VERSION ""

NS_ :

BS_:

BU_: Sound_A Ladegeraet_PAG_PF Motor_EDC17_Pirol PSM_Ant_Derivate GW_Routing_Derivate GW_Applikation_Derivate BMS_Hybrid Getriebe_Derivate LEH_Hybrid Motor_MED17_Hybrid Sound_I Tool Airbag Waehlhebel

BO_ 17 WFS_IMS_MSG1: 8 GW_Routing_Derivate
 SG_ WFS_IMS_MSG1 : 0|64@1+ (1,0) [0|1.84467440737096E+019] ""  Motor_EDC17_Pirol,Motor_MED17_Hybrid

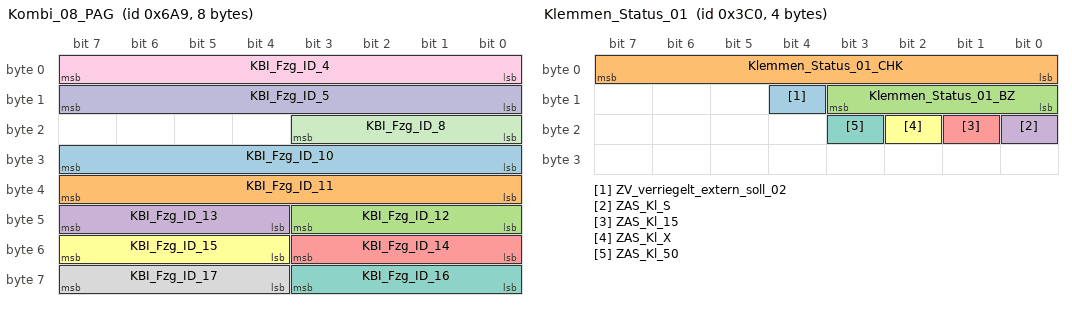
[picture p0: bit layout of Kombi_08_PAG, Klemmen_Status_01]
BO_ 1705 Kombi_08_PAG: 8 GW_Routing_Derivate
 SG_ KBI_Fzg_ID_10 : 24|8@1+ (1,0) [0|255] ""  Waehlhebel
 SG_ KBI_Fzg_ID_11 : 32|8@1+ (1,0) [0|255] ""  Waehlhebel
 SG_ KBI_Fzg_ID_12 : 40|4@1+ (1,0) [0|15] ""  Waehlhebel
 SG_ KBI_Fzg_ID_13 : 44|4@1+ (1,0) [0|15] ""  Waehlhebel
 SG_ KBI_Fzg_ID_14 : 48|4@1+ (1,0) [0|15] ""  Waehlhebel
 SG_ KBI_Fzg_ID_15 : 52|4@1+ (1,0) [0|15] ""  Waehlhebel
 SG_ KBI_Fzg_ID_16 : 56|4@1+ (1,0) [0|15] ""  Waehlhebel
 SG_ KBI_Fzg_ID_17 : 60|4@1+ (1,0) [0|15] ""  Waehlhebel
 SG_ KBI_Fzg_ID_4 : 0|8@1+ (1,0) [0|255] ""  Waehlhebel
 SG_ KBI_Fzg_ID_5 : 8|8@1+ (1,0) [0|255] ""  Waehlhebel
 SG_ KBI_Fzg_ID_8 : 16|4@1+ (1,0) [0|15] ""  Waehlhebel

BO_ 1704 Mem_Kombi_01_PAG: 8 GW_Routing_Derivate
 SG_ KBI_Steigerung_Luftmenge_Fond : 49|1@1+ (1,0) [0|1] "" Vector__XXX
 SG_ KBI_PTC_Zuheizer : 48|1@1+ (1,0) [0|1] "" Vector__XXX
 SG_ KBI_FLA_GLW_Aktiv : 6|1@1+ (1,0) [0|1] "" Vector__XXX
 SG_ KBI_ASD_innen : 44|1@1+ (1,0) [0|0] ""  Sound_I
 SG_ KBI_ASD_aussen : 7|1@1+ (1,0) [0|0] ""  Sound_A
 SG_ KBI_LDW_aktiv : 47|1@1+ (1,0) [0|1] "" Vector__XXX
 SG_ KBI_Jokerkey_Hupe_Aktiv : 46|1@1+ (1,0) [0|1] "" Vector__XXX
 SG_ KBI_Automem_inaktiv : 45|1@1+ (1,0) [0|0] "" Vector__XXX
 SG_ KBI_Heckrollo_b_R : 23|1@1+ (1,0) [0|1] "" Vector__XXX
 SG_ KBI_Klimastyles : 51|2@1+ (1,0) [0|3] "" Vector__XXX
 SG_ KBI_WV_Entr_Kof : 40|4@1+ (1,0) [0|15] "" Vector__XXX
 SG_ KBI_Carjack : 38|2@1+ (1,0) [0|3] "" Vector__XXX
 SG_ KBI_Tuerentr_T : 37|1@1+ (1,0) [0|1] "" Vector__XXX
 SG_ KBI_Einstiegshilfe_aktiv : 4|1@1+ (1,0) [0|1] "" Vector__XXX
 SG_ KBI_FULL_AFS_Tourist : 3|1@1+ (1,0) [0|1] "" Vector__XXX
 SG_ KBI_Aussenspiegel_einklapp_auto : 1|1@1+ (1,0) [0|1] "" Vector__XXX
 SG_ KBI_Aussenspiegel_absenken_auto : 0|1@1+ (1,0) [0|1] "" Vector__XXX
 SG_ KBI_Heckw_b_R : 30|2@1+ (1,0) [0|3] "" Vector__XXX
 SG_ KBI_TFL_akt : 29|1@1+ (1,0) [0|1] "" Vector__XXX
 SG_ KBI_Nachleucht : 24|5@1+ (5,0) [0|120] "s" Vector__XXX
 SG_ KBI_WV_Entr : 32|5@1+ (5,10) [10|100] "s" Vector__XXX
 SG_ KBI_Erw_BelueftFeld : 21|1@1+ (1,0) [0|1] "" Vector__XXX
 SG_ KBI_Mittenduesentemp : 53|3@1- (1,0) [-1|0] "" Vector__XXX
 SG_ KBI_Nachleucht_IL : 16|5@1+ (10,0) [0|300] "s" Vector__XXX
 SG_ KBI_Auto_Umluft : 22|1@1+ (1,0) [0|1] "" Vector__XXX
 SG_ KBI_Schaltpkt_Anz_ein : 2|1@1+ (1,0) [0|1] "" Vector__XXX
 SG_ KBI_RS_d_akt : 15|1@1+ (1,0) [0|1] "" Vector__XXX
 SG_ KBI_Dimmung_OriLicht : 8|7@1+ (1,0) [0|100] "%" Vector__XXX

BO_ 1792 ISO_Funktionaler_Req_All: 8 GW_Routing_Derivate
 SG_ Diag_Rq_Fktnl_Data_UDS : 7|64@0+ (1,0) [0|1.84467440737096E+019] ""  Ladegeraet_PAG_PF,Motor_EDC17_Pirol,Airbag,Motor_MED17_Hybrid,LEH_Hybrid,BMS_Hybrid,Getriebe_Derivate,PSM_Ant_Derivate

BO_ 1424 Kessy_02: 8 GW_Routing_Derivate
 SG_ KYL_Warn_Notzuendschloss : 46|1@1+ (1,0) [0|1] "" Vector__XXX
 SG_ KYL_Notzuendschloss : 45|1@1+ (1,0) [0|1] "" Vector__XXX
 SG_ KY_StartStopp_Info : 43|2@1+ (1,0) [0|3] ""  Motor_EDC17_Pirol,Motor_MED17_Hybrid
 SG_ KY_Funkschl_Nr : 0|4@1+ (1,0) [0|15] "" Vector__XXX
 SG_ KY_ID_Geb_autorisiert : 4|1@1+ (1,0) [0|1] "" Vector__XXX
 SG_ KY_ID_Geb_steckt : 5|1@1+ (1,0) [0|1] "" Vector__XXX
 SG_ KY_FFB_Frequenz : 6|2@1+ (1,0) [0|3] "" Vector__XXX
 SG_ KY_HF_Aktiv : 8|1@1+ (1,0) [0|1] "" Vector__XXX
 SG_ KY_LF_Aktiv : 9|1@1+ (1,0) [0|1] "" Vector__XXX
 SG_ KY_ELV_verr : 10|1@1+ (1,0) [0|1] "" Vector__XXX
 SG_ KY_ELV_entr : 11|1@1+ (1,0) [0|1] "" Vector__XXX
 SG_ KY_ELV_enable_Anforderung : 12|1@1+ (1,0) [0|1] "" Vector__XXX
 SG_ KY_Valet_Parking : 14|1@1+ (1,0) [0|1] "" Vector__XXX
 SG_ KY_Keyless_Verbau : 15|1@1+ (1,0) [0|1] "" Vector__XXX
 SG_ KY_FBS_Fahrer_Hinweise : 16|3@1+ (1,0) [0|7] "" Vector__XXX
 SG_ FBS_Warn_Lenkung_def : 19|1@1+ (1,0) [0|1] "" Vector__XXX
 SG_ FBS_Warn_LenkVerriegelung_def : 20|1@1+ (1,0) [0|1] "" Vector__XXX
 SG_ FBS_Warn_Schluessel_Batt : 21|1@1+ (1,0) [0|1] "" Vector__XXX
 SG_ FBS_Prio_Warn_04 : 22|1@1+ (1,0) [0|1] "" Vector__XXX
 SG_ FBS_Prio_Warn_05 : 23|1@1+ (1,0) [0|1] "" Vector__XXX
 SG_ KY_KYL_Fahrer_Hinweise : 24|3@1+ (1,0) [0|7] "" Vector__XXX
 SG_ KYL_Warn_kein_Schluessel : 27|1@1+ (1,0) [0|1] "" Vector__XXX
 SG_ KYL_Warn_Kessy_defekt : 28|1@1+ (1,0) [0|1] "" Vector__XXX
 SG_ KY_KYL_Prio_Warn_03 : 29|1@1+ (1,0) [0|1] "" Vector__XXX
 SG_ KY_KYL_Prio_Warn_04 : 30|1@1+ (1,0) [0|1] "" Vector__XXX
 SG_ KY_KYL_Prio_Warn_05 : 31|1@1+ (1,0) [0|1] "" Vector__XXX
 SG_ KY_Schluessel_Soll : 32|4@1+ (1,0) [0|15] "" Vector__XXX
 SG_ KY_Schluessel_Ist : 36|4@1+ (1,0) [0|15] "" Vector__XXX
 SG_ KY_WFS_Safe : 40|1@1+ (1,0) [0|1] "" Vector__XXX
 SG_ KY_WFS_LZ : 41|2@1+ (1,0) [0|3] "" Vector__XXX
 SG_ FBS_KD_Fehler : 47|1@1+ (1,0) [0|1] "" Vector__XXX
 SG_ SK_Anf_DTC_Abfrage_sofort : 49|1@1+ (1,0) [0|1] "" Vector__XXX
 SG_ SK_Anf_DTC_Abfrage : 48|1@1+ (1,0) [0|1] "" Vector__XXX

BO_ 960 Klemmen_Status_01: 4 GW_Routing_Derivate
 SG_ ZV_verriegelt_extern_soll_02 : 12|1@1+ (1,0) [0|1] "" Vector__XXX
 SG_ Klemmen_Status_01_CHK : 0|8@1+ (1,0) [0|255] ""  LEH_Hybrid,BMS_Hybrid,Motor_EDC17_Pirol,Motor_MED17_Hybrid
 SG_ Klemmen_Status_01_BZ : 8|4@1+ (1,0) [0|15] ""  LEH_Hybrid,BMS_Hybrid,Motor_EDC17_Pirol,Motor_MED17_Hybrid
 SG_ ZAS_Kl_S : 16|1@1+ (1,0) [0|1] "" Vector__XXX
 SG_ ZAS_Kl_15 : 17|1@1+ (1,0) [0|1] ""  Ladegeraet_PAG_PF,Sound_A,Sound_I,LEH_Hybrid,BMS_Hybrid,Motor_EDC17_Pirol,Motor_MED17_Hybrid
 SG_ ZAS_Kl_X : 18|1@1+ (1,0) [0|1] "" Vector__XXX
 SG_ ZAS_Kl_50 : 19|1@1+ (1,0) [0|1] ""  Sound_A,Sound_I,LEH_Hybrid,Motor_EDC17_Pirol,Waehlhebel,Motor_MED17_Hybrid,Ladegeraet_PAG_PF

BO_ 1137 Licht_hinten_01: 8 GW_Routing_Derivate
 SG_ LH_Aussenlicht_def : 7|1@1+ (1,0) [0|1] "" Vector__XXX
 SG_ LH_Standlicht_H_aktiv : 8|1@1+ (1,0) [0|1] "" Vector__XXX
 SG_ LH_SL_BRL_BLK_re_def : 42|1@1+ (1,0) [0|1] "" Vector__XXX
 SG_ LH_SL_BRL_BLK_li_def : 26|1@1+ (1,0) [0|1] "" Vector__XXX
 SG_ LH_Schluss_Nebel_re_def : 41|1@1+ (1,0) [0|1] "" Vector__XXX
 SG_ LH_Schluss_Nebel_li_def : 25|1@1+ (1,0) [0|1] "" Vector__XXX
 SG_ LH_Schluss_Brems_re_def : 40|1@1+ (1,0) [0|1] "" Vector__XXX
 SG_ LH_Schluss_Brems_Nebel_re_def : 22|1@1+ (1,0) [0|1] "" Vector__XXX
 SG_ LH_Schluss_Brems_Nebel_li_def : 21|1@1+ (1,0) [0|1] "" Vector__XXX
 SG_ LH_Schluss_Brems_li_def : 24|1@1+ (1,0) [0|1] "" Vector__XXX
 SG_ LH_Rueckfahrlicht_aktiv : 13|1@1+ (1,0) [0|1] "" Vector__XXX
 SG_ LH_Rueckf_mi_def : 51|1@1+ (1,0) [0|1] "" Vector__XXX
 SG_ LH_Parklicht_HR_aktiv : 10|1@1+ (1,0) [0|1] "" Vector__XXX
 SG_ LH_Parklicht_HL_aktiv : 9|1@1+ (1,0) [0|1] "" Vector__XXX
 SG_ LH_Nebelschluss_aktiv : 12|1@1+ (1,0) [0|1] "" Vector__XXX
 SG_ LH_Nebel_mi_def : 50|1@1+ (1,0) [0|1] "" Vector__XXX
 SG_ LH_Bremslicht_H_aktiv : 11|1@1+ (1,0) [0|1] "" Vector__XXX
 SG_ LH_Brems_Blk_re_def : 43|1@1+ (1,0) [0|1] "" Vector__XXX
 SG_ LH_Brems_Blk_li_def : 27|1@1+ (1,0) [0|1] "" Vector__XXX
 SG_ LH_Blinker_re_def : 32|1@1+ (1,0) [0|1] "" Vector__XXX
 SG_ LH_Blinker_li_def : 16|1@1+ (1,0) [0|1] "" Vector__XXX
 SG_ LH_Blinker_HR_akt : 15|1@1+ (1,0) [0|1] "" Vector__XXX
 SG_ LH_Blinker_HL_akt : 14|1@1+ (1,0) [0|1] "" Vector__XXX
 SG_ BCM2_Bremsl_durch_ECD : 5|1@1+ (1,0) [0|1] ""  Motor_EDC17_Pirol,Motor_MED17_Hybrid
 SG_ LH_Bremsl_re_ges_def : 55|1@1+ (1,0) [0|1] ""  Motor_EDC17_Pirol,Motor_MED17_Hybrid
 SG_ LH_Bremsl_li_ges_def : 54|1@1+ (1,0) [0|1] ""  Motor_EDC17_Pirol,Motor_MED17_Hybrid
 SG_ Licht_hinten_01_BZ : 0|4@1+ (1,0) [0|15] ""  Motor_EDC17_Pirol,Motor_MED17_Hybrid
 SG_ LH_Bremsl_li_def : 17|1@1+ (1,0) [0|1] "" Vector__XXX
 SG_ LH_Schlusslicht_li_def : 18|1@1+ (1,0) [0|1] "" Vector__XXX
 SG_ LH_Rueckf_li_def : 19|1@1+ (1,0) [0|1] "" Vector__XXX
 SG_ LH_Nebel_li_def : 20|1@1+ (1,0) [0|1] "" Vector__XXX
 SG_ LH_Bremsl_re_def : 33|1@1+ (1,0) [0|1] "" Vector__XXX
 SG_ LH_Schlusslicht_re_def : 34|1@1+ (1,0) [0|1] "" Vector__XXX
 SG_ LH_Rueckf_re_def : 35|1@1+ (1,0) [0|1] "" Vector__XXX
 SG_ LH_Nebel_re_def : 36|1@1+ (1,0) [0|1] "" Vector__XXX
 SG_ LH_Kennzl_def : 48|1@1+ (1,0) [0|1] "" Vector__XXX
 SG_ LH_3_Bremsl_def : 49|1@1+ (1,0) [0|1] ""  Motor_EDC17_Pirol,Motor_MED17_Hybrid

BO_ 1742 NMH_BMS: 7 BMS_Hybrid
 SG_ NMH_BMS_NL_Daten_EEPROM : 24|1@1+ (1,0) [0|1] "" Vector__XXX
 SG_ NMH_BMS_NL_Luefter : 25|1@1+ (1,0) [0|1] "" Vector__XXX
 SG_ NMH_BMS_Signalfehler : 32|1@1+ (1,0) [0|1] "" Vector__XXX
 SG_ NMH_BMS_TimeOut_Fehler : 33|1@1+ (1,0) [0|1] "" Vector__XXX
 SG_ NMH_BMS_CAN_Diag_deaktiv : 34|1@1+ (1,0) [0|1] "" Vector__XXX
 SG_ NMH_BMS_KompSchutz : 35|1@1+ (1,0) [0|1] "" Vector__XXX
 SG_ NMH_BMS_Mute_Mode : 36|1@1+ (1,0) [0|1] "" Vector__XXX
 SG_ NMH_BMS_Transport_Mode : 37|1@1+ (1,0) [0|1] "" Vector__XXX
 SG_ NMH_BMS_Abschaltstufe_aktiv : 38|1@1+ (1,0) [0|1] "" Vector__XXX
 SG_ NMH_BMS_Busfehler : 39|1@1+ (1,0) [0|1] "" Vector__XXX
 SG_ NMH_BMS_Lokalaktiv : 48|1@1+ (1,0) [0|1] "" Vector__XXX
 SG_ NMH_BMS_Subsystemaktiv : 49|1@1+ (1,0) [0|1] "" Vector__XXX
 SG_ NMH_BMS_Start_1 : 0|1@1+ (1,0) [0|1] ""  Getriebe_Derivate,LEH_Hybrid,Ladegeraet_PAG_PF,Motor_MED17_Hybrid,GW_Applikation_Derivate
 SG_ NMH_BMS_Start_2 : 1|1@1+ (1,0) [0|1] ""  GW_Applikation_Derivate
 SG_ NMH_BMS_Normal_Mode_1 : 2|1@1+ (1,0) [0|1] ""  GW_Applikation_Derivate
 SG_ NMH_BMS_Normal_Mode_2 : 3|1@1+ (1,0) [0|1] ""  GW_Applikation_Derivate
 SG_ NMH_BMS_Car_WakeUp : 6|1@1+ (1,0) [0|1] "" Vector__XXX
 SG_ NMH_BMS_Per_WakeUp : 8|5@1+ (1,0) [0|31] "" Vector__XXX
 SG_ NMH_BMS_Fkt_WakeUp : 13|3@1+ (1,0) [0|7] "" Vector__XXX
 SG_ NMH_BMS_Klemme_15 : 16|1@1+ (1,0) [0|1] "" Vector__XXX
 SG_ NMH_BMS_Diagnose : 17|1@1+ (1,0) [0|1] "" Vector__XXX
 SG_ NMH_BMS_MindestAktivZeit : 18|1@1+ (1,0) [0|1] "" Vector__XXX

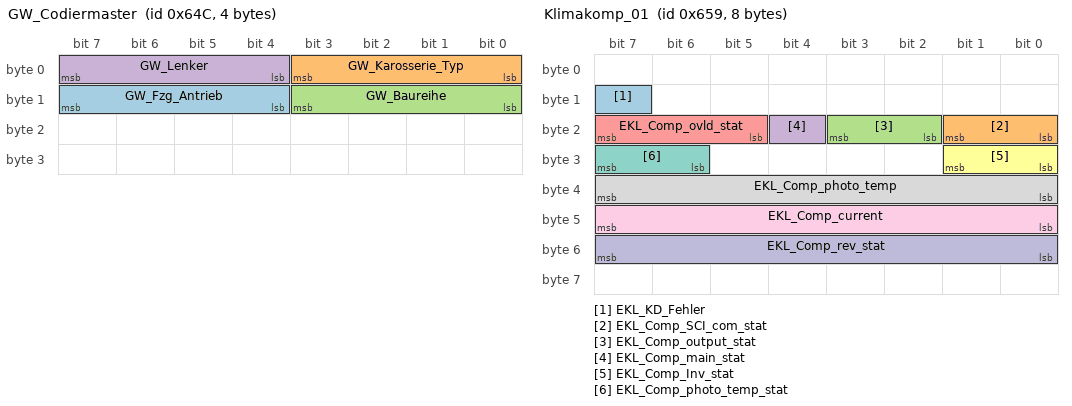
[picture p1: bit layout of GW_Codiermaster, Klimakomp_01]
BO_ 1612 GW_Codiermaster: 4 GW_Applikation_Derivate
 SG_ GW_Fzg_Antrieb : 12|4@1+ (1,0) [0|15] ""  PSM_Ant_Derivate
 SG_ GW_Karosserie_Typ : 0|4@1+ (1,0) [0|15] ""  PSM_Ant_Derivate
 SG_ GW_Baureihe : 8|4@1+ (1,0) [0|15] ""  BMS_Hybrid,PSM_Ant_Derivate
 SG_ GW_Lenker : 4|4@1+ (1,0) [0|15] ""  PSM_Ant_Derivate,Airbag

BO_ 1009 Diagnose_02_PAG: 2 GW_Applikation_Derivate
 SG_ GW_STH_Anf : 0|2@1+ (1,0) [0|3] ""  Ladegeraet_PAG_PF
 SG_ FSAktivBit : 9|1@1+ (1,0) [0|1] ""  Airbag,Waehlhebel

BO_ 1625 Klimakomp_01: 8 GW_Routing_Derivate
 SG_ EKL_KD_Fehler : 15|1@1+ (1,0) [0|1] "" Vector__XXX
 SG_ EKL_Comp_SCI_com_stat : 16|2@1+ (1,0) [0|3] "" Vector__XXX
 SG_ EKL_Comp_output_stat : 18|2@1+ (1,0) [0|3] "" Vector__XXX
 SG_ EKL_Comp_main_stat : 20|1@1+ (1,0) [0|1] "" Vector__XXX
 SG_ EKL_Comp_ovld_stat : 21|3@1+ (1,0) [0|7] "" Vector__XXX
 SG_ EKL_Comp_Inv_stat : 24|2@1+ (1,0) [0|3] "" Vector__XXX
 SG_ EKL_Comp_photo_temp_stat : 30|2@1+ (1,0) [0|3] "" Vector__XXX
 SG_ EKL_Comp_photo_temp : 32|8@1+ (1,0) [0|254] "Unit_DegreCelsi" Vector__XXX
 SG_ EKL_Comp_current : 40|8@1+ (0.1,0) [0|25.4] "Unit_Amper"  Ladegeraet_PAG_PF,Motor_MED17_Hybrid,BMS_Hybrid
 SG_ EKL_Comp_rev_stat : 48|8@1+ (50,0) [0|8600] "Unit_MinutInver"  BMS_Hybrid

BO_ 2617027073 DEV_AB_TX_02: 8 Airbag
 SG_ AB_EB2_Tx_Data : 0|64@1+ (1,0) [0|1.84467440737096E+019] "" Vector__XXX

BO_ 2617027072 DEV_AB_TX_01: 8 Airbag
 SG_ AB_EB1_Tx_Data : 0|64@1+ (1,0) [0|1.84467440737096E+019] "" Vector__XXX

BO_ 1793 ISO_Funktionaler_Req_KWP2000: 8 GW_Routing_Derivate
 SG_ Diag_Rq_Fktnl_Data_KWP2000 : 7|64@0+ (1,0) [0|1.84467440737096E+019] ""  Waehlhebel

BO_ 2015 ISO_Funktionaler_Req_OBD: 8 GW_Routing_Derivate
 SG_ Diag_Rq_Fktnl_Data_OBD : 7|64@0+ (1,0) [0|1.84467440737096E+019] ""  Ladegeraet_PAG_PF,Motor_EDC17_Pirol,Getriebe_Derivate,Motor_MED17_Hybrid,LEH_Hybrid,BMS_Hybrid

BO_ 905 GW_Ant_01: 8 GW_Routing_Derivate
 SG_ EPB_Anfahrwunsch_erkannt : 30|1@1+ (1,0) [0|1] "" Vector__XXX
 SG_ EPB_QBit_Schalterpos : 7|1@1+ (1,0) [0|1] "" Vector__XXX
 SG_ EPB_Schalterposition : 5|2@1+ (1,0) [0|3] "" Vector__XXX
 SG_ EPB_Freig_Verzoeg_Anf : 18|1@1+ (1,0) [0|1] "" Vector__XXX
 SG_ KL_Segeln_Anf_deaktivieren : 4|1@1+ (1,0) [0|1] "" Vector__XXX
 SG_ KL_T_Abgasklappe : 38|1@1+ (1,0) [0|1] "" Vector__XXX
 SG_ DK_PAO_Signalzaehler : 24|4@1+ (1,0) [0|15] ""  Airbag
 SG_ KL_St_Atemp : 32|3@1+ (1,0) [0|4] "" Vector__XXX
 SG_ KL_Komp_ein : 36|1@1+ (1,0) [0|1] "" Vector__XXX
 SG_ KL_Drehz_Anh : 37|1@1+ (1,0) [0|1] "" Vector__XXX
 SG_ KL_Anf_KL : 48|8@1+ (0.4,0) [0|100] "%" Vector__XXX
 SG_ KL_KaeltemittelDruck : 40|8@1+ (0.2,0) [0|50.8] "bar" Vector__XXX
 SG_ DK_St_PAO_Leuchte : 28|2@1+ (1,0) [0|3] ""  Airbag
 SG_ KL_Sportmodus : 19|3@1+ (1,0) [0|7] ""  PSM_Ant_Derivate
 SG_ F_EPB_01_Ant : 59|1@1+ (1,0) [0|1] "" Vector__XXX
 SG_ EPB_Status : 16|2@1+ (1,0) [0|3] "" Vector__XXX
 SG_ F_Klima_03_Ant : 62|1@1+ (1,0) [0|1] "" Vector__XXX
 SG_ KL_Magnetventil : 35|1@1+ (1,0) [0|1] "" Vector__XXX
 SG_ KL_T_PSM_off : 3|1@1+ (1,0) [0|1] ""  PSM_Ant_Derivate
 SG_ KL_F_Komp_Endst : 39|1@1+ (1,0) [0|1] "" Vector__XXX
 SG_ F_Klima_01_1_Ant : 60|1@1+ (1,0) [0|1] "" Vector__XXX
 SG_ F_Klima_08_1_PAG_Ant : 63|1@1+ (1,0) [0|1] ""  PSM_Ant_Derivate
 SG_ F_BCM2_03_PAG_Ant : 57|1@1+ (1,0) [0|1] ""  Airbag
 SG_ KL_Last_Kompr : 8|8@1+ (0.25,0) [0|63.5] "Nm" Vector__XXX
 SG_ KL_STH_Ansteuerung : 1|2@1+ (1,0) [0|3] "" Vector__XXX
 SG_ KL_STH_aktiv : 0|1@1+ (1,0) [0|1] "" Vector__XXX
 SG_ EPB_Fehlerstatus : 22|2@1+ (1,0) [0|3] "" Vector__XXX

BO_ 18 GSG_WFS_Anfrage: 8 Getriebe_Derivate
 SG_ WFS_GSG_RND : 0|32@1+ (1,0) [0|4294967295] "" Vector__XXX
 SG_ WFS_GSG_CRC : 32|32@1+ (1,0) [0|4294967295] "" Vector__XXX

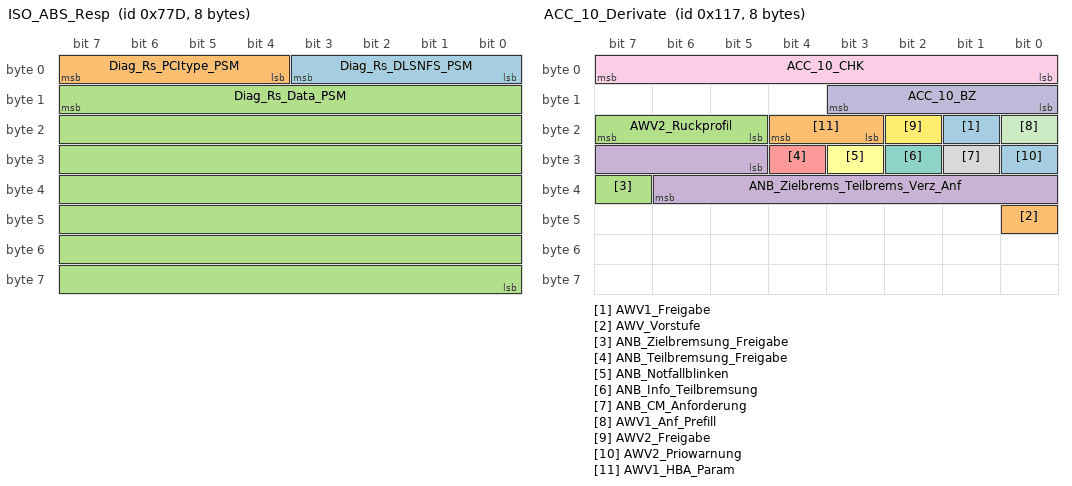
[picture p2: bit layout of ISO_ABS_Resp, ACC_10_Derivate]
BO_ 1917 ISO_ABS_Resp: 8 PSM_Ant_Derivate
 SG_ Diag_Rs_DLSNFS_PSM : 3|4@0+ (1,0) [0|15] ""  GW_Routing_Derivate
 SG_ Diag_Rs_PCItype_PSM : 7|4@0+ (1,0) [0|15] ""  GW_Routing_Derivate
 SG_ Diag_Rs_Data_PSM : 15|56@0+ (1,0) [0|7.20575940379279E+016] ""  GW_Routing_Derivate

BO_ 2025 ISO_Getriebe_01_Resp: 8 Getriebe_Derivate
 SG_ ISO_Getriebe_01_Resp_Data : 0|64@1+ (1,0) [0|1.84467440737096E+019] ""  GW_Routing_Derivate

BO_ 2024 ISO_MO_01_Resp: 8 Motor_MED17_Hybrid
 SG_ ISO_MO_01_Resp_Data : 0|64@1+ (1,0) [0|1.84467440737096E+019] ""  GW_Routing_Derivate

BO_ 279 ACC_10_Derivate: 8 GW_Routing_Derivate
 SG_ AWV1_Freigabe : 17|1@1+ (1,0) [0|1] ""  PSM_Ant_Derivate
 SG_ AWV_Vorstufe : 40|1@1+ (1,0) [0|1] ""  PSM_Ant_Derivate
 SG_ ANB_Zielbremsung_Freigabe : 39|1@1+ (1,0) [0|1] ""  PSM_Ant_Derivate
 SG_ ANB_Zielbrems_Teilbrems_Verz_Anf : 29|10@1+ (0.024,-20.016) [-20.016|4.536] "Unit_MeterPerSeconSquar"  PSM_Ant_Derivate
 SG_ ANB_Teilbremsung_Freigabe : 28|1@1+ (1,0) [0|1] ""  PSM_Ant_Derivate
 SG_ ANB_Notfallblinken : 27|1@1+ (1,0) [0|1] ""  PSM_Ant_Derivate
 SG_ ANB_Info_Teilbremsung : 26|1@1+ (1,0) [0|1] ""  PSM_Ant_Derivate
 SG_ ANB_CM_Anforderung : 25|1@1+ (1,0) [0|1] "" Vector__XXX
 SG_ ACC_10_CHK : 0|8@1+ (1,0) [0|255] ""  PSM_Ant_Derivate
 SG_ ACC_10_BZ : 8|4@1+ (1,0) [0|15] ""  PSM_Ant_Derivate
 SG_ AWV1_Anf_Prefill : 16|1@1+ (1,0) [0|1] ""  PSM_Ant_Derivate
 SG_ AWV2_Freigabe : 18|1@1+ (1,0) [0|1] ""  PSM_Ant_Derivate
 SG_ AWV2_Priowarnung : 24|1@1+ (1,0) [0|1] ""  PSM_Ant_Derivate
 SG_ AWV1_HBA_Param : 19|2@1+ (1,0) [0|3] ""  PSM_Ant_Derivate
 SG_ AWV2_Ruckprofil : 21|3@1+ (1,0) [0|7] ""  PSM_Ant_Derivate

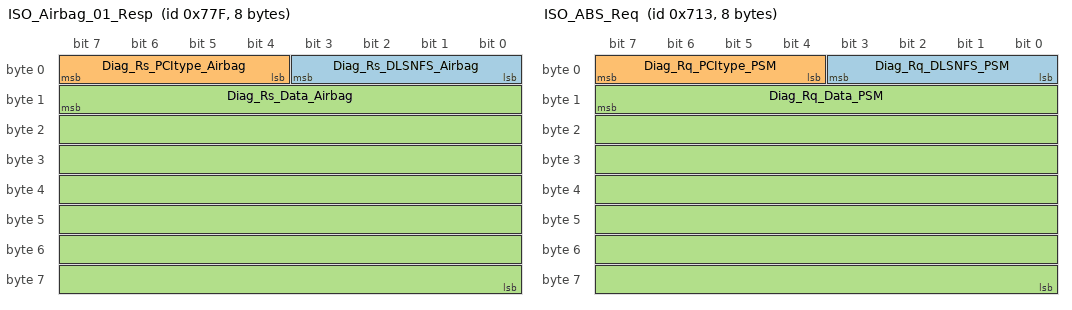
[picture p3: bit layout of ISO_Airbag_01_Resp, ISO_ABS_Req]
BO_ 1919 ISO_Airbag_01_Resp: 8 Airbag
 SG_ Diag_Rs_DLSNFS_Airbag : 3|4@0+ (1,0) [0|15] ""  GW_Routing_Derivate
 SG_ Diag_Rs_PCItype_Airbag : 7|4@0+ (1,0) [0|15] ""  GW_Routing_Derivate
 SG_ Diag_Rs_Data_Airbag : 15|56@0+ (1,0) [0|7.20575940379279E+016] ""  GW_Routing_Derivate

BO_ 1811 ISO_ABS_Req: 8 GW_Routing_Derivate
 SG_ Diag_Rq_DLSNFS_PSM : 3|4@0+ (1,0) [0|15] ""  PSM_Ant_Derivate
 SG_ Diag_Rq_PCItype_PSM : 7|4@0+ (1,0) [0|15] ""  PSM_Ant_Derivate
 SG_ Diag_Rq_Data_PSM : 15|56@0+ (1,0) [0|7.20575940379279E+016] ""  PSM_Ant_Derivate

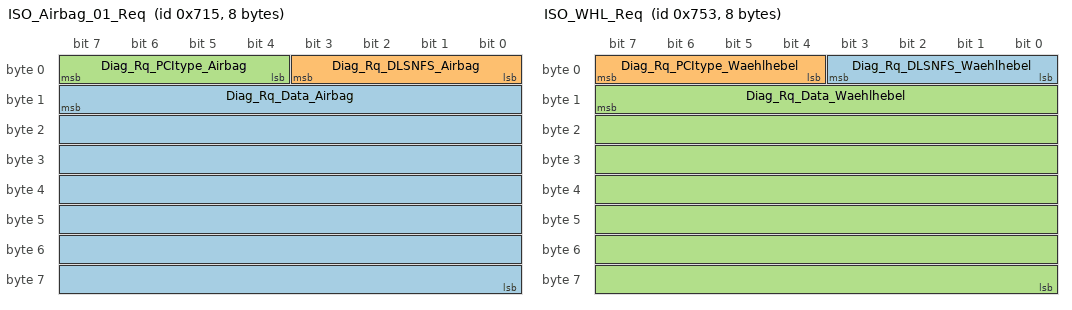
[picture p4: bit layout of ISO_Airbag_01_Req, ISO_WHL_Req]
BO_ 1813 ISO_Airbag_01_Req: 8 GW_Routing_Derivate
 SG_ Diag_Rq_Data_Airbag : 15|56@0+ (1,0) [0|7.20575940379279E+016] ""  Airbag
 SG_ Diag_Rq_DLSNFS_Airbag : 3|4@0+ (1,0) [0|15] ""  Airbag
 SG_ Diag_Rq_PCItype_Airbag : 7|4@0+ (1,0) [0|15] ""  Airbag

BO_ 1875 ISO_WHL_Req: 8 GW_Routing_Derivate
 SG_ Diag_Rq_DLSNFS_Waehlhebel : 3|4@0+ (1,0) [0|15] ""  Waehlhebel
 SG_ Diag_Rq_PCItype_Waehlhebel : 7|4@0+ (1,0) [0|15] ""  Waehlhebel
 SG_ Diag_Rq_Data_Waehlhebel : 15|56@0+ (1,0) [0|7.20575940379279E+016] ""  Waehlhebel

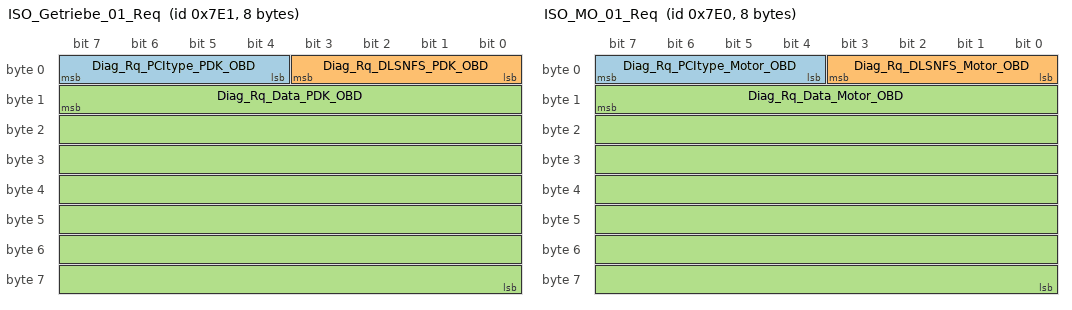
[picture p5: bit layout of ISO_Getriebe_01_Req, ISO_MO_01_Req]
BO_ 2017 ISO_Getriebe_01_Req: 8 GW_Routing_Derivate
 SG_ Diag_Rq_PCItype_PDK_OBD : 7|4@0+ (1,0) [0|15] ""  Getriebe_Derivate
 SG_ Diag_Rq_DLSNFS_PDK_OBD : 3|4@0+ (1,0) [0|15] ""  Getriebe_Derivate
 SG_ Diag_Rq_Data_PDK_OBD : 15|56@0+ (1,0) [0|7.20575940379279E+016] ""  Getriebe_Derivate

BO_ 2016 ISO_MO_01_Req: 8 GW_Routing_Derivate
 SG_ Diag_Rq_PCItype_Motor_OBD : 7|4@0+ (1,0) [0|15] ""  Motor_EDC17_Pirol,Motor_MED17_Hybrid
 SG_ Diag_Rq_DLSNFS_Motor_OBD : 3|4@0+ (1,0) [0|15] ""  Motor_EDC17_Pirol,Motor_MED17_Hybrid
 SG_ Diag_Rq_Data_Motor_OBD : 15|56@0+ (1,0) [0|7.20575940379279E+016] ""  Motor_EDC17_Pirol,Motor_MED17_Hybrid

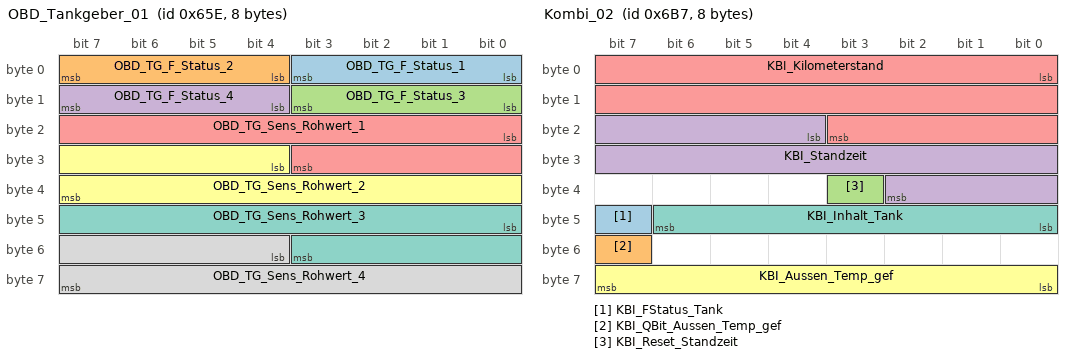
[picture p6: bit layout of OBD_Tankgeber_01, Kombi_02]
BO_ 1630 OBD_Tankgeber_01: 8 GW_Routing_Derivate
 SG_ OBD_TG_F_Status_1 : 0|4@1+ (1,0) [0|15] ""  Motor_MED17_Hybrid
 SG_ OBD_TG_F_Status_2 : 4|4@1+ (1,0) [0|15] ""  Motor_MED17_Hybrid
 SG_ OBD_TG_F_Status_3 : 8|4@1+ (1,0) [0|15] ""  Motor_MED17_Hybrid
 SG_ OBD_TG_F_Status_4 : 12|4@1+ (1,0) [0|15] ""  Motor_MED17_Hybrid
 SG_ OBD_TG_Sens_Rohwert_1 : 16|12@1+ (0.5,0) [0|2047.5] "Unit_Ohm"  Motor_MED17_Hybrid
 SG_ OBD_TG_Sens_Rohwert_2 : 28|12@1+ (0.5,0) [0|2047.5] "Unit_Ohm"  Motor_MED17_Hybrid
 SG_ OBD_TG_Sens_Rohwert_3 : 40|12@1+ (0.5,0) [0|2047.5] "Unit_Ohm"  Motor_MED17_Hybrid
 SG_ OBD_TG_Sens_Rohwert_4 : 52|12@1+ (0.5,0) [0|2047.5] "Unit_Ohm"  Motor_MED17_Hybrid

BO_ 1607 Motor_09_VW: 8 Motor_MED17_Hybrid
 SG_ MO_Kraftstofffilter_Wasser : 40|1@1+ (1,0) [0|1] ""  GW_Routing_Derivate
 SG_ MO_ITM_Kuehlmittel_Temp : 0|8@1+ (0.75,-48) [-45.75|143.25] "Unit_DegreCelsi"  GW_Routing_Derivate
 SG_ MO_CO2_Faktor : 44|12@1+ (1,0) [1|4094] "Unit_GramPerLiter"  GW_Routing_Derivate
 SG_ MO_E85_Sensor : 8|4@1+ (1,0) [0|10] "Unit_PerCent"  GW_Routing_Derivate
 SG_ SCR_Anz_Motorstarts : 12|4@1+ (1,0) [0|8] ""  GW_Routing_Derivate
 SG_ SCR_Reichweite : 16|15@1+ (1,0) [0|32766] ""  GW_Routing_Derivate
 SG_ SCR_Warnstufe_1 : 32|1@1+ (1,0) [0|1] ""  GW_Routing_Derivate
 SG_ SCR_Warnstufe_2 : 33|1@1+ (1,0) [0|1] ""  GW_Routing_Derivate
 SG_ SCR_Inducement_Strategie : 42|2@1+ (1,0) [0|3] ""  GW_Routing_Derivate
 SG_ MO_MKB_MUX M : 56|2@1+ (1,0) [0|3] ""  GW_Routing_Derivate
 SG_ MO_MKB_01 m0 : 59|5@1+ (1,0) [0|31] ""  GW_Routing_Derivate
 SG_ MO_MKB_02 m1 : 59|5@1+ (1,0) [0|31] ""  GW_Routing_Derivate
 SG_ SCR_Text : 34|3@1+ (1,0) [0|7] ""  GW_Routing_Derivate
 SG_ SCR_Akustik : 37|2@1+ (1,0) [0|3] ""  GW_Routing_Derivate
 SG_ SCR_Systemfehler : 41|1@1+ (1,0) [0|1] ""  GW_Routing_Derivate
 SG_ MO_MKB_04 m3 : 59|5@1+ (1,0) [0|31] ""  GW_Routing_Derivate
 SG_ MO_MKB_03 m2 : 59|5@1+ (1,0) [0|31] ""  GW_Routing_Derivate

BO_ 269 ACC_05: 8 GW_Routing_Derivate
 SG_ ACC_Vorbefuellung_Bremsanlage : 47|1@1+ (1,0) [0|1] "" Vector__XXX
 SG_ ACC_StartStopp_Info : 44|2@1+ (1,0) [0|3] ""  Motor_MED17_Hybrid,Motor_EDC17_Pirol
 SG_ ACC_KD_Fehler : 63|1@1+ (1,0) [0|1] "" Vector__XXX
 SG_ ACC_Anhalten : 62|1@1+ (1,0) [0|1] ""  PSM_Ant_Derivate
 SG_ ACC_Beeinflussung_ESP : 61|1@1+ (1,0) [0|1] "" Vector__XXX
 SG_ ACC_Betaetigung_EPB : 60|1@1+ (1,0) [0|1] ""  Motor_EDC17_Pirol,Motor_MED17_Hybrid
 SG_ ACC_Status_ACC : 57|3@1+ (1,0) [0|7] ""  Getriebe_Derivate,Motor_MED17_Hybrid,Motor_EDC17_Pirol
 SG_ ACC_ax_Getriebe : 48|9@1+ (0.024,-2.016) [-2.016|10.248] "Unit_MeterPerSeconSquar"  Getriebe_Derivate
 SG_ ACC_Loeseanforderung : 43|1@1+ (1,0) [0|1] ""  PSM_Ant_Derivate
 SG_ ACC_Verz_anf : 32|11@1+ (0.005,-7.22) [-7.22|3.015] "Unit_MeterPerSeconSquar"  PSM_Ant_Derivate
 SG_ ACC_zul_Regelabw : 26|6@1+ (0.024,0) [0|1.512] "Unit_MeterPerSeconSquar" Vector__XXX
 SG_ ACC_Momentenanforderung : 16|10@1+ (1,0) [0|1021] ""  Motor_MED17_Hybrid,Motor_EDC17_Pirol
 SG_ ACC_limitierte_Anfahrdyn : 15|1@1+ (1,0) [0|1] ""  Motor_EDC17_Pirol,Motor_MED17_Hybrid
 SG_ ACC_Getriebestellung_P : 14|1@1+ (1,0) [0|1] "" Vector__XXX
 SG_ ACC_Freigabe_Verzanf : 13|1@1+ (1,0) [0|1] ""  Getriebe_Derivate
 SG_ ACC_Freigabe_Momentenanf : 12|1@1+ (1,0) [0|1] ""  Motor_EDC17_Pirol,Motor_MED17_Hybrid
 SG_ ACC_05_CHK : 0|8@1+ (1,0) [0|255] ""  Motor_EDC17_Pirol,PSM_Ant_Derivate,Getriebe_Derivate,Motor_MED17_Hybrid
 SG_ ACC_05_BZ : 8|4@1+ (1,0) [0|15] ""  Motor_EDC17_Pirol,PSM_Ant_Derivate,Getriebe_Derivate,Motor_MED17_Hybrid

BO_ 1719 Kombi_02: 8 GW_Routing_Derivate
 SG_ KBI_FStatus_Tank : 47|1@1+ (1,0) [0|1] ""  Motor_EDC17_Pirol,Motor_MED17_Hybrid
 SG_ KBI_QBit_Aussen_Temp_gef : 55|1@1+ (1,0) [0|1] ""  Motor_EDC17_Pirol,Motor_MED17_Hybrid,BMS_Hybrid
 SG_ KBI_Reset_Standzeit : 35|1@1+ (1,0) [0|1] ""  Motor_EDC17_Pirol,Motor_MED17_Hybrid
 SG_ KBI_Standzeit : 20|15@1+ (4,0) [0|131068] "Unit_Seconds"  Motor_EDC17_Pirol,Motor_MED17_Hybrid
 SG_ KBI_Kilometerstand : 0|20@1+ (1,0) [0|1048573] "km"  Getriebe_Derivate
 SG_ KBI_Aussen_Temp_gef : 56|8@1+ (0.5,-50) [-50|75] "°C"  Motor_EDC17_Pirol,Motor_MED17_Hybrid,BMS_Hybrid
 SG_ KBI_Inhalt_Tank : 40|7@1+ (1,0) [0|126] "Liter"  Motor_EDC17_Pirol,Motor_MED17_Hybrid

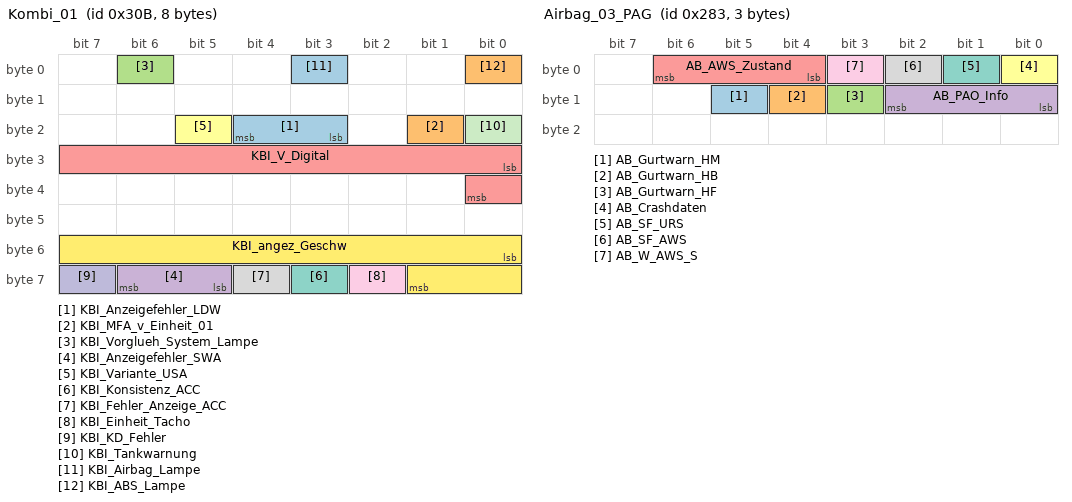
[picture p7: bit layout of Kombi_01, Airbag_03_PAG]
BO_ 779 Kombi_01: 8 GW_Routing_Derivate
 SG_ KBI_Anzeigefehler_LDW : 19|2@1+ (1,0) [0|3] "" Vector__XXX
 SG_ KBI_MFA_v_Einheit_01 : 17|1@1+ (1,0) [0|1] "" Vector__XXX
 SG_ KBI_Vorglueh_System_Lampe : 6|1@1+ (1,0) [0|1] ""  Motor_EDC17_Pirol
 SG_ KBI_Anzeigefehler_SWA : 61|2@1+ (1,0) [0|3] "" Vector__XXX
 SG_ KBI_V_Digital : 24|9@1+ (1,0) [0|511] "" Vector__XXX
 SG_ KBI_Variante_USA : 21|1@1+ (1,0) [0|1] "" Vector__XXX
 SG_ KBI_Konsistenz_ACC : 59|1@1+ (1,0) [0|1] "" Vector__XXX
 SG_ KBI_Fehler_Anzeige_ACC : 60|1@1+ (1,0) [0|1] ""  Motor_EDC17_Pirol,Motor_MED17_Hybrid
 SG_ KBI_Einheit_Tacho : 58|1@1+ (1,0) [0|1] ""  Motor_EDC17_Pirol,Motor_MED17_Hybrid
 SG_ KBI_KD_Fehler : 63|1@1+ (1,0) [0|1] "" Vector__XXX
 SG_ KBI_Tankwarnung : 16|1@1+ (1,0) [0|1] ""  Motor_EDC17_Pirol,Motor_MED17_Hybrid
 SG_ KBI_angez_Geschw : 48|10@1+ (0.32,0) [0|325] "km/h"  Motor_EDC17_Pirol,Getriebe_Derivate,Motor_MED17_Hybrid
 SG_ KBI_Airbag_Lampe : 3|1@1+ (1,0) [0|1] "" Vector__XXX
 SG_ KBI_ABS_Lampe : 0|1@1+ (1,0) [0|1] "" Vector__XXX

BO_ 643 Airbag_03_PAG: 3 Airbag
 SG_ AB_Gurtwarn_HM : 13|1@1+ (1,0) [0|1] ""  GW_Routing_Derivate
 SG_ AB_Gurtwarn_HB : 12|1@1+ (1,0) [0|1] ""  GW_Routing_Derivate
 SG_ AB_Gurtwarn_HF : 11|1@1+ (1,0) [0|1] ""  GW_Routing_Derivate
 SG_ AB_PAO_Info : 8|3@1+ (1,0) [0|7] ""  GW_Routing_Derivate
 SG_ AB_AWS_Zustand : 4|3@1+ (1,0) [0|7] ""  GW_Routing_Derivate
 SG_ AB_Crashdaten : 0|1@1+ (1,0) [0|1] ""  GW_Routing_Derivate
 SG_ AB_SF_URS : 1|1@1+ (1,0) [0|1] ""  GW_Routing_Derivate
 SG_ AB_SF_AWS : 2|1@1+ (1,0) [0|1] ""  GW_Routing_Derivate
 SG_ AB_W_AWS_S : 3|1@1+ (1,0) [0|1] ""  GW_Routing_Derivate

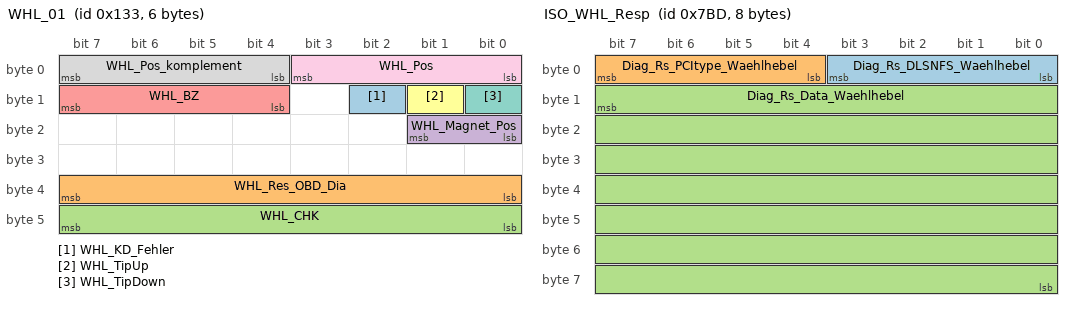
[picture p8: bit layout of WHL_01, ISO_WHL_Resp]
BO_ 307 WHL_01: 6 Waehlhebel
 SG_ WHL_KD_Fehler : 10|1@1+ (1,0) [0|1] ""  GW_Applikation_Derivate
 SG_ WHL_Res_OBD_Dia : 32|8@1+ (1,0) [0|255] "" Vector__XXX
 SG_ WHL_CHK : 40|8@1+ (1,0) [0|255] "" Vector__XXX
 SG_ WHL_Magnet_Pos : 16|2@1+ (1,0) [0|3] ""  Getriebe_Derivate
 SG_ WHL_BZ : 12|4@1+ (1,0) [0|15] ""  Getriebe_Derivate
 SG_ WHL_TipUp : 9|1@1+ (1,0) [0|1] ""  Getriebe_Derivate
 SG_ WHL_TipDown : 8|1@1+ (1,0) [0|1] ""  Getriebe_Derivate
 SG_ WHL_Pos_komplement : 4|4@1+ (1,0) [0|15] ""  Getriebe_Derivate
 SG_ WHL_Pos : 0|4@1+ (1,0) [0|15] ""  Ladegeraet_PAG_PF,Getriebe_Derivate

BO_ 1315 GW_SVB: 8 GW_Applikation_Derivate
 SG_ SVB_Aero : 15|1@1+ (1,0) [0|1] "" Vector__XXX
 SG_ SVB_SCR : 37|1@1+ (1,0) [0|1] "" Vector__XXX
 SG_ SVB_LEH_VA : 26|1@1+ (1,0) [0|1] "" Vector__XXX
 SG_ SVB_Ladegeraet : 27|1@1+ (1,0) [0|1] "" Vector__XXX
 SG_ SVB_EBKV : 46|1@1+ (1,0) [0|1] "" Vector__XXX
 SG_ SVB_ComBox : 25|1@1+ (1,0) [0|1] "" Vector__XXX
 SG_ SVB_Lift : 4|1@1+ (1,0) [0|1] "" Vector__XXX
 SG_ SVB_HAL : 45|1@1+ (1,0) [0|1] "" Vector__XXX
 SG_ SVB_Topview : 14|1@1+ (1,0) [0|1] "" Vector__XXX
 SG_ SVB_Kamera : 55|1@1+ (1,0) [0|1] "" Vector__XXX
 SG_ SVB_AFS : 47|1@1+ (1,0) [0|1] "" Vector__XXX
 SG_ SVB_TSG_HR : 12|1@1+ (1,0) [0|1] "" Vector__XXX
 SG_ SVB_CDR : 23|1@1+ (1,0) [0|1] "" Vector__XXX
 SG_ SVB_Stoppuhr : 21|1@1+ (1,0) [0|1] "" Vector__XXX
 SG_ SVB_SWR : 49|1@1+ (1,0) [0|1] "" Vector__XXX
 SG_ SVB_HDSG : 3|1@1+ (1,0) [0|1] "" Vector__XXX
 SG_ SVB_PDCC : 40|1@1+ (1,0) [0|1] ""  PSM_Ant_Derivate
 SG_ SVB_EPB : 38|1@1+ (1,0) [0|1] ""  PSM_Ant_Derivate
 SG_ SVB_QSP : 29|1@1+ (1,0) [0|1] ""  PSM_Ant_Derivate
 SG_ SVB_PSM_Fwk : 34|1@1+ (1,0) [0|1] "" Vector__XXX
 SG_ SVB_EPS : 44|1@1+ (1,0) [0|1] "" Vector__XXX
 SG_ SVB_VSG : 13|1@1+ (1,0) [0|1] "" Vector__XXX
 SG_ SVB_Allrad : 43|1@1+ (1,0) [0|1] "" Vector__XXX
 SG_ SVB_TSG_HL : 11|1@1+ (1,0) [0|1] "" Vector__XXX
 SG_ SVB_SWL : 48|1@1+ (1,0) [0|1] "" Vector__XXX
 SG_ SVB_SSC : 39|1@1+ (1,0) [0|1] "" Vector__XXX
 SG_ SVB_MEM_FS : 0|1@1+ (1,0) [0|1] "" Vector__XXX
 SG_ SVB_MEM_BFS : 1|1@1+ (1,0) [0|1] "" Vector__XXX
 SG_ SVB_WHL : 31|1@1+ (1,0) [0|1] "" Vector__XXX
 SG_ SVB_TSG_BT : 7|1@1+ (1,0) [0|1] "" Vector__XXX
 SG_ SVB_TSG_FT : 6|1@1+ (1,0) [0|1] "" Vector__XXX
 SG_ SVB_AMP : 57|1@1+ (1,0) [0|1] "" Vector__XXX
 SG_ SVB_BCM2 : 10|1@1+ (1,0) [0|1] "" Vector__XXX
 SG_ SVB_BCM1 : 9|1@1+ (1,0) [0|1] "" Vector__XXX
 SG_ SVB_RDK : 8|1@1+ (1,0) [0|1] "" Vector__XXX
 SG_ SVB_PCM : 22|1@1+ (1,0) [0|1] "" Vector__XXX
 SG_ SVB_Motor : 28|1@1+ (1,0) [0|1] "" Vector__XXX
 SG_ SVB_TV : 58|1@1+ (1,0) [0|1] "" Vector__XXX
 SG_ SVB_LWS : 41|1@1+ (1,0) [0|1] "" Vector__XXX
 SG_ SVB_SMLS : 2|1@1+ (1,0) [0|1] "" Vector__XXX
 SG_ SVB_Kombi : 16|1@1+ (1,0) [0|1] "" Vector__XXX
 SG_ SVB_RearView : 20|1@1+ (1,0) [0|1] "" Vector__XXX
 SG_ SVB_ACC : 50|1@1+ (1,0) [0|1] ""  PSM_Ant_Derivate
 SG_ SVB_PDK : 30|1@1+ (1,0) [0|1] ""  PSM_Ant_Derivate
 SG_ SVB_AAG : 5|1@1+ (1,0) [0|1] ""  PSM_Ant_Derivate
 SG_ SVB_PSM_Ant : 33|1@1+ (1,0) [0|1] "" Vector__XXX
 SG_ SVB_BKE : 17|1@1+ (1,0) [0|1] "" Vector__XXX
 SG_ SVB_PASM_NRA : 42|1@1+ (1,0) [0|1] ""  PSM_Ant_Derivate
 SG_ SVB_STH : 19|1@1+ (1,0) [0|1] "" Vector__XXX
 SG_ SVB_Airbag : 32|1@1+ (1,0) [0|1] "" Vector__XXX
 SG_ SVB_PDC : 18|1@1+ (1,0) [0|1] "" Vector__XXX
 SG_ SVB_SWA : 51|1@1+ (1,0) [0|1] "" Vector__XXX
 SG_ SVB_Kompass : 24|1@1+ (1,0) [0|1] "" Vector__XXX
 SG_ SVB_EKK : 54|1@1+ (1,0) [0|1] "" Vector__XXX
 SG_ SVB_EHPS : 53|1@1+ (1,0) [0|1] "" Vector__XXX
 SG_ SVB_LEH : 36|1@1+ (1,0) [0|1] "" Vector__XXX
 SG_ SVB_BMS : 35|1@1+ (1,0) [0|1] "" Vector__XXX

BO_ 390 Bremse_01: 8 GW_Routing_Derivate
 SG_ BR_StartStopp_Info : 14|2@1+ (1,0) [0|3] "" Vector__XXX
 SG_ BR_W_PDCC_Notlauf : 18|1@1+ (1,0) [0|1] "" Vector__XXX
 SG_ BR_KD_Fehler : 23|1@1+ (1,0) [0|1] "" Vector__XXX
 SG_ BR_St_Notbrems : 19|1@1+ (1,0) [0|1] "" Vector__XXX
 SG_ BR_Notbrems_verf : 22|1@1+ (1,0) [0|1] "" Vector__XXX
 SG_ BR_W_PTM_Temp : 13|1@1+ (1,0) [0|1] "" Vector__XXX
 SG_ BR_F_Sport : 21|1@1+ (1,0) [0|1] "" Vector__XXX
 SG_ BR_St_esp_dia : 16|1@1+ (1,0) [0|1] "" Vector__XXX
 SG_ BR_mimsr : 56|8@1+ (0.39,0) [0|99.45] "%" Vector__XXX
 SG_ BR_miasrs : 48|8@1+ (0.39,0) [0|99.45] "%" Vector__XXX
 SG_ BR_miasrl : 40|8@1+ (0.39,0) [0|99.45] "%" Vector__XXX
 SG_ BR_St_esp_pas : 17|1@1+ (1,0) [0|1] "" Vector__XXX
 SG_ BR_St_msr : 1|1@1+ (1,0) [0|1] "" Vector__XXX
 SG_ BR_F_esp : 9|1@1+ (1,0) [0|1] "" Vector__XXX
 SG_ BR_St_esp_info : 7|1@1+ (1,0) [0|1] "" Vector__XXX
 SG_ BR_St_esp : 4|1@1+ (1,0) [0|1] "" Vector__XXX
 SG_ BR_F_ebv : 10|1@1+ (1,0) [0|1] "" Vector__XXX
 SG_ BR_S_BremsT : 12|1@1+ (1,0) [0|1] "" Vector__XXX
 SG_ BR_S_BremsL : 11|1@1+ (1,0) [0|1] "" Vector__XXX
 SG_ BR_St_asr : 0|1@1+ (1,0) [0|1] "" Vector__XXX
 SG_ BR_F_abs : 8|1@1+ (1,0) [0|1] "" Vector__XXX
 SG_ BR_St_abs : 2|1@1+ (1,0) [0|1] "" Vector__XXX
 SG_ BR_St_bmr : 3|1@1+ (1,0) [0|1] "" Vector__XXX
 SG_ BR_asrb : 5|1@1+ (1,0) [0|1] "" Vector__XXX
 SG_ BR_W_QSP_Temp : 6|1@1+ (1,0) [0|1] "" Vector__XXX
 SG_ BR_St_Rollenmodus : 20|1@1+ (1,0) [0|1] "" Vector__XXX
 SG_ ESP_v_Signal : 24|16@1+ (0.01,0) [0|655.32] "km/h"  Sound_A,Sound_I,Airbag

BO_ 1981 ISO_WHL_Resp: 8 Waehlhebel
 SG_ Diag_Rs_DLSNFS_Waehlhebel : 3|4@0+ (1,0) [0|15] ""  GW_Routing_Derivate
 SG_ Diag_Rs_PCItype_Waehlhebel : 7|4@0+ (1,0) [0|15] ""  GW_Routing_Derivate
 SG_ Diag_Rs_Data_Waehlhebel : 15|56@0+ (1,0) [0|7.20575940379279E+016] ""  GW_Routing_Derivate

BO_ 910 GW_Ant_03: 8 GW_Routing_Derivate
 SG_ AAG_Bremslicht_H_def : 62|1@1+ (1,0) [0|1] "" Vector__XXX
 SG_ KBI_Fehler_Anzeige_ACC : 35|1@1+ (1,0) [0|1] "" Vector__XXX
 SG_ KBI_Einheit_Tacho : 34|1@1+ (1,0) [0|1] "" Vector__XXX
 SG_ KBI_angez_Geschw : 24|10@1+ (0.32,0) [0|325] "km/h" Vector__XXX
 SG_ F_Kombi_02_Ant : 56|1@1+ (1,0) [0|1] "" Vector__XXX
 SG_ KBI_Aussen_Temp_gef : 0|8@1+ (0.5,-50) [-50|75] "°C" Vector__XXX
 SG_ KBI_Inhalt_Tank : 40|7@1+ (1,0) [0|126] "Liter" Vector__XXX
 SG_ F_Kombi_11_PAG_Ant : 58|1@1+ (1,0) [0|1] ""  Airbag
 SG_ KBI_L_Tempo_ok : 37|1@1+ (1,0) [0|1] "" Vector__XXX
 SG_ KBI_L_CheckE_ok : 36|1@1+ (1,0) [0|1] "" Vector__XXX
 SG_ F_Klima_08_PAG_Ant : 57|1@1+ (1,0) [0|1] ""  Airbag
 SG_ KL_Atemp_ungef : 8|8@1+ (0.5,-50) [-49.5|77] "°C"  Airbag
 SG_ KBI_Tankwarnung : 47|1@1+ (1,0) [0|1] "" Vector__XXX
 SG_ F_Kombi_01_Ant : 60|1@1+ (1,0) [0|1] ""  Airbag
 SG_ KBI_ABS_Lampe : 39|1@1+ (1,0) [0|1] "" Vector__XXX
 SG_ KBI_Airbag_Lampe : 38|1@1+ (1,0) [0|1] ""  Airbag
 SG_ KBI_Fotosensor : 48|8@1+ (0.1,0) [0|25.4] "W/m²"  Airbag
 SG_ F_Anhaenger_01_Ant : 59|1@1+ (1,0) [0|1] "" Vector__XXX
 SG_ AAG_Anhaenger_erkannt : 63|1@1+ (1,0) [0|1] "" Vector__XXX

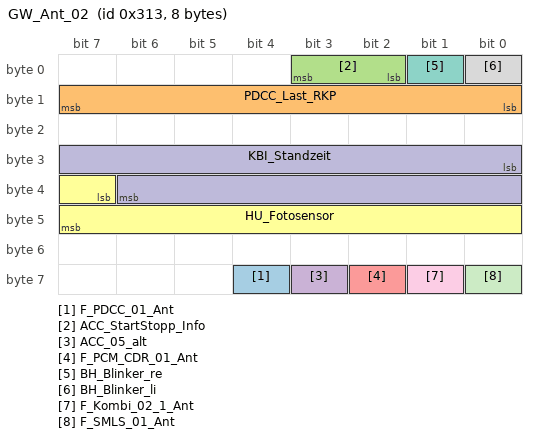
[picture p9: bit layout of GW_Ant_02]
BO_ 787 GW_Ant_02: 8 GW_Routing_Derivate
 SG_ F_PDCC_01_Ant : 60|1@1+ (1,0) [0|1] "" Vector__XXX
 SG_ PDCC_Last_RKP : 8|8@1+ (0.25,0) [0|63.5] "Nm" Vector__XXX
 SG_ ACC_StartStopp_Info : 2|2@1+ (1,0) [0|3] "" Vector__XXX
 SG_ ACC_05_alt : 59|1@1+ (1,0) [0|1] "" Vector__XXX
 SG_ F_PCM_CDR_01_Ant : 58|1@1+ (1,0) [0|1] ""  Airbag
 SG_ HU_Fotosensor : 39|9@1+ (0.25,0) [0|100] "%"  Airbag
 SG_ BH_Blinker_re : 1|1@1+ (1,0) [0|1] "" Vector__XXX
 SG_ BH_Blinker_li : 0|1@1+ (1,0) [0|1] "" Vector__XXX
 SG_ F_Kombi_02_1_Ant : 57|1@1+ (1,0) [0|1] "" Vector__XXX
 SG_ KBI_Standzeit : 24|15@1+ (4,0) [0|131068] "Unit_Seconds" Vector__XXX
 SG_ F_SMLS_01_Ant : 56|1@1+ (1,0) [0|1] "" Vector__XXX

BO_TX_BU_ 2024 : Motor_EDC17_Pirol,Motor_MED17_Hybrid;
BO_TX_BU_ 1607 : Motor_EDC17_Pirol,Motor_MED17_Hybrid;
CM_ BO_ 17 "Wegfahrsperrenbotschaft";
CM_ SG_ 17 WFS_IMS_MSG1 "Wegfahrsperre";
CM_ BO_ 1705 "Kombiinstrument (FzgID)";
CM_ SG_ 1705 KBI_Fzg_ID_10 "Modelljahr";
CM_ SG_ 1705 KBI_Fzg_ID_11 "Produktionsstandort";
CM_ SG_ 1705 KBI_Fzg_ID_12 "Laufende Ziffer 1, 3.Stelle Fahrzeugtyp";
CM_ SG_ 1705 KBI_Fzg_ID_13 "Laufende Ziffer 2";
CM_ SG_ 1705 KBI_Fzg_ID_14 "Laufende Ziffer 3";
CM_ SG_ 1705 KBI_Fzg_ID_15 "Laufende Ziffer 4";
CM_ SG_ 1705 KBI_Fzg_ID_16 "Laufende Ziffer 5";
CM_ SG_ 1705 KBI_Fzg_ID_17 "Laufende Ziffer 6";
CM_ SG_ 1705 KBI_Fzg_ID_4 "1. Stelle Ländercode";
CM_ SG_ 1705 KBI_Fzg_ID_5 "2. Stelle Ländercode";
CM_ SG_ 1705 KBI_Fzg_ID_8 "2. Stelle Fahrzeugtyp";
CM_ BO_ 1704 "Kombiinstrument (Memory)";
CM_ SG_ 1704 KBI_FLA_GLW_Aktiv "Fernlichtassistent / Gleitende Leuchtweitenregulierung Akiv / Inakiv";
CM_ SG_ 1704 KBI_ASD_innen "Signal wird nur im G1 verwendet!";
CM_ SG_ 1704 KBI_ASD_aussen "Signal wird nur im G1 verwendet!";
CM_ SG_ 1704 KBI_LDW_aktiv "LDW aktiv
";
CM_ SG_ 1704 KBI_Jokerkey_Hupe_Aktiv "Hupe per Jokerkey-Betätigung Aktiv/Inaktiv";
CM_ SG_ 1704 KBI_Automem_inaktiv "Automatische Memory-Speichern beim Verriegeln des Fahrzeugs aktiv / nicht aktiv";
CM_ SG_ 1704 KBI_Heckrollo_b_R "Heckrollo absenken bei Rückwärtsfahrt";
CM_ SG_ 1704 KBI_Klimastyles "Einstellungen der Klimastyles";
CM_ SG_ 1704 KBI_WV_Entr_Kof "Wiederverriegelungszeit der Türen bei Entriegeln des Kofferraums über Fernbedienung";
CM_ SG_ 1704 KBI_Carjack "Carjacking Funktion Verriegelung";
CM_ SG_ 1704 KBI_Tuerentr_T "Türentriegelung bei einem Tastendruck";
CM_ SG_ 1704 KBI_Einstiegshilfe_aktiv "Einstiegshilfe aktiviert";
CM_ SG_ 1704 KBI_FULL_AFS_Tourist "Basiscodierung wird invertiert";
CM_ SG_ 1704 KBI_Aussenspiegel_einklapp_auto "Automatisches Einklappen des Aussenspiegels bei Verriegeln des Fahrzeugs";
CM_ SG_ 1704 KBI_Aussenspiegel_absenken_auto "Automatisches Absenken des Aussenspiegels bei Rückwärtsgang eingelegt";
CM_ SG_ 1704 KBI_Heckw_b_R "Heckwischer bei Rückwärtsgang";
CM_ SG_ 1704 KBI_TFL_akt "Tagfahrlicht aktiv";
CM_ SG_ 1704 KBI_Nachleucht "Nachleuchtzeit Coming-/Leaving Home Beleuchtung";
CM_ SG_ 1704 KBI_WV_Entr "Wiederverriegelungszeit bei Entriegeln mit Fernbedienung ohne Türöffnung";
CM_ SG_ 1704 KBI_Erw_BelueftFeld "Einstellung Klima Erw. Belüftungsfeld";
CM_ SG_ 1704 KBI_Mittenduesentemp "Einstellung Klima Mittenduesentemperatur (-1, 0)

Alt und nicht mehr gültig ist der Wertebereich -2,-1,0,1,2";
CM_ SG_ 1704 KBI_Nachleucht_IL "Nachleuchtzeit Innenlicht";
CM_ SG_ 1704 KBI_Auto_Umluft "Automatische Umluft";
CM_ SG_ 1704 KBI_Schaltpkt_Anz_ein "Schaltpunktanzeige am Multifunktionslenkrad ein/aus";
CM_ SG_ 1704 KBI_RS_d_akt "Regensensor aktiv (nach Zündung ein)
Voraussetzung: Wischerhebel in Intervallstellung";
CM_ SG_ 1704 KBI_Dimmung_OriLicht "Dimmung Orientierungslicht 0-100% (von PCM)
Bei Fehlerwert keinen Fehlercode ablegen!";
CM_ BO_ 1792 "Funktionaler Diagnose-Request (UDS Broadcast)";
CM_ SG_ 1792 Diag_Rq_Fktnl_Data_UDS "Funktionaler Diagnose Request - Data";
CM_ BO_ 1424 "BCM Vorne (auf Basis Audi B8)";
CM_ SG_ 1424 KYL_Warn_Notzuendschloss "Aufforderung an den Benutzer, den Schlüsssel an die Notspule zu halten, wenn Kessy den Schlüssel nicht finden kann
'Keyless Go defekt. Zum Starten den Schlüssel vor das Symbol halten!'
(Signal wird im Panamera nicht bedient)";
CM_ SG_ 1424 KYL_Notzuendschloss "Kessy mit Notzuendschloss verbaut
(Signal wird im Panamera nicht bedient)
";
CM_ SG_ 1424 KY_StartStopp_Info "Stopp-Freigabe und Start-Anforderung an den Start-Stopp-Koordinator";
CM_ SG_ 1424 KY_Funkschl_Nr "Funkschlüsselnummer gültig für die Fahrerberechtigung
";
CM_ SG_ 1424 KY_ID_Geb_autorisiert "Authorisierung Schluessel (ID-Geber)";
CM_ SG_ 1424 KY_ID_Geb_steckt "Schluessel (ID-Geber) im Zuendschloss";
CM_ SG_ 1424 KY_FFB_Frequenz "Frequenz FFB";
CM_ SG_ 1424 KY_HF_Aktiv "HF Funkempfang";
CM_ SG_ 1424 KY_LF_Aktiv "LF Schluesselkommunikation";
CM_ SG_ 1424 KY_ELV_verr "Verriegelungsstatus ELV";
CM_ SG_ 1424 KY_ELV_entr "Entriegelungsstatus ELV";
CM_ SG_ 1424 KY_ELV_enable_Anforderung "Anforderung ELV-Freigabe";
CM_ SG_ 1424 KY_Valet_Parking "Gilt nicht für PAG Panamera. Wird konstant mit 0 gesendet. 
Erkennung Schluessel für Valet Parking";
CM_ SG_ 1424 KY_Keyless_Verbau "Verbauinfo Keyless";
CM_ SG_ 1424 KY_FBS_Fahrer_Hinweise "Vorhalt - Signal wird aktuell im Panamera nicht verwendet.
Kombi Fahrer Hinweise FBS";
CM_ SG_ 1424 FBS_Warn_Lenkung_def "Kombi Prio Warnung Lenkung defekt
'Fahrzeug abstellen, Lenkung defekt!'";
CM_ SG_ 1424 FBS_Warn_LenkVerriegelung_def "Kombi Prio Warnung Lenkungsverriegelung defekt
'Lenkungsverriegelung, Werkstatt aufsuchen!'";
CM_ SG_ 1424 FBS_Warn_Schluessel_Batt "Kombi Prio Warnung Schluessel Batterie
'Bitte Schlüsselbatterie wechseln!'";
CM_ SG_ 1424 FBS_Prio_Warn_04 "Kombi Prio Warnung FBS 4";
CM_ SG_ 1424 FBS_Prio_Warn_05 "Kombi Prio Warnung FBS 5";
CM_ SG_ 1424 KY_KYL_Fahrer_Hinweise "Kombi Fahrer Hinweise Keyless";
CM_ SG_ 1424 KYL_Warn_kein_Schluessel "Kombi Prio Warnung Keyless 
'Schlüssel nicht im Fahrzeug!'";
CM_ SG_ 1424 KYL_Warn_Kessy_defekt "Kombi Prio Warnung Keyless
'Keyless Go defekt, Zündschloß benutzen'";
CM_ SG_ 1424 KY_KYL_Prio_Warn_03 "Kombi Fahrerhinweis FBS - 'Mehrere Schluessel im Fahrzeug erkannt'";
CM_ SG_ 1424 KY_KYL_Prio_Warn_04 "Kombi Fahrerhinweis FBS - 'Zum Fahrzeug verriegeln bitte Türen schliessen'";
CM_ SG_ 1424 KY_KYL_Prio_Warn_05 "Kombi Prio Warnung Keyless 5";
CM_ SG_ 1424 KY_Schluessel_Soll "Sollwert der zu lernenden Schluessel";
CM_ SG_ 1424 KY_Schluessel_Ist "Istwert der gelernten Schluessel";
CM_ SG_ 1424 KY_WFS_Safe "Status WFS";
CM_ SG_ 1424 KY_WFS_LZ "Anforderung aus Lastenheft WFS V
";
CM_ SG_ 1424 FBS_KD_Fehler "Gilt nicht für PAG Panamera. Wird konstant mit 0 gesendet.
Kundendienstfehlerspeicher FBS";
CM_ SG_ 1424 SK_Anf_DTC_Abfrage_sofort "Anf. des Service Key Master an den Datensammler FSP-Einträge aus den SG zu lesen.
Bei dieser Anf. wird eine pos. Authentifikationsrunde des Komponentenschutz durchgeführt. Eine gerade aktive KS Runde wird abgebrochen.
(wird im Panamera n. bedient)";
CM_ SG_ 1424 SK_Anf_DTC_Abfrage "Anf. des Service Key Master an den Datensammler FSP-Einträge aus den SG zu lesen
Für die ersten 10 Botschaften nach CAN-Wakeup muss der Initwert gesendet werden. Grund: Flankenerkennung durch den Datensammler
(Signal wird im Panamera nicht bedient)";
CM_ BO_ 960 "BCM Vorne (auf Basis Audi B8)";
CM_ SG_ 960 ZV_verriegelt_extern_soll_02 "Sollzustand: Verriegelung Fahrzeug aussen
_02 für Senden in der Klemmenstatusbotschaft
(Signal wird im Panamera nicht bedient)
";
CM_ SG_ 960 Klemmen_Status_01_CHK "Bildung der Checksumme
Checksumme = Byte2 XOR Byte 3 ... XOR Byte n  XOR CHK-Endwert
Wobei 'CHK-Endwert' abhängig ist vom CAN-ID: CHK-Endwert = MSB XOR LSB
MSB: High-Byte des Identifiers der CAN-Botschaft LSB: Low-Byte des Identifiers der CAN-Botschaft";
CM_ SG_ 960 Klemmen_Status_01_BZ "4bit Botschaftszaehler; wird in jeder Sendebotschaft inkrementiert";
CM_ SG_ 960 ZAS_Kl_S "Klemme S: S-Kontakt (Schluessel steckt)";
CM_ SG_ 960 ZAS_Kl_15 "Klemme 15: Zuendung (SW-Kl.15)";
CM_ SG_ 960 ZAS_Kl_X "Klemme 75";
CM_ SG_ 960 ZAS_Kl_50 "Klemme 50: Startwunsch Fahrer";
CM_ BO_ 1137 "BCM Hinten (Basis Audi B8)";
CM_ SG_ 1137 LH_Aussenlicht_def "Aussenlicht kann nicht mehr korrekt angesteuert werden (EEPROM Codierung kann nicht mehr ausgelesen werden)
(Signal wird im Panamera nicht bedient)
";
CM_ SG_ 1137 LH_Standlicht_H_aktiv "Standlicht hinten
(Signal wird im Panamera nicht bedient)";
CM_ SG_ 1137 LH_SL_BRL_BLK_re_def "Konfiguration SL + BRL + BLK rechts oder SL + BRL + BLK + PL rechts
(Signal wird im Panamera nicht bedient)";
CM_ SG_ 1137 LH_SL_BRL_BLK_li_def "Konfiguration SL + BRL + BLK links oder SL + BRL + BLK + PL links
(Signal wird im Panamera nicht bedient)
";
CM_ SG_ 1137 LH_Schluss_Nebel_re_def "Konfiguration SL + NSL rechts oder SL + NSL + PL rechts
(Signal wird im Panamera nicht bedient)";
CM_ SG_ 1137 LH_Schluss_Nebel_li_def "Konfiguration SL + NSL links oder SL + NSL + PL links
(Signal wird im Panamera nicht bedient)";
CM_ SG_ 1137 LH_Schluss_Brems_re_def "Konfiguration SL+ BRL + PL rechts und SL+ BRL  rechts
(Signal wird im Panamera nicht bedient)";
CM_ SG_ 1137 LH_Schluss_Brems_Nebel_re_def "Signal wird gesetzt, wenn eine Unterbrechung oder  ein Kurzschluss am Lampenausgang für Schluss_Brems_Nebelschlusslicht erkannt wird.
(Signal wird im Panamera nicht bedient)";
CM_ SG_ 1137 LH_Schluss_Brems_Nebel_li_def "Signal wird gesetzt, wenn eine Unterbrechung oder  ein Kurzschluss am Lampenausgang für Schluss_Brems_Nebelschlusslicht erkannt wird.
(Signal wird im Panamera nicht bedient)";
CM_ SG_ 1137 LH_Schluss_Brems_li_def "Konfiguration SL+ BRL + PL links und SL+ BRL  links
(Signal wird im Panamera nicht bedient)";
CM_ SG_ 1137 LH_Rueckfahrlicht_aktiv "Rueckfahrlicht
(Signal wird im Panamera nicht bedient)";
CM_ SG_ 1137 LH_Rueckf_mi_def "Fehlererkennung Rückfahrlicht Mitte
(Signal wird im Panamera nicht bedient)";
CM_ SG_ 1137 LH_Parklicht_HR_aktiv "Parklicht hinten rechts 
(Signal wird im Panamera nicht bedient)";
CM_ SG_ 1137 LH_Parklicht_HL_aktiv "Parklicht hinten links 
(Signal wird im Panamera nicht bedient)";
CM_ SG_ 1137 LH_Nebelschluss_aktiv "Nebelschlusslicht
(Signal wird im Panamera nicht bedient)";
CM_ SG_ 1137 LH_Nebel_mi_def "Fehlererkennung Nebelschlusslicht hinten Mitte
(Signal wird im Panamera nicht bedient)


";
CM_ SG_ 1137 LH_Bremslicht_H_aktiv "Bremslicht hinten
(Signal wird im Panamera nicht bedient)
";
CM_ SG_ 1137 LH_Brems_Blk_re_def "Konfiguration BRL + BLK rechts
(Signal wird im Panamera nicht bedient)";
CM_ SG_ 1137 LH_Brems_Blk_li_def "Konfiguration BRL + BLK links 
(Signal wird im Panamera nicht bedient)";
CM_ SG_ 1137 LH_Blinker_re_def "Fehlerstatus Blinker hinten rechts
(Signal wird im Panamera nicht bedient)
";
CM_ SG_ 1137 LH_Blinker_li_def "Fehlerstatus Blinker hinten links
(Signal wird im Panamera nicht bedient)";
CM_ SG_ 1137 LH_Blinker_HR_akt "Blinker hinten rechts
(Signal wird im Panamera nicht bedient)";
CM_ SG_ 1137 LH_Blinker_HL_akt "Blinker hinten links
(Signal wird im Panamera nicht bedient)";
CM_ SG_ 1137 BCM2_Bremsl_durch_ECD "Bremslicht (ECD-Bremsung)
";
CM_ SG_ 1137 LH_Bremsl_re_ges_def "Fehlerstatus Bremslicht hinten links (Detektion Totalausfall)
(Signal wird im Panamera nicht bedient)";
CM_ SG_ 1137 LH_Bremsl_li_ges_def "Fehlerstatus Bremslicht hinten links (Detektion Totalausfall)
(Signal wird im Panamera nicht bedient)";
CM_ SG_ 1137 LH_Bremsl_li_def "Bremslicht (ECD-Bremsung)";
CM_ SG_ 1137 LH_Schlusslicht_li_def "1 = mindestens ein Schlusslicht hinten links defekt";
CM_ SG_ 1137 LH_Rueckf_li_def "1 = Rückfahrlicht hinten links defekt";
CM_ SG_ 1137 LH_Nebel_li_def "1 = Nebelschlusslicht hinten links defekt";
CM_ SG_ 1137 LH_Bremsl_re_def "1 = mindestens ein Bremslicht hinten rechts defekt";
CM_ SG_ 1137 LH_Schlusslicht_re_def "1 = mindestens ein Schlusslicht hinten rechts defekt";
CM_ SG_ 1137 LH_Rueckf_re_def "1 = Rückfahrlicht hinten rechts defekt";
CM_ SG_ 1137 LH_Nebel_re_def "1 = Nebelschlusslicht hinten rechts defekt";
CM_ SG_ 1137 LH_Kennzl_def "1 = Kennzeichenbeleuchtung hinten defekt";
CM_ SG_ 1137 LH_3_Bremsl_def "1 = hochgesetzte  Bremsleuchte defekt";
CM_ SG_ 1742 NMH_BMS_NL_Daten_EEPROM "EEPROM Datenspeicherung (lokaler / SG interner Nachlauf vor Wakeup)";
CM_ SG_ 1742 NMH_BMS_NL_Luefter "Lüftersteuerung für Batteriekühlung (lokaler / SG interner Nachlauf vor Wakeup)";
CM_ SG_ 1742 NMH_BMS_Signalfehler "Bei der Speicherung eines CAN-Signalfehlers muss dieser mindestens einmal in der NM-Botschaft angezeigt werden.";
CM_ SG_ 1742 NMH_BMS_TimeOut_Fehler "Das BMS hat einen aktiven Timeout-Fehler zu einem anderen SG erkannt und setzt dieses Bit. Der FSP-Eintrag ist aktiv. Sobald wieder Botschaften des anderen Teilnehmers empfangen werden (FSP-Eintrag passiv), wird das Bit zurückgesetzt.";
CM_ SG_ 1742 NMH_BMS_CAN_Diag_deaktiv "Das Bit wird vom BMS in folgenden Fällen gesetzt (CAN-Diagnose ist deaktiv):
- Hochlauf des Steuergeräts nach CAN-Wakeup (t_diag_start ist noch nicht abgelaufen)
- Retriggerung von t_diag_start bei Kl.15 EIN
- Unterspannung (U < 9V)
- Überspannung (U ";
CM_ SG_ 1742 NMH_BMS_KompSchutz "Das Bit wird vom BMS immer mit 0 gesendet";
CM_ SG_ 1742 NMH_BMS_Mute_Mode "Das Bit wird vom BMS wie folgt bedient: wenn über den UDS-Service 'Communication Control' ein Abschalten der Applikationsbotschaften gefordert wird und gleichzeitig noch NWM-Botschaften gesendet werden dürfen, dann wird das Bit gesetzt
";
CM_ SG_ 1742 NMH_BMS_Transport_Mode "Funktionseinschränkung aufgrund Transportmodus aktiv:
Das Bit wird vom BMS gesetzt, wenn das Signal 'BEM_02_Abschaltstufen' in der Botschaft BEM_02 den Wert 4 
(= Transportmodus) annimmt. Die Ambientebeleuchtung wird vom BMS abgeschaltet bzw. nicht eing";
CM_ SG_ 1742 NMH_BMS_Abschaltstufe_aktiv "Funktionseinschränkung aufgrund Abschaltstufe aktiv:
Das Bit wird vom BMS gesetzt, wenn das Signal 'BEM_02_Abschaltstufen' in der Botschaft BEM_02 den Wert 2 (= Stufe 2), den Wert 3 (= Stufe 3) oder den Wert 7 (= Ruhestrommessmodus) annimmt. Die Ambiente";
CM_ SG_ 1742 NMH_BMS_Busfehler "Das Bit wird vom BMS gesetzt, wenn der ERROR-Pin des CAN-Transceivers dem µController einen Fehler signalisiert.";
CM_ SG_ 1742 NMH_BMS_Lokalaktiv "Zeigt an ob Steuergerät lokal aktiv war";
CM_ SG_ 1742 NMH_BMS_Subsystemaktiv "Zeigt an ob ein Subsystem des SGs nach Klemme15 AUS und nach entsprechender MAX Aktivzeit noch aktiv war";
CM_ SG_ 1742 NMH_BMS_Start_1 "Transition in NMH-Statemachine: 'Bus-Sleep' ==> 'Start'
Das Bit wird von der Standard-SW bedient.";
CM_ SG_ 1742 NMH_BMS_Start_2 "Transition in NMH-Statemachine: 'Prepare To Sleep' ==> 'Start'
Das Bit wird von der Standard-SW bedient.";
CM_ SG_ 1742 NMH_BMS_Normal_Mode_1 "Transition in NMH-Statemachine: 'Start' ==> 'Normal Mode'
Das Bit wird von der Standard-SW bedient.";
CM_ SG_ 1742 NMH_BMS_Normal_Mode_2 "Transition in NMH-Statemachine: 'Ready To Sleep' ==> 'Normal'
Das Bit wird von der Standard-SW bedient.";
CM_ SG_ 1742 NMH_BMS_Car_WakeUp "Das Bit wird vom VSG nicht bedient. Die Car Wakeup-Funktionalität ist im BMS nicht umgesetzt.
";
CM_ SG_ 1742 NMH_BMS_Per_WakeUp "Peripherie-Wakeup (Peripherie inkl. CAN hat geweckt):
1 = CAN

";
CM_ SG_ 1742 NMH_BMS_Fkt_WakeUp "Funktions-Wakeup (Softwarefunktion hat geweckt):
0x0 Peripherie-Wakeup


";
CM_ SG_ 1742 NMH_BMS_Klemme_15 "NM-Nachlaufursache: Das BMS sendet noch NM-high Botschaften (befindet sich nicht im Zustand 'Ready To Sleep') aufgrund einer eingeschalteten Kl.15. In diesem Fall wird das Bit vom BMS gesetzt.";
CM_ SG_ 1742 NMH_BMS_Diagnose "NM-Nachlaufursache: Das BMS sendet noch NM-high Botschaften (befindet sich nicht im Zustand 'Ready To Sleep') bei Kl.15 AUS und aktiver Diagnosesession. In diesem Fall wird das Bit vom BMS gesetzt.";
CM_ SG_ 1742 NMH_BMS_MindestAktivZeit "NM-Nachlaufursache: Das BMS sendet noch NM-high Botschaften (befindet sich nicht im Zustand 'Ready To Sleep') aufgrund der Mindestaktivzeit von 4s. In diesem Fall wird das Bit vom BMS gesetzt.";
CM_ BO_ 1612 "Zentrale GW-Botschaft Codiermaster (Baureihe, Antrieb, Karosserie, Lenker)
(Signale dieser Botschaft dürfen nur zur Plausibilisierung herangezogen werden, nicht zur Verwendung bei sicherheitsrelevanten Funktionen)";
CM_ SG_ 1612 GW_Fzg_Antrieb "Antriebssystem";
CM_ SG_ 1612 GW_Karosserie_Typ "Karosserietyp";
CM_ SG_ 1612 GW_Baureihe "Baureihe";
CM_ SG_ 1612 GW_Lenker "Rechts- / Linkslenkerinfo";
CM_ BO_ 1009 "Zentrale GW-Botschaft (Botschaft wird durch Fehlerspeicheraktivierungsbit auch spontan gesendet)";
CM_ SG_ 1009 GW_STH_Anf "Anforderung 'EIN/AUS bzw. Wecken der Standheizung durch Gateway'";
CM_ SG_ 1009 FSAktivBit "Fehlerspeicheraktivierungsbit";
CM_ SG_ 1625 EKL_KD_Fehler "Bei gesetztem Bit ist mindestens ein Kundendienstfehler eingetragen";
CM_ SG_ 1625 EKL_Comp_SCI_com_stat "'00' normal
'x1' CAN_error (abnormal)
'1x' Inverter_error";
CM_ SG_ 1625 EKL_Comp_output_stat "Diagnosis series 1 'Output'
'0' normal
'1' output line short
'2' output line cut out
'3' abnormal current detection";
CM_ SG_ 1625 EKL_Comp_main_stat "Real compressor status not CAN board status";
CM_ SG_ 1625 EKL_Comp_ovld_stat "Diagnosis series 1 'Over load'
0 normal
1 voltage restriction
2 current restriction
3 software over current
4 over load
6 over input current";
CM_ SG_ 1625 EKL_Comp_Inv_stat "Diagnosis series 2 'Startability'
'0' normal
'1' start fail
'2' temperature protection
'3' system abnormal stop";
CM_ SG_ 1625 EKL_Comp_photo_temp_stat "Diagnosis series 2 'Inverter temp.'
'0' normal
'1' over heat L
'2' over heat S
'3' sermister abnormal";
CM_ SG_ 1625 EKL_Comp_photo_temp "IGBT temp. measured by inverter.
Photo coupler temp. is not  measured in compressor temp. of IGBT (same as EK1_Comp_Inv_temp) will be sent";
CM_ SG_ 1625 EKL_Comp_current "Compressor input current";
CM_ SG_ 1625 EKL_Comp_rev_stat "compressor real revolution
0-8624 rpm is outputted
'output = (actual speed + 25) / 50'   speed over 8625rpm: '172'";
CM_ BO_ 2617027073 "Entwicklungsbotschaft";
CM_ SG_ 2617027073 AB_EB2_Tx_Data "Entwicklungsbotschaftsdaten (Senden)";
CM_ BO_ 2617027072 "Entwicklungsbotschaft";
CM_ SG_ 2617027072 AB_EB1_Tx_Data "Entwicklungsbotschaftsdaten (Senden)";
CM_ BO_ 1793 "Funktionaler Diagnose-Request KWP2000 (Broadcast)";
CM_ SG_ 1793 Diag_Rq_Fktnl_Data_KWP2000 "Funktionaler Diagnose Request - Data";
CM_ BO_ 2015 "OBD Diagnose-Request";
CM_ SG_ 2015 Diag_Rq_Fktnl_Data_OBD "Funktionaler Diagnose Request - Data";
CM_ BO_ 905 "Gateway N:1 Botschaft auf CAN Antrieb";
CM_ SG_ 905 EPB_Anfahrwunsch_erkannt "Anfahrwunsch erkannt
Aktuell kein Empfänger. Vorhalt für E2.";
CM_ SG_ 905 EPB_QBit_Schalterpos "QBit für Signal 'EPB_Schalterposition'";
CM_ SG_ 905 EPB_Schalterposition "Spiegelt die Schalterstellung wieder.

";
CM_ SG_ 905 EPB_Freig_Verzoeg_Anf "Freigabe Verzögerungsanforderung";
CM_ SG_ 905 KL_Segeln_Anf_deaktivieren "Anforderung das Segeln zu deaktvieren";
CM_ SG_ 905 KL_T_Abgasklappe "Taster Sportabgasklappenanlage";
CM_ SG_ 905 DK_PAO_Signalzaehler "Passenger Airbag Off Leuchte - Signalzähler";
CM_ SG_ 905 KL_St_Atemp "Status Aussentemperatursensor erfolgt durch elektrische Diagnose des Sensors (OBD1-Prüfung), Übergabe an die DME zur Fehlerplausibilisierung.";
CM_ SG_ 905 KL_Komp_ein "Kompressor eingeschaltet";
CM_ SG_ 905 KL_Drehz_Anh "Anhebung der Leerlaufdrehzahl
alter Signalname in Matrix 3.0 vor Angleichung an Konzernmatrix VW/Audi:
KL_N_Anheb
";
CM_ SG_ 905 KL_Anf_KL "Ansteuerung Kuehlerluefter";
CM_ SG_ 905 KL_KaeltemittelDruck "Kaeltemitteldruck";
CM_ SG_ 905 DK_St_PAO_Leuchte "PassengerAirbagOff (PAO) - Leuchte";
CM_ SG_ 905 KL_Sportmodus "Sportmodus";
CM_ SG_ 905 F_EPB_01_Ant "Ungueltige Signale: EPB_Status, EPB_Fehlerstatus, EPB_Freig_Verzoeg_Anf, EPB_QBit_Schalterpos, EPB_Schalterposition, EPB_Anfahrwunsch_erkannt";
CM_ SG_ 905 EPB_Status "Gibt den Zustand der EPB-Aktuatoren an.";
CM_ SG_ 905 F_Klima_03_Ant "Ungueltige Signale: KL_Magnetventil,KL_STH_aktiv,KL_STH_Ansteuerung";
CM_ SG_ 905 KL_Magnetventil "Wasserventil zum Waermetauscher geoeffnet/geschlossen";
CM_ SG_ 905 KL_T_PSM_off "PSM-Off Taster (Anforderung ESP passiv schalten)";
CM_ SG_ 905 KL_F_Komp_Endst "Fehler Klimakompressor Endstufe";
CM_ SG_ 905 F_Klima_01_1_Ant "Ungueltige Signale: KL_Anf_KL,KL_Drehz_Anh,KL_Last_Kompr";
CM_ SG_ 905 F_Klima_08_1_PAG_Ant "Ungueltige Signale: KL_T_PSM_off,KL_Sportmodus,KL_KaeltemittelDruck,KL_St_Atemp,KL_T_Abgasklappe,KL_F_Komp_Endst,KL_Komp_ein, KL_Segeln_Anf_deaktivieren";
CM_ SG_ 905 F_BCM2_03_PAG_Ant "Ungueltige Signale: DK_St_PAO_Leuchte, DK_PAO_Signalzaehler";
CM_ SG_ 905 KL_Last_Kompr "Kompressorlast
alter Signalname in Matrix 3.0 vor Angleichung an Konzernmatrix VW/Audi:
KL_Komp_Last";
CM_ SG_ 905 KL_STH_Ansteuerung "Ansteuerung Standheizung";
CM_ SG_ 905 KL_STH_aktiv "Standheizung aktiv";
CM_ SG_ 905 EPB_Fehlerstatus "EPB Fehlerstatus";
CM_ BO_ 1917 "Diagnosebotschaft PSM";
CM_ SG_ 1917 Diag_Rs_DLSNFS_PSM "Diag RS DLSNFS";
CM_ SG_ 1917 Diag_Rs_PCItype_PSM "Protocol Control Information type (PCItype)";
CM_ SG_ 1917 Diag_Rs_Data_PSM "Diag RS Data";
CM_ BO_ 2025 "OBD-Diagnosebotschaft PDK";
CM_ SG_ 2025 ISO_Getriebe_01_Resp_Data "Diag RS Data";
CM_ BO_ 2024 "Diagnosebotschaft Motorsteuergeraet";
CM_ SG_ 2024 ISO_MO_01_Resp_Data "Diag RS Data";
CM_ BO_ 279 "ACC-Botschaft";
CM_ SG_ 279 AWV1_Freigabe "Das Freigabebit muss gesetzt sein, um die Anforderung 'AWV1_Anforderung_Prefill' und 'AWV1_Anforderung_Parameter_HBA'  zur Umsetzung im ESP freizugeben.";
CM_ SG_ 279 AWV_Vorstufe "Info an das Restfahrzeug, dass in Kürze eine Notbremsung/schnelles Ausweichmanöver erfolgt (Info wird u.a. in Dämpferregelung zur Anpassung der Regelung verwendet).
Gilt nicht für PAG Panamera.";
CM_ SG_ 279 ANB_Zielbremsung_Freigabe "Freigabe-Bit der Zielbremsung an das ESP.";
CM_ SG_ 279 ANB_Zielbrems_Teilbrems_Verz_Anf "Verzögerungsanforderung der Funktionen Zielbremsung und Teibremsung an das ESP";
CM_ SG_ 279 ANB_Teilbremsung_Freigabe "Freigabe-Bit der Teilbremsung an das ESP.
Gilt nicht für PAG Panamera.";
CM_ SG_ 279 ANB_Notfallblinken "Info an das BCM_2 die Warnblinkanlage anzusteuern.
Gilt nicht für PAG Panamera.";
CM_ SG_ 279 ANB_Info_Teilbremsung "Über das Signal s_ANB_Info_Teilbremsung muss das ACC-SG dem ESP-SG dauerhaft beginnend mit einer Teilbremsung-Anforderung mitteilen welche Ausprägung angefordert wird.
Gilt nicht für PAG Panamera.";
CM_ SG_ 279 ANB_CM_Anforderung "ANB_CM-Anforderungsbit an das ESP
Gilt nicht für PAG Panamera.";
CM_ SG_ 279 ACC_10_CHK "Bildung der Checksumme
Checksumme = Byte2 XOR Byte 3 ... XOR Byte n  XOR CHK-Endwert
Wobei 'CHK-Endwert' abhängig ist vom CAN-ID: CHK-Endwert = MSB XOR LSB
MSB: High-Byte des Identifiers der CAN-Botschaft LSB: Low-Byte des Identifiers der CAN-Botschaft";
CM_ SG_ 279 ACC_10_BZ "Botschaftszähler";
CM_ SG_ 279 AWV1_Anf_Prefill "Anforderung an ESP, dass die Prefill-Funktion aktiviert werden soll.
Nur Audi B8: Umsetzung der Prefill-Anforderung im ESP nur in Verbindung mit gesetztem Bit 'AWV1_Freigabe'.";
CM_ SG_ 279 AWV2_Freigabe "Freigabesignal";
CM_ SG_ 279 AWV2_Priowarnung "Im Falle einer AWV2-Vorwarnung (optisch/akustisch) oder eines AWV2-Bremsruckes soll im LDW eine Fahrerwarnung bzgl. Verlassen der Fahrspur unterdrückt werden. (AWV2 hat Priorität. Eine gleichzeitige LDW-Warnung könnte den Fahrer irritieren.) ";
CM_ SG_ 279 AWV1_HBA_Param "Anforderung an ESP, welcher HBA-Parametersatz verwendet werden soll. Die Festlegung der Empfindlichkeitsschwellen der verschiedenen Parametersätze erfolgt mit der Applikation des Gesamtsystems ESP/ACC bzw. des HBA.
Nur Audi B8: Umsetzung der Anforderung";
CM_ SG_ 279 AWV2_Ruckprofil "Anforderung an ESP, welcher Ruck aus einer Auswahl von max. 7 verschiedenen Ruckprofilen verwendet werden soll. Eine Umsetzung der Ruckanforderung im ESP erfolgt nur mit gesetztem Bit 'AWV2 Freigabe'.";
CM_ BO_ 1919 "Diagnosebotschaft Airbag";
CM_ SG_ 1919 Diag_Rs_DLSNFS_Airbag "Diag RS DLSNFS";
CM_ SG_ 1919 Diag_Rs_PCItype_Airbag "Protocol Control Information type (PCItype)";
CM_ SG_ 1919 Diag_Rs_Data_Airbag "Diag RS Data";
CM_ BO_ 1811 "Diagnosebotschaft PSM";
CM_ SG_ 1811 Diag_Rq_DLSNFS_PSM "Diag RQ DLSNFS";
CM_ SG_ 1811 Diag_Rq_PCItype_PSM "Protocol Control Information type (PCItype)";
CM_ SG_ 1811 Diag_Rq_Data_PSM "Diag RQ Data";
CM_ BO_ 1813 "Diagnosebotschaft Airbag";
CM_ SG_ 1813 Diag_Rq_Data_Airbag "Diag RQ Data";
CM_ SG_ 1813 Diag_Rq_DLSNFS_Airbag "Diag RQ DLSNFS";
CM_ SG_ 1813 Diag_Rq_PCItype_Airbag "Protocol Control Information type (PCItype)";
CM_ BO_ 1875 "Diagnosebotschaft Waehlhebel";
CM_ SG_ 1875 Diag_Rq_DLSNFS_Waehlhebel "Diag RQ DLSNFS";
CM_ SG_ 1875 Diag_Rq_PCItype_Waehlhebel "Protocol Control Information type (PCItype)";
CM_ SG_ 1875 Diag_Rq_Data_Waehlhebel "Diag RQ Data";
CM_ BO_ 2017 "OBD-Diagnosebotschaft PDK";
CM_ SG_ 2017 Diag_Rq_PCItype_PDK_OBD "Diag RQ PCItype (Protocol Control Information type)";
CM_ SG_ 2017 Diag_Rq_DLSNFS_PDK_OBD "Diag RQ DLSNFS";
CM_ SG_ 2017 Diag_Rq_Data_PDK_OBD "Diag RQ Data";
CM_ BO_ 2016 "OBD-Diagnosebotschaft Motorsteuergerät";
CM_ SG_ 2016 Diag_Rq_PCItype_Motor_OBD "Diag RQ PCItype (Protocol Control Information type)";
CM_ SG_ 2016 Diag_Rq_DLSNFS_Motor_OBD "Diag RQ DLSNFS";
CM_ SG_ 2016 Diag_Rq_Data_Motor_OBD "Diag RQ Data";
CM_ SG_ 1630 OBD_TG_F_Status_1 "Fehlerstatus Tankfüllstandsgeber (OBD relevanter Sensor für Tankleckdiagnose)";
CM_ SG_ 1630 OBD_TG_F_Status_2 "Fehlerstatus Tankfüllstandsgeber (OBD relevanter Sensor für Tankleckdiagnose)

0x00 = kein Fehler / Init / nicht verbaut
0x01 = KS-
0x02 = KS+ (B8: nicht bedient)
0x03 = OC (Leitungsunterbrechung) (B8: nicht bedient)
0x04 = OOR+ (out of range high) ";
CM_ SG_ 1630 OBD_TG_F_Status_3 "Fehlerstatus Tankfüllstandsgeber (OBD relevanter Sensor für Tankleckdiagnose)

0x00 = kein Fehler / Init / nicht verbaut
0x01 = KS-
0x02 = KS+ (B8: nicht bedient)
0x03 = OC (Leitungsunterbrechung) (B8: nicht bedient)
0x04 = OOR+ (out of range high) ";
CM_ SG_ 1630 OBD_TG_F_Status_4 "Fehlerstatus Tankfüllstandsgeber (OBD relevanter Sensor für Tankleckdiagnose)

0x00 = kein Fehler / Init / nicht verbaut
0x01 = KS-
0x02 = KS+ (B8: nicht bedient)
0x03 = OC (Leitungsunterbrechung) (B8: nicht bedient)
0x04 = OOR+ (out of range high) ";
CM_ SG_ 1630 OBD_TG_Sens_Rohwert_1 "Rohwert des Tankgebers, nur gefiltert (gleitender Mittelwert), Ausgabe im 500ms-Raster";
CM_ SG_ 1630 OBD_TG_Sens_Rohwert_2 "Rohwert des Tankgebers, nur gefiltert (gleitender Mittelwert), Ausgabe im 500ms-Raster";
CM_ SG_ 1630 OBD_TG_Sens_Rohwert_3 "Rohwert des Tankgebers, nur gefiltert (gleitender Mittelwert), Ausgabe im 500ms-Raster";
CM_ SG_ 1630 OBD_TG_Sens_Rohwert_4 "Rohwert des Tankgebers, nur gefiltert (gleitender Mittelwert), Ausgabe im 500ms-Raster";
CM_ SG_ 1607 MO_Kraftstofffilter_Wasser "Für Schlechtkraftstoffländer wird das Wasserabscheidevolumen im Dieselkraftstofffilter mit einem  Wassersensor überwacht. Ist das Volumen erschöpft, erfolgt im Kombi eine entsprechende Anzeige.
(Signal wird im Panamera nicht bedient)";
CM_ SG_ 1607 MO_ITM_Kuehlmittel_Temp "Kuehlmitteltemperatur: Ersatzkühlmitteltemperatur für Motoren mit ITM (Thermomanagement)";
CM_ SG_ 1607 MO_CO2_Faktor "dynamischer Umrechnungsfaktor von l in CO2
(Signal wird im Panamera nicht bedient)";
CM_ SG_ 1607 MO_E85_Sensor "Information über den E85 Gehalt (%-mass.) im Ottokraftstoff
(Signal wird im Panamera nicht bedient)";
CM_ SG_ 1607 SCR_Warnstufe_1 "(Signal wird nur im Panamera Pirol bedient)";
CM_ SG_ 1607 SCR_Warnstufe_2 "(Signal wird nur im Panamera Pirol bedient)";
CM_ SG_ 1607 SCR_Inducement_Strategie "Art des Motor-Inducement-Konzepts. Abhängig von diesem Signal sind die Warntexte zwischen 'Kein Motorstart (in...km)' und 'eingeschränkte Fahrbarkeit (in ...km)' auszuwählen.
(Signal wird nur im Panamera Pirol bedient)";
CM_ SG_ 1607 MO_MKB_MUX "Die vier Motorkennbuchstaben werden gemultiplext in MO_MKB übertragen. Das Signal MO_MKB_MUX stellt das Steuersignal für diesen Multiplexer dar.";
CM_ SG_ 1607 MO_MKB_01 "Motorkennbuchstabe 1";
CM_ SG_ 1607 MO_MKB_02 "Motorkennbuchstabe 2";
CM_ SG_ 1607 SCR_Text "(Signal wird nur im Panamera Pirol bedient)";
CM_ SG_ 1607 SCR_Akustik "(Signal wird nur im Panamera Pirol bedient)";
CM_ SG_ 1607 SCR_Systemfehler "Ansteuerung Anzeige für SCR-Systemfehler
(Signal wird nur im Panamera Pirol bedient)";
CM_ SG_ 1607 MO_MKB_04 "Motorkennbuchstabe 4";
CM_ SG_ 1607 MO_MKB_03 "Motorkennbuchstabe 3";
CM_ BO_ 269 "ACC05 wegen Kompatibilität zu E2
Keine Empfänger im G1.
";
CM_ SG_ 269 ACC_Vorbefuellung_Bremsanlage "Über das Signal fordert das ACC-SG eine Vorbefüllung der Bremsanlage beim ESP-SG an.";
CM_ SG_ 269 ACC_StartStopp_Info "Freigabe bzw. Startanforderung für Start/Stopp";
CM_ SG_ 269 ACC_KD_Fehler "Status Kundendienstfehlerspeichereinträge";
CM_ SG_ 269 ACC_Anhalten "Im Falle eines gesetzten Bits wird vom ACC ein Anhalten bis in den Stand gewünscht. Das Bit wird von ACC nur unterhalb einer appl. Geschwindigkeitsschwelle gesetzt. Notwendig für die ACCplus-Funktionalität. Nicht für B8 relevant, jedoch im Vorgriff auf di";
CM_ SG_ 269 ACC_Beeinflussung_ESP "Bit wird verwendet, um ESP zwangsweise zu aktivieren. Bei einem gesetzten Bit ist ein ausgetastetes ESP wieder aktiviert bzw. wird die Austastung verhindert.";
CM_ SG_ 269 ACC_Betaetigung_EPB "Anforderung vom ACC an die EPB, dass der EPB-Aktuator so schnell wie möglich zu schliessen ist";
CM_ SG_ 269 ACC_Status_ACC "ACC-Status für Handshake mit Triebstrangkoordinator.";
CM_ SG_ 269 ACC_ax_Getriebe "Beschleunigungsanforderung an das Getriebe";
CM_ SG_ 269 ACC_Loeseanforderung "Anforderung des ACC an ESP zum Lösen der ECD-Bremsung bei selbständigem Anfahren aus dem Stand im Rahmen der ACC-Stop&Go-Funktion";
CM_ SG_ 269 ACC_Verz_anf "Verzögerungsanforderung an die Bremse.";
CM_ SG_ 269 ACC_zul_Regelabw "Anforderung der zulässigen Regelabweichung vom ACC. Zulässiger Betrag der Abweichung zwischen angeforderter 'ACC_ax_Getriebe' und umzusetzender Sollbeschleunigung  im Getriebe.";
CM_ SG_ 269 ACC_Momentenanforderung "Momentenanforderung an den Motor. Achtung: Einheitenloser CAN-Wert. Faktor in MO_Faktor_Momente in Motor_Code_01 
beachten! 1022 und 1023 sind nicht definierte Werte.";
CM_ SG_ 269 ACC_limitierte_Anfahrdyn "Info für den Motor, dass beim ACC-Anfahren mit Zielfahrzeug seitens ACC eine limitierte Fahrpedalkennlinie gefordert wird.";
CM_ SG_ 269 ACC_Getriebestellung_P "Anforderung vom ACC an das Getriebe, daß die Getriebestellung P so schnell wie möglich einzulegen ist.";
CM_ SG_ 269 ACC_Freigabe_Verzanf "Bit 'Freigabe Verzögerungsanforderung': Freigabe der Verzögerungsanforderung an die Bremse";
CM_ SG_ 269 ACC_Freigabe_Momentenanf "Bit 'Freigabe Momentenanforderung': Freigabe der Momentenanforderung an den Motor";
CM_ SG_ 269 ACC_05_CHK "Bildung der Checksumme
Checksumme = Byte2 XOR Byte 3 ... XOR Byte n  XOR CHK-Endwert
Wobei 'CHK-Endwert' abhängig ist vom CAN-ID: CHK-Endwert = MSB XOR LSB
MSB: High-Byte des Identifiers der CAN-Botschaft LSB: Low-Byte des Identifiers der CAN-Botschaft";
CM_ SG_ 1719 KBI_FStatus_Tank "Signal wird gesetzt:

a) Während der Fehlerentprellzeit (20 s Entprellung)

b) Bei erkanntem Fehler wird der Tankinhalt während der laufenden KL15-Phase über den 
    Verbrauch zurückgerechnet. In dieser Zeit ist das Bit ebenfalls gesetzt. Nach einem";
CM_ SG_ 1719 KBI_QBit_Aussen_Temp_gef "QBit für das Signal 'KBI_Aussen_Temp_gef'";
CM_ SG_ 1719 KBI_Standzeit "Low Byte 4, High Byte 5;
Standzeit in 4 Sekunden Auflösung; mit diesen 15 Bits läßt sich eine Zeit bis 36 Stunden, 24 Minuten und 28 Sekunden darstellen
Signal wird ab G1H vom Kombi bedient!";
CM_ SG_ 1719 KBI_Kilometerstand "Fehler wird ausgegeben, falls Kilometerstand nicht restaurierbar
Hinweis. Bei Fehlerwert muss ein CAN-Signalfehler 'Kombi' eingetragen werden.";
CM_ SG_ 1719 KBI_Aussen_Temp_gef "Außentemperatur angezeigt";
CM_ SG_ 1719 KBI_Inhalt_Tank "Tankfüllstand
Restmenge 2 bzw. 2,5l nicht auflösbar";
CM_ SG_ 779 KBI_MFA_v_Einheit_01 "Einheit der Geschwindigkeit, die vom Fahrer im Car-Menü gewählt wurde. Veränderliche Grösse, im Gegensatz zur Einheit des Tachokranzes.";
CM_ SG_ 779 KBI_Vorglueh_System_Lampe "Rückmeldung der Vorglühlampe bzw. Motor Systemlampe (MO_Systemlampe) an den Motor (bei Diesel und Otto!). Hardwaremässig gleiche LED im Kombi (EPC- oder Glühwendel), Unterscheidung nur über Ziffernblatt.";
CM_ SG_ 779 KBI_Anzeigefehler_SWA "Signal bezieht sich nur auf die SWA-Lampe, Vorhalt für Kombis mit SWA-Lampe. ";
CM_ SG_ 779 KBI_V_Digital "Ausgabe der im Kombi angezeigten digitalen Geschwindigkeit";
CM_ SG_ 779 KBI_Variante_USA "In diesem Signal wird die HW-Variante des Kombis ausgegeben, ACC plausibilisiert auf dieses Signal hin seine US-Codierung";
CM_ SG_ 779 KBI_Konsistenz_ACC "Rückmeldung an ACC, dass die Botschaften zur Ansteuerung von Anzeigen nicht bzw. nicht konsistent empfangen wurden (Timeout-, BZ-, CHK- und DLC-Fehler)                                                                                                        ";
CM_ SG_ 779 KBI_Fehler_Anzeige_ACC "Rückmeldung an ACC, dass mindestens eine der ACC-relevanten Anzeigen -rote Fahrerübernahme, Mitteldisplay, Gong - fehlerhaft sind.";
CM_ SG_ 779 KBI_Einheit_Tacho "Einheit des Digitaltachos";
CM_ SG_ 779 KBI_KD_Fehler "Status Kundendienstfehlerspeichereinträge";
CM_ SG_ 779 KBI_Tankwarnung "Warnleuchte Tank";
CM_ SG_ 779 KBI_angez_Geschw "Im Tacho angezeigte Geschwindigkeit inklusive der Voreilung

";
CM_ SG_ 779 KBI_Airbag_Lampe "Leuchte Airbag OK
Alter Signalname in Matrix 3.0 vor Angleichung an Konzernmatrix VW/Audi:
KBI_L_Airbag_ok";
CM_ SG_ 779 KBI_ABS_Lampe "Leuchte ABS OK
Alter Signalname in Matrix 3.0 vor Angleichung an Konzernmatrix VW/Audi:
KBI_L_ABS_ok";
CM_ BO_ 643 "Airbagbotschaft (Crashdaten, Systemfehler, Gurtschalter)";
CM_ SG_ 643 AB_Gurtwarn_HM "Insasse auf Mitte hinten hat Gurt nicht gesteckt, Anzeige im Kombi";
CM_ SG_ 643 AB_Gurtwarn_HB "Insasse auf Beifahrerseite hinten hat Gurt nicht gesteckt, Anzeige im Kombi";
CM_ SG_ 643 AB_Gurtwarn_HF "Insasse auf Fahrerseite hinten hat Gurt nicht gesteckt, Anzeige im Kombi";
CM_ SG_ 643 AB_PAO_Info "Information zum Zustandswechsel Beifahrerairbag on/off";
CM_ SG_ 643 AB_AWS_Zustand "AWS-Zustand der Insassenklassifizierung";
CM_ SG_ 643 AB_Crashdaten "Info, ob Crashdaten im SG gespeichert sind.";
CM_ SG_ 643 AB_SF_URS "Systemfehler Ueberrollschutz, Anzeige im Kombi (Textauswahl durch Codierung des Kombi)";
CM_ SG_ 643 AB_SF_AWS "Systemfehler AWS, Anzeige im Kombi (Textauswahl durch Codierung des Kombi)";
CM_ SG_ 643 AB_W_AWS_S "Warnung AWS-Stoerung (Gewichtssensierung), Anzeige im Kombi (Textauswahl durch Codierung des Kombi)";
CM_ BO_ 307 "Waehlhebel";
CM_ SG_ 307 WHL_KD_Fehler "Status Kundendienstfehlerspeichereinträge";
CM_ SG_ 307 WHL_Res_OBD_Dia "Reserve OBD-Diagnose";
CM_ SG_ 307 WHL_CHK "Checksumme";
CM_ SG_ 307 WHL_Magnet_Pos "Position des Shift-/Keylock Magneten";
CM_ SG_ 307 WHL_BZ "überlaufender Botschaftszähler ";
CM_ SG_ 307 WHL_TipUp "Tipp Up erste Stufe";
CM_ SG_ 307 WHL_TipDown "Tipp Down erste Stufe";
CM_ SG_ 307 WHL_Pos_komplement "Komplement von whlpos";
CM_ SG_ 307 WHL_Pos "Wählhebelposition";
CM_ BO_ 1315 "Sollverbaubotschaft (Signale dieser Botschaft dürfen nur zur Plausibilisierung herangezogen werden, nicht zur Verwendung bei sicherheitsrelevanten Funktionen)";
CM_ SG_ 1315 SVB_Aero "Sollverbau Aero-Steuergerät";
CM_ SG_ 1315 SVB_SCR "Sollverbau SCR";
CM_ SG_ 1315 SVB_LEH_VA "Sollverbau LEH_VA";
CM_ SG_ 1315 SVB_Ladegeraet "Sollverbau Ladegerät";
CM_ SG_ 1315 SVB_EBKV "Sollverbau EBKV";
CM_ SG_ 1315 SVB_ComBox "SVB_ComBox";
CM_ SG_ 1315 SVB_Lift "Sollverbau Lift SG
";
CM_ SG_ 1315 SVB_HAL "Sollverbau HAL (Hinterachslenkung)
";
CM_ SG_ 1315 SVB_Topview "Sollverbau RealTopview";
CM_ SG_ 1315 SVB_Kamera "Sollverbau Kamera";
CM_ SG_ 1315 SVB_AFS "Sollverbau AFS";
CM_ SG_ 1315 SVB_TSG_HR "Sollverbau Tuersteuergeraet Hinten rechts";
CM_ SG_ 1315 SVB_CDR "Sollverbau CDR (CD Radio)";
CM_ SG_ 1315 SVB_Stoppuhr "Sollverbau Stoppuhr";
CM_ SG_ 1315 SVB_SWR "Sollverbau Scheinwerfersteuergeraet rechts";
CM_ SG_ 1315 SVB_HDSG "Sollverbau HDSG (Heckdeckelsteuergerät, Powerliftgate)";
CM_ SG_ 1315 SVB_PDCC "Sollverbau PDCC (Porsche Dynamic Chassis Control, AAK)";
CM_ SG_ 1315 SVB_EPB "Sollverbau EPB (Elektrische Parkbremse)";
CM_ SG_ 1315 SVB_QSP "Sollverbau Quersperre";
CM_ SG_ 1315 SVB_PSM_Fwk "Sollverbau PSM Fahrwerk (Porsche Stability Management)";
CM_ SG_ 1315 SVB_EPS "Sollverbau EPS (Electro-Powered Steering)";
CM_ SG_ 1315 SVB_VSG "Sollverbau Verdeck-SG";
CM_ SG_ 1315 SVB_Allrad "Sollverbau Allrad";
CM_ SG_ 1315 SVB_TSG_HL "Sollverbau Tuersteuergeraet Hinten links";
CM_ SG_ 1315 SVB_SWL "Sollverbau Scheinwerfersteuergeraet links";
CM_ SG_ 1315 SVB_SSC "Sollverbau SSC (Sensorcluster)";
CM_ SG_ 1315 SVB_MEM_FS "Sollverbau Sitz Fahrer";
CM_ SG_ 1315 SVB_MEM_BFS "Sollverbau Sitz Beifahrer";
CM_ SG_ 1315 SVB_WHL "Sollverbau Waehlhebel";
CM_ SG_ 1315 SVB_TSG_BT "Sollverbau Tuersteuergeraet Beifahrerseite";
CM_ SG_ 1315 SVB_TSG_FT "Sollverbau Tuersteuergeraet Fahrerseite";
CM_ SG_ 1315 SVB_AMP "Sollverbau Verstaerker";
CM_ SG_ 1315 SVB_BCM2 "Sollverbau BCM 2";
CM_ SG_ 1315 SVB_BCM1 "Sollverbau BCM 1";
CM_ SG_ 1315 SVB_RDK "Sollverbau RDK (Reifendruckkontrolle)";
CM_ SG_ 1315 SVB_PCM "Sollverbau PCM (Porsche Communication Management)";
CM_ SG_ 1315 SVB_Motor "Sollverbau Motorsteuergeraet";
CM_ SG_ 1315 SVB_TV "Sollverbau TV-Tuner";
CM_ SG_ 1315 SVB_LWS "Sollverbau Kombilenksaeulenmodul (LWS)";
CM_ SG_ 1315 SVB_SMLS "Sollverbau Kombilenksaeulenmodul (SMLS, LSS)";
CM_ SG_ 1315 SVB_Kombi "Sollverbau Kombiinstrument";
CM_ SG_ 1315 SVB_RearView "Sollverbau Rueckfahrkamera";
CM_ SG_ 1315 SVB_ACC "Sollverbau ACC (Adaptive Cruise Control)";
CM_ SG_ 1315 SVB_PDK "Sollverbau PDK (Porsche Doppelkupplungsgetriebe)";
CM_ SG_ 1315 SVB_AAG "Sollverbau Anhaenger-SG";
CM_ SG_ 1315 SVB_PSM_Ant "Sollverbau PSM Antrieb (Porsche Stability Management)";
CM_ SG_ 1315 SVB_BKE "Sollverbau Bedien-Klimasteuergeraet";
CM_ SG_ 1315 SVB_PASM_NRA "Sollverbau PASM_Niveauregulierung (Porsche Active Suspension Management)";
CM_ SG_ 1315 SVB_STH "Sollverbau Standheizung";
CM_ SG_ 1315 SVB_Airbag "Sollverbau Sicherheit (Airbag)";
CM_ SG_ 1315 SVB_PDC "Sollverbau Parkassistent (4-Kanal oder 10-Kanal)";
CM_ SG_ 1315 SVB_SWA "Sollverbau Spurwechselassistent";
CM_ SG_ 1315 SVB_Kompass "Sollverbau Kompass (nur E2)";
CM_ SG_ 1315 SVB_EKK "Sollverbau Hybridkomponente Klimakompressor";
CM_ SG_ 1315 SVB_EHPS "Sollverbau Hybridkomponente EHPS (Electro-Hydraulic Powered Steering)";
CM_ SG_ 1315 SVB_LEH "Sollverbau Hybridkomponente Leistungselektronik";
CM_ SG_ 1315 SVB_BMS "Sollverbau Hybridkomponente Batteriemanagement SG";
CM_ BO_ 390 "PSM-Botschaft (Vref, ABS, ESP, ASR, Rückmeldungen)";
CM_ SG_ 390 BR_StartStopp_Info "Start/Stop-Info, Veto";
CM_ SG_ 390 BR_W_PDCC_Notlauf "Warntext wird getriggert, wenn Signal 'PDCC_Status' = 1 und PSM-Passivtaste betätigt.
Ansteuerung des Warntextes 'PDCC Notlauf'.";
CM_ SG_ 390 BR_KD_Fehler "Status Kundendienstfehlerspeichereinträge";
CM_ SG_ 390 BR_St_Notbrems "Notbremsung aktiv";
CM_ SG_ 390 BR_Notbrems_verf "Verfügbarkeit Notbremsfunktion";
CM_ SG_ 390 BR_W_PTM_Temp "Warntext wird getriggert, wenn Signal 'ALR_PSM_Akt' = 1 und PSM-Passivtaste betätigt.
Ansteuerung des Warntextes 'PTM Temperaturschutz'.";
CM_ SG_ 390 BR_F_Sport "Fehler Sportmodus Antrieb/Fahrwerk";
CM_ SG_ 390 BR_St_esp_dia "ESP in Diagnose oder Selbsttest
Nach Diagnoseende wird ein SW-Reset ausgelöst,welcher einen Kommunikationsausfall verursacht
Während u. nach der Diagn. können nicht alle Bremse-Sendesignale bedient werden
Signal als Vorhalt auf allen Bussen vorhanden
";
CM_ SG_ 390 BR_mimsr "Eingriffsmoment MSR
Der BZ der Signale BR_mimsr und BR_miasrl ist ein und derselbe Zähler. Die Umschaltung des BZ führt also zu keinen unerwarteten BZ Sprüngen.
BZ zählt nur bis 15!!";
CM_ SG_ 390 BR_miasrs "Eingriffsmoment ASR schnell";
CM_ SG_ 390 BR_miasrl "Eingriffsmoment ASR langsam
Der BZ der Signale BR_mimsr und BR_miasrl ist ein und derselbe Zähler. Die Umschaltung des BZ führt also zu keinen unerwarteten BZ Sprüngen.
BZ zählt nur bis 15!!";
CM_ SG_ 390 BR_St_esp_pas "ESP passiv geschaltet";
CM_ SG_ 390 BR_St_msr "MSR-Anforderung (MotorSchleppmomentenRegelung)";
CM_ SG_ 390 BR_F_esp "ESP Fehler (ESP-Mufla wird angesteuert) ";
CM_ SG_ 390 BR_St_esp_info "ESP-Eingriff (ESP-Mufla  wird angesteuert)";
CM_ SG_ 390 BR_St_esp "ESP-Eingriff";
CM_ SG_ 390 BR_F_ebv "EBV Fehler (EBV-Sila wird angesteuert) ";
CM_ SG_ 390 BR_S_BremsT "BS (Bremstestschalter)
Hinweis: die beiden Signale 'BR_S_BremsL' und 'BR_S_BremsT' werden als ein 2-Bit Signal ausgewertet (s. Bemerkung).";
CM_ SG_ 390 BR_S_BremsL "BLS (Bremslichtschalter)
Hinweis: die beiden Signale 'BR_S_BremsL' und 'BR_S_BremsT' werden als ein 2-Bit Signal ausgewertet (s. Bemerkung).";
CM_ SG_ 390 BR_St_asr "ASR-Anforderung (AntriebsSchlupfRegelung)";
CM_ SG_ 390 BR_F_abs "ABS Fehler (ABS-Sila wird angesteuert)";
CM_ SG_ 390 BR_St_abs "ABS-Bremsung";
CM_ SG_ 390 BR_St_bmr "Bremsmomenten-Eingriff";
CM_ SG_ 390 BR_asrb "ASR-Schaltbeeinflussung";
CM_ SG_ 390 BR_W_QSP_Temp "Warntext wird getriggert, wenn Signal 'QSP_PSM_Akt' = 1 und PSM-Passivtaste betätigt.
Ansteuerung des Warntextes 'Quersperre Temperaturschutz'.";
CM_ SG_ 390 BR_St_Rollenmodus "Der Rollenmodus wird über eine Diagnosefunktion im PSM aktiviert/deaktiviert. 
Ist er aktiv, wird im PDK, Allrad und PDCC für den Betrieb auf Rollenprüfständen adaptiert. 
Im Kombiinstrument erfolgt die Anzeige des Rollenmodus.";
CM_ SG_ 390 ESP_v_Signal "Geschwindigkeitssignal vom PSM. Mittelwert der angetriebenen Räder.
";
CM_ BO_ 1981 "Diagnosebotschaft Waehlhebel";
CM_ SG_ 1981 Diag_Rs_DLSNFS_Waehlhebel "Diag RS DLSNFS";
CM_ SG_ 1981 Diag_Rs_PCItype_Waehlhebel "Protocol Control Information type (PCItype)";
CM_ SG_ 1981 Diag_Rs_Data_Waehlhebel "Diag RS Data";
CM_ BO_ 910 "Gateway N:1 Botschaft auf CAN Antrieb";
CM_ SG_ 910 AAG_Bremslicht_H_def "Anhaenger Bremslicht defekt";
CM_ SG_ 910 KBI_Fehler_Anzeige_ACC "Rückmeldung an ACC, dass mindestens eine der ACC-relevanten Anzeigen -rote Fahrerübernahme, Mitteldisplay, Gong - fehlerhaft sind.";
CM_ SG_ 910 KBI_Einheit_Tacho "Einheit des Digitaltachos";
CM_ SG_ 910 KBI_angez_Geschw "Im Tacho angezeigte Geschwindigkeit inklusive der Voreilung

";
CM_ SG_ 910 F_Kombi_02_Ant "Ungueltige Signale: KBI_Inhalt_Tank, KBI_Aussen_Temp_gef";
CM_ SG_ 910 KBI_Aussen_Temp_gef "Außentemperatur angezeigt";
CM_ SG_ 910 KBI_Inhalt_Tank "Tankfüllstand
Restmenge 2 bzw. 2,5l nicht auflösbar";
CM_ SG_ 910 F_Kombi_11_PAG_Ant "Ungueltige Signale: KBI_L_Tempo_ok, KBI_L_CheckE_ok,KBI_Fotosensor";
CM_ SG_ 910 KBI_L_Tempo_ok "Tempostat-LED OK";
CM_ SG_ 910 KBI_L_CheckE_ok "Status Check Engine LED";
CM_ SG_ 910 F_Klima_08_PAG_Ant "Ungueltige Signale: KL_Atemp_ungef";
CM_ SG_ 910 KL_Atemp_ungef "Aussentemperatur ungefiltert (Achtung bei Übernahme-SG: der Initialwert von der BKE unterscheidet sich vom BCM1-Signal)";
CM_ SG_ 910 KBI_Tankwarnung "Warnleuchte Tank";
CM_ SG_ 910 F_Kombi_01_Ant "Ungueltige Signale: KBI_Airbag_Lampe,KBI_ABS_Lampe, KBI_Tankwarnung,KBI_angez_Geschw,KBI_Einheit_Tacho,KBI_Fehler_Anzeige_ACC";
CM_ SG_ 910 KBI_ABS_Lampe "Leuchte ABS OK
Alter Signalname in Matrix 3.0 vor Angleichung an Konzernmatrix VW/Audi:
KBI_L_ABS_ok";
CM_ SG_ 910 KBI_Airbag_Lampe "Leuchte Airbag OK
Alter Signalname in Matrix 3.0 vor Angleichung an Konzernmatrix VW/Audi:
KBI_L_Airbag_ok";
CM_ SG_ 910 KBI_Fotosensor "Sonnenintensität Kombiinstrument";
CM_ SG_ 910 F_Anhaenger_01_Ant "Ungueltige Signale: AAG_Anhaenger_erkannt, AAG_Bremlicht_H_def";
CM_ SG_ 910 AAG_Anhaenger_erkannt "Erkennung Anhaenger";
CM_ BO_ 787 "Gateway N:1 Botschaft auf CAN Antrieb";
CM_ SG_ 787 F_PDCC_01_Ant "Ungueltige Signale: PDCC_Last_RKP";
CM_ SG_ 787 PDCC_Last_RKP "Aktuelles Antriebsmoment der PDCC Radialkolbenpumpe";
CM_ SG_ 787 ACC_StartStopp_Info "Freigabe bzw. Startanforderung für Start/Stopp";
CM_ SG_ 787 ACC_05_alt "Veraltet-Bit für die Signale: ACC_StartStopp_Info";
CM_ SG_ 787 F_PCM_CDR_01_Ant "Ungueltige Signale: HU_Fotosensor";
CM_ SG_ 787 HU_Fotosensor "Messwert Fotosensor der Headunit (PCM bzw. CDR)
logarithmisch verzerrt (siehe Funktionsbeschreibung Nachtdesign - entsprechend Audi-Lastenheft Dimmung)";
CM_ SG_ 787 BH_Blinker_re "Blinkerhebel Richtung rechts";
CM_ SG_ 787 BH_Blinker_li "Blinkerhebel Richtung links";
CM_ SG_ 787 F_Kombi_02_1_Ant "Ungueltige Signale: KBI_Standzeit";
CM_ SG_ 787 KBI_Standzeit "Low Byte 4, High Byte 5;
Standzeit in 4 Sekunden Auflösung; mit diesen 15 Bits läßt sich eine Zeit bis 36 Stunden, 24 Minuten und 28 Sekunden darstellen
Signal wird ab G1H vom Kombi bedient!";
CM_ SG_ 787 F_SMLS_01_Ant "Ungueltige Signale: BH_Blinker_li,BH_Blinker_re (Signale für Motor als Vorhalt Start/Stopp bei Richtungsblinken aktiv)";
BA_DEF_ SG_  "DERIVATE_Pruefung" ENUM  "offen","geprüft";
BA_DEF_ SG_  "HYB_Rx_Baureihe" ENUM  "G1+Derivate","nur G1","nur Derivate";
BA_DEF_ SG_  "HYB_Rx_Verwendung" ENUM  "DERIV_Rout","DERIV_Calc","DERIV_Rout+DERIV_Calc";
BA_DEF_ SG_  "GenSigSwitchedByIgnition" ENUM  "No","Yes";
BA_DEF_ SG_  "GenSigEnvVarType" ENUM  "int","float","undef";
BA_DEF_ SG_  "GenSigAutoGenSnd" ENUM  "No","Yes";
BA_DEF_ SG_  "GenSigAutoGenDsp" ENUM  "No","Yes";
BA_DEF_ SG_  "GenSigActiveRepetitions" INT -2147483648 2147483647;
BA_DEF_ SG_  "GenSigFuncType" ENUM  "NoFunction","MsgCounter","CRC-8","XOR","XOR-2","DatedBit","SW-Kl15","CHK","Constant","Protocol";
BA_DEF_ SG_  "Info_BCM_HutHut_Kommunikation" ENUM  "Nein","Ja";
BA_DEF_ SG_  "NWM-WakeupAllowed" ENUM  "No","Yes";
BA_DEF_ SG_  "GenSigInactiveValue" STRING ;
BA_DEF_ SG_  "GenSigMissingSourceValue" INT 0 2147483647;
BA_DEF_ SG_  "GenSigStartValue" INT 0 0;
BA_DEF_ SG_  "Fehlerwert" HEX 0 2147483647;
BA_DEF_ SG_  "Bemerkung" STRING ;
BA_DEF_ SG_  "GenSigSendType" ENUM  "Cyclic","OnWrite","OnWriteWithRepetition","OnChange","OnChangeWithRepetition","IfActive","IfActiveWithRepetition","NoSigSendType";
BA_DEF_ BO_  "NmMessage" ENUM  "No","Yes";
BA_DEF_ BO_  "GenMsgAutoGenSnd" ENUM  "No","Yes";
BA_DEF_ BO_  "GenMsgAutoGenDsp" ENUM  "No","Yes";
BA_DEF_ BO_  "MsgType" ENUM  "Broadcast","Event","NM ","NMH","TP2.0","ISO-TP ","BAP","EID";
BA_DEF_ BO_  "GenMsgChkConstant" HEX 0 4095;
BA_DEF_ BO_  "sim_GenMsgILSupport" ENUM  "No","Yes";
BA_DEF_ BO_  "NWM-Botschaft" ENUM  "No","Yes";
BA_DEF_ BO_  "VAGTP20_StatConnection" ENUM  "No","Yes";
BA_DEF_ BO_  "VAGTP20_DynSetup" ENUM  "No","Yes";
BA_DEF_ BO_  "VAGTP20_DynConnection" ENUM  "No","Yes";
BA_DEF_ BO_  "VAGTP20_API" HEX 0 255;
BA_DEF_ BO_  "Direkt_1zu1" ENUM  "Nein","Ja";
BA_DEF_ BO_  "GenMsgSendType" ENUM  "Cyclic","NotUsed","NotUsed","NotUsed","NotUsed","NotUsed","NotUsed","IfActive","NoMsgSendType","NotUsed";
BA_DEF_ BO_  "DiagResponse" ENUM  "No","Yes";
BA_DEF_ BO_  "DiagRequest" ENUM  "No","Yes";
BA_DEF_ BO_  "GenMsgDelayTime" INT 0 65535;
BA_DEF_ BO_  "GenMsgStartDelayTime" INT 0 65535;
BA_DEF_ BO_  "GenMsgILSupport" ENUM  "No","Yes";
BA_DEF_ BO_  "NmhMessage" ENUM  "No","Yes";
BA_DEF_ BO_  "GenMsgNrOfRepetition" INT 0 65535;
BA_DEF_ BO_  "GenMsgCycleTimeFast" INT 0 65535;
BA_DEF_ BO_  "DiagState" ENUM  "No","Yes";
BA_DEF_ BO_  "GenMsgCycleTime" INT 0 65535;
BA_DEF_REL_ BU_BO_REL_  "HYB_Tx_Verwendung" ENUM  "Rout","Calc";
BA_DEF_REL_ BU_BO_REL_  "HYB_Tx_Baureihe" ENUM  "G1+Derivate","G1","Derivate","vector_leerstring";
BA_DEF_REL_ BU_SG_REL_  "GenSigTimeoutTime" INT 0 65535;
BA_DEF_DEF_  "DERIVATE_Pruefung" "offen";
BA_DEF_DEF_  "HYB_Rx_Baureihe" "G1+Derivate";
BA_DEF_DEF_  "HYB_Rx_Verwendung" "DERIV_Rout";
BA_DEF_DEF_  "GenSigSwitchedByIgnition" "No";
BA_DEF_DEF_  "GenSigEnvVarType" "undef";
BA_DEF_DEF_  "GenSigAutoGenSnd" "No";
BA_DEF_DEF_  "GenSigAutoGenDsp" "No";
BA_DEF_DEF_  "GenSigActiveRepetitions" 0;
BA_DEF_DEF_  "GenSigFuncType" "NoFunction";
BA_DEF_DEF_  "Info_BCM_HutHut_Kommunikation" "Nein";
BA_DEF_DEF_  "NWM-WakeupAllowed" "Yes";
BA_DEF_DEF_  "GenSigInactiveValue" "0";
BA_DEF_DEF_  "GenSigMissingSourceValue" 0;
BA_DEF_DEF_  "GenSigStartValue" 0;
BA_DEF_DEF_  "Fehlerwert" 0;
BA_DEF_DEF_  "Bemerkung" "";
BA_DEF_DEF_  "GenSigSendType" "Cyclic";
BA_DEF_DEF_  "NmMessage" "No";
BA_DEF_DEF_  "GenMsgAutoGenSnd" "Yes";
BA_DEF_DEF_  "GenMsgAutoGenDsp" "Yes";
BA_DEF_DEF_  "MsgType" "Broadcast";
BA_DEF_DEF_  "GenMsgChkConstant" 0;
BA_DEF_DEF_  "sim_GenMsgILSupport" "No";
BA_DEF_DEF_  "NWM-Botschaft" "No";
BA_DEF_DEF_  "VAGTP20_StatConnection" "No";
BA_DEF_DEF_  "VAGTP20_DynSetup" "No";
BA_DEF_DEF_  "VAGTP20_DynConnection" "No";
BA_DEF_DEF_  "VAGTP20_API" 1;
BA_DEF_DEF_  "Direkt_1zu1" "Nein";
BA_DEF_DEF_  "GenMsgSendType" "Cyclic";
BA_DEF_DEF_  "DiagResponse" "No";
BA_DEF_DEF_  "DiagRequest" "No";
BA_DEF_DEF_  "GenMsgDelayTime" 0;
BA_DEF_DEF_  "GenMsgStartDelayTime" 0;
BA_DEF_DEF_  "GenMsgILSupport" "No";
BA_DEF_DEF_  "NmhMessage" "No";
BA_DEF_DEF_  "GenMsgNrOfRepetition" 0;
BA_DEF_DEF_  "GenMsgCycleTimeFast" 0;
BA_DEF_DEF_  "DiagState" "No";
BA_DEF_DEF_  "GenMsgCycleTime" 0;
BA_DEF_DEF_REL_ "HYB_Tx_Verwendung" "Rout";
BA_DEF_DEF_REL_ "HYB_Tx_Baureihe" "G1+Derivate";
BA_DEF_DEF_REL_ "GenSigTimeoutTime" 0;
BA_ "GenMsgILSupport" BO_ 17 1;
BA_ "GenMsgSendType" BO_ 17 8;
BA_ "Direkt_1zu1" BO_ 17 1;
BA_ "VAGTP20_API" BO_ 17 0;
BA_ "sim_GenMsgILSupport" BO_ 17 1;
BA_ "MsgType" BO_ 17 1;
BA_ "GenMsgCycleTime" BO_ 1705 1000;
BA_ "GenMsgILSupport" BO_ 1705 1;
BA_ "VAGTP20_API" BO_ 1705 0;
BA_ "sim_GenMsgILSupport" BO_ 1705 1;
BA_ "GenMsgCycleTime" BO_ 1704 1000;
BA_ "GenMsgILSupport" BO_ 1704 1;
BA_ "GenMsgDelayTime" BO_ 1704 100;
BA_ "Direkt_1zu1" BO_ 1704 1;
BA_ "VAGTP20_API" BO_ 1704 0;
BA_ "sim_GenMsgILSupport" BO_ 1704 1;
BA_ "DiagState" BO_ 1792 1;
BA_ "GenMsgSendType" BO_ 1792 8;
BA_ "Direkt_1zu1" BO_ 1792 1;
BA_ "VAGTP20_API" BO_ 1792 0;
BA_ "MsgType" BO_ 1792 5;
BA_ "GenMsgCycleTime" BO_ 1424 200;
BA_ "GenMsgILSupport" BO_ 1424 1;
BA_ "GenMsgDelayTime" BO_ 1424 50;
BA_ "VAGTP20_API" BO_ 1424 0;
BA_ "sim_GenMsgILSupport" BO_ 1424 1;
BA_ "GenMsgCycleTime" BO_ 960 100;
BA_ "GenMsgILSupport" BO_ 960 1;
BA_ "GenMsgDelayTime" BO_ 960 10;
BA_ "Direkt_1zu1" BO_ 960 1;
BA_ "VAGTP20_API" BO_ 960 0;
BA_ "sim_GenMsgILSupport" BO_ 960 1;
BA_ "GenMsgChkConstant" BO_ 960 195;
BA_ "GenMsgCycleTime" BO_ 1137 100;
BA_ "GenMsgILSupport" BO_ 1137 1;
BA_ "Direkt_1zu1" BO_ 1137 1;
BA_ "VAGTP20_API" BO_ 1137 0;
BA_ "sim_GenMsgILSupport" BO_ 1137 1;
BA_ "GenMsgCycleTime" BO_ 1742 200;
BA_ "NmhMessage" BO_ 1742 1;
BA_ "GenMsgSendType" BO_ 1742 8;
BA_ "VAGTP20_API" BO_ 1742 0;
BA_ "MsgType" BO_ 1742 3;
BA_ "GenMsgCycleTime" BO_ 1612 1000;
BA_ "GenMsgILSupport" BO_ 1612 1;
BA_ "VAGTP20_API" BO_ 1612 0;
BA_ "sim_GenMsgILSupport" BO_ 1612 1;
BA_ "GenMsgCycleTime" BO_ 1009 100;
BA_ "GenMsgILSupport" BO_ 1009 1;
BA_ "GenMsgDelayTime" BO_ 1009 10;
BA_ "VAGTP20_API" BO_ 1009 0;
BA_ "sim_GenMsgILSupport" BO_ 1009 1;
BA_ "GenMsgCycleTime" BO_ 1625 500;
BA_ "GenMsgILSupport" BO_ 1625 1;
BA_ "VAGTP20_API" BO_ 1625 0;
BA_ "sim_GenMsgILSupport" BO_ 1625 1;
BA_ "GenMsgCycleTime" BO_ 2617027073 10;
BA_ "GenMsgSendType" BO_ 2617027073 8;
BA_ "Direkt_1zu1" BO_ 2617027073 1;
BA_ "VAGTP20_API" BO_ 2617027073 0;
BA_ "MsgType" BO_ 2617027073 7;
BA_ "GenMsgCycleTime" BO_ 2617027072 10;
BA_ "GenMsgSendType" BO_ 2617027072 8;
BA_ "Direkt_1zu1" BO_ 2617027072 1;
BA_ "VAGTP20_API" BO_ 2617027072 0;
BA_ "MsgType" BO_ 2617027072 7;
BA_ "DiagState" BO_ 1793 1;
BA_ "GenMsgSendType" BO_ 1793 8;
BA_ "Direkt_1zu1" BO_ 1793 1;
BA_ "VAGTP20_API" BO_ 1793 0;
BA_ "MsgType" BO_ 1793 5;
BA_ "DiagState" BO_ 2015 1;
BA_ "GenMsgSendType" BO_ 2015 8;
BA_ "Direkt_1zu1" BO_ 2015 1;
BA_ "VAGTP20_API" BO_ 2015 0;
BA_ "MsgType" BO_ 2015 5;
BA_ "GenMsgCycleTime" BO_ 905 100;
BA_ "GenMsgILSupport" BO_ 905 1;
BA_ "GenMsgDelayTime" BO_ 905 10;
BA_ "VAGTP20_API" BO_ 905 0;
BA_ "sim_GenMsgILSupport" BO_ 905 1;
BA_ "GenMsgILSupport" BO_ 18 1;
BA_ "GenMsgSendType" BO_ 18 8;
BA_ "VAGTP20_API" BO_ 18 0;
BA_ "GenMsgChkConstant" BO_ 18 18;
BA_ "MsgType" BO_ 18 1;
BA_ "DiagResponse" BO_ 1917 1;
BA_ "GenMsgSendType" BO_ 1917 8;
BA_ "Direkt_1zu1" BO_ 1917 1;
BA_ "VAGTP20_API" BO_ 1917 0;
BA_ "MsgType" BO_ 1917 5;
BA_ "DiagResponse" BO_ 2025 1;
BA_ "GenMsgSendType" BO_ 2025 8;
BA_ "Direkt_1zu1" BO_ 2025 1;
BA_ "VAGTP20_API" BO_ 2025 0;
BA_ "MsgType" BO_ 2025 5;
BA_ "DiagResponse" BO_ 2024 1;
BA_ "GenMsgSendType" BO_ 2024 8;
BA_ "Direkt_1zu1" BO_ 2024 1;
BA_ "VAGTP20_API" BO_ 2024 0;
BA_ "MsgType" BO_ 2024 5;
BA_ "GenMsgCycleTime" BO_ 279 20;
BA_ "GenMsgILSupport" BO_ 279 1;
BA_ "Direkt_1zu1" BO_ 279 1;
BA_ "VAGTP20_API" BO_ 279 0;
BA_ "sim_GenMsgILSupport" BO_ 279 1;
BA_ "GenMsgChkConstant" BO_ 279 22;
BA_ "DiagResponse" BO_ 1919 1;
BA_ "GenMsgSendType" BO_ 1919 8;
BA_ "Direkt_1zu1" BO_ 1919 1;
BA_ "VAGTP20_API" BO_ 1919 0;
BA_ "MsgType" BO_ 1919 5;
BA_ "DiagRequest" BO_ 1811 1;
BA_ "GenMsgSendType" BO_ 1811 8;
BA_ "Direkt_1zu1" BO_ 1811 1;
BA_ "VAGTP20_API" BO_ 1811 0;
BA_ "MsgType" BO_ 1811 5;
BA_ "DiagRequest" BO_ 1813 1;
BA_ "GenMsgSendType" BO_ 1813 8;
BA_ "Direkt_1zu1" BO_ 1813 1;
BA_ "VAGTP20_API" BO_ 1813 0;
BA_ "MsgType" BO_ 1813 5;
BA_ "DiagRequest" BO_ 1875 1;
BA_ "GenMsgSendType" BO_ 1875 8;
BA_ "Direkt_1zu1" BO_ 1875 1;
BA_ "VAGTP20_API" BO_ 1875 0;
BA_ "MsgType" BO_ 1875 5;
BA_ "DiagRequest" BO_ 2017 1;
BA_ "GenMsgSendType" BO_ 2017 8;
BA_ "Direkt_1zu1" BO_ 2017 1;
BA_ "VAGTP20_API" BO_ 2017 0;
BA_ "MsgType" BO_ 2017 5;
BA_ "DiagRequest" BO_ 2016 1;
BA_ "GenMsgSendType" BO_ 2016 8;
BA_ "Direkt_1zu1" BO_ 2016 1;
BA_ "VAGTP20_API" BO_ 2016 0;
BA_ "MsgType" BO_ 2016 5;
BA_ "GenMsgCycleTime" BO_ 1630 500;
BA_ "GenMsgILSupport" BO_ 1630 1;
BA_ "VAGTP20_API" BO_ 1630 0;
BA_ "GenMsgCycleTime" BO_ 1607 500;
BA_ "GenMsgILSupport" BO_ 1607 1;
BA_ "Direkt_1zu1" BO_ 1607 1;
BA_ "VAGTP20_API" BO_ 1607 0;
BA_ "GenMsgCycleTime" BO_ 269 20;
BA_ "GenMsgILSupport" BO_ 269 1;
BA_ "Direkt_1zu1" BO_ 269 1;
BA_ "sim_GenMsgILSupport" BO_ 269 1;
BA_ "GenMsgChkConstant" BO_ 269 12;
BA_ "GenMsgCycleTime" BO_ 1719 1000;
BA_ "GenMsgILSupport" BO_ 1719 1;
BA_ "sim_GenMsgILSupport" BO_ 1719 1;
BA_ "GenMsgCycleTime" BO_ 779 50;
BA_ "GenMsgILSupport" BO_ 779 1;
BA_ "sim_GenMsgILSupport" BO_ 779 1;
BA_ "GenMsgCycleTime" BO_ 643 50;
BA_ "GenMsgILSupport" BO_ 643 1;
BA_ "GenMsgDelayTime" BO_ 643 10;
BA_ "VAGTP20_API" BO_ 643 0;
BA_ "sim_GenMsgILSupport" BO_ 643 1;
BA_ "GenMsgCycleTime" BO_ 307 20;
BA_ "GenMsgILSupport" BO_ 307 1;
BA_ "Direkt_1zu1" BO_ 307 1;
BA_ "VAGTP20_API" BO_ 307 0;
BA_ "sim_GenMsgILSupport" BO_ 307 1;
BA_ "GenMsgCycleTime" BO_ 1315 250;
BA_ "GenMsgILSupport" BO_ 1315 1;
BA_ "VAGTP20_API" BO_ 1315 0;
BA_ "sim_GenMsgILSupport" BO_ 1315 1;
BA_ "GenMsgCycleTime" BO_ 390 20;
BA_ "GenMsgILSupport" BO_ 390 1;
BA_ "GenMsgDelayTime" BO_ 390 10;
BA_ "VAGTP20_API" BO_ 390 0;
BA_ "sim_GenMsgILSupport" BO_ 390 1;
BA_ "DiagResponse" BO_ 1981 1;
BA_ "GenMsgSendType" BO_ 1981 8;
BA_ "Direkt_1zu1" BO_ 1981 1;
BA_ "VAGTP20_API" BO_ 1981 0;
BA_ "MsgType" BO_ 1981 5;
BA_ "GenMsgCycleTime" BO_ 910 100;
BA_ "GenMsgILSupport" BO_ 910 1;
BA_ "VAGTP20_API" BO_ 910 0;
BA_ "sim_GenMsgILSupport" BO_ 910 1;
BA_ "GenMsgCycleTime" BO_ 787 50;
BA_ "GenMsgILSupport" BO_ 787 1;
BA_ "VAGTP20_API" BO_ 787 0;
BA_ "sim_GenMsgILSupport" BO_ 787 1;
BA_ "GenSigSendType" SG_ 17 WFS_IMS_MSG1 3;
BA_ "Bemerkung" SG_ 1705 KBI_Fzg_ID_10 "10. Stelle der Fahrgestellnummer. ASCII codiert.";
BA_ "Bemerkung" SG_ 1705 KBI_Fzg_ID_11 "11. Stelle der Fahrgestellnummer. ASCII codiert.";
BA_ "Bemerkung" SG_ 1705 KBI_Fzg_ID_12 "12. Stelle der Fahrgestellnummer. BCD codiert.";
BA_ "Bemerkung" SG_ 1705 KBI_Fzg_ID_13 "13. Stelle der Fahrgestellnummer. BCD codiert.";
BA_ "Bemerkung" SG_ 1705 KBI_Fzg_ID_14 "14. Stelle der Fahrgestellnummer. BCD codiert.";
BA_ "Bemerkung" SG_ 1705 KBI_Fzg_ID_15 "15. Stelle der Fahrgestellnummer. BCD codiert.";
BA_ "Bemerkung" SG_ 1705 KBI_Fzg_ID_16 "16. Stelle der Fahrgestellnummer. BCD codiert.";
BA_ "Bemerkung" SG_ 1705 KBI_Fzg_ID_17 "17. Stelle der Fahrgestellnummer. BCD codiert.";
BA_ "Bemerkung" SG_ 1705 KBI_Fzg_ID_4 "4. Stelle der Fahrgestellnummer. ASCII codiert.";
BA_ "GenSigMissingSourceValue" SG_ 1705 KBI_Fzg_ID_4 255;
BA_ "Bemerkung" SG_ 1705 KBI_Fzg_ID_5 "5. Stelle der Fahrgestellnummer. ASCII codiert.";
BA_ "Bemerkung" SG_ 1705 KBI_Fzg_ID_8 "8. Stelle der Fahrgestellnummer. BCD codiert.";
BA_ "NWM-WakeupAllowed" SG_ 1704 KBI_Steigerung_Luftmenge_Fond 0;
BA_ "GenSigSendType" SG_ 1704 KBI_Steigerung_Luftmenge_Fond 3;
BA_ "NWM-WakeupAllowed" SG_ 1704 KBI_PTC_Zuheizer 0;
BA_ "GenSigSendType" SG_ 1704 KBI_PTC_Zuheizer 3;
BA_ "NWM-WakeupAllowed" SG_ 1704 KBI_FLA_GLW_Aktiv 0;
BA_ "GenSigSendType" SG_ 1704 KBI_FLA_GLW_Aktiv 3;
BA_ "GenSigSendType" SG_ 1704 KBI_ASD_innen 3;
BA_ "GenSigSendType" SG_ 1704 KBI_ASD_aussen 3;
BA_ "NWM-WakeupAllowed" SG_ 1704 KBI_LDW_aktiv 0;
BA_ "GenSigSendType" SG_ 1704 KBI_LDW_aktiv 3;
BA_ "NWM-WakeupAllowed" SG_ 1704 KBI_Jokerkey_Hupe_Aktiv 0;
BA_ "GenSigSendType" SG_ 1704 KBI_Jokerkey_Hupe_Aktiv 3;
BA_ "GenSigSendType" SG_ 1704 KBI_Automem_inaktiv 3;
BA_ "GenSigSendType" SG_ 1704 KBI_Heckrollo_b_R 3;
BA_ "Bemerkung" SG_ 1704 KBI_Klimastyles "Defaultwert=1";
BA_ "GenSigSendType" SG_ 1704 KBI_Klimastyles 3;
BA_ "Bemerkung" SG_ 1704 KBI_WV_Entr_Kof "Defaultwert=4";
BA_ "GenSigSendType" SG_ 1704 KBI_WV_Entr_Kof 3;
BA_ "Bemerkung" SG_ 1704 KBI_Carjack "Defaultwert=0";
BA_ "GenSigSendType" SG_ 1704 KBI_Carjack 3;
BA_ "Bemerkung" SG_ 1704 KBI_Tuerentr_T "Defaultwert=0";
BA_ "GenSigSendType" SG_ 1704 KBI_Tuerentr_T 3;
BA_ "Bemerkung" SG_ 1704 KBI_Einstiegshilfe_aktiv "Defaultwert=1";
BA_ "GenSigSendType" SG_ 1704 KBI_Einstiegshilfe_aktiv 3;
BA_ "Bemerkung" SG_ 1704 KBI_FULL_AFS_Tourist "Defaultwert=0";
BA_ "GenSigSendType" SG_ 1704 KBI_FULL_AFS_Tourist 3;
BA_ "GenSigSendType" SG_ 1704 KBI_Aussenspiegel_einklapp_auto 3;
BA_ "GenSigSendType" SG_ 1704 KBI_Aussenspiegel_absenken_auto 3;
BA_ "Bemerkung" SG_ 1704 KBI_Heckw_b_R "Defaultwert=1";
BA_ "GenSigSendType" SG_ 1704 KBI_Heckw_b_R 3;
BA_ "Bemerkung" SG_ 1704 KBI_TFL_akt "(Nur in Ländern bei denen kein TFL gefordert ist.) ; Defaultwert=0";
BA_ "GenSigSendType" SG_ 1704 KBI_TFL_akt 3;
BA_ "Bemerkung" SG_ 1704 KBI_Nachleucht "Bei Fehlerwert keinen Fehlercode ablegen! Defaultwert=6";
BA_ "GenSigMissingSourceValue" SG_ 1704 KBI_Nachleucht 31;
BA_ "GenSigSendType" SG_ 1704 KBI_Nachleucht 3;
BA_ "Bemerkung" SG_ 1704 KBI_WV_Entr "Bei Fehlerwert keinen Fehlercode ablegen! Defaultwert=10";
BA_ "GenSigSendType" SG_ 1704 KBI_WV_Entr 3;
BA_ "GenSigSendType" SG_ 1704 KBI_Erw_BelueftFeld 3;
BA_ "GenSigSendType" SG_ 1704 KBI_Mittenduesentemp 3;
BA_ "Bemerkung" SG_ 1704 KBI_Nachleucht_IL "Bei Fehlerwert keinen Fehlercode ablegen! Defaultwert=12";
BA_ "GenSigSendType" SG_ 1704 KBI_Nachleucht_IL 3;
BA_ "GenSigSendType" SG_ 1704 KBI_Auto_Umluft 3;
BA_ "GenSigSendType" SG_ 1704 KBI_Schaltpkt_Anz_ein 3;
BA_ "Bemerkung" SG_ 1704 KBI_RS_d_akt "Default=1";
BA_ "GenSigSendType" SG_ 1704 KBI_RS_d_akt 3;
BA_ "Bemerkung" SG_ 1704 KBI_Dimmung_OriLicht "Defaultwert=50";
BA_ "GenSigSendType" SG_ 1704 KBI_Dimmung_OriLicht 3;
BA_ "GenSigSendType" SG_ 1792 Diag_Rq_Fktnl_Data_UDS 7;
BA_ "NWM-WakeupAllowed" SG_ 1424 KYL_Warn_Notzuendschloss 0;
BA_ "NWM-WakeupAllowed" SG_ 1424 KYL_Notzuendschloss 0;
BA_ "GenSigSendType" SG_ 1424 KY_StartStopp_Info 3;
BA_ "GenSigSendType" SG_ 1424 KY_Funkschl_Nr 3;
BA_ "GenSigSendType" SG_ 1424 KY_ID_Geb_autorisiert 3;
BA_ "GenSigSendType" SG_ 1424 KY_ID_Geb_steckt 3;
BA_ "GenSigSendType" SG_ 1424 KY_FFB_Frequenz 3;
BA_ "GenSigSendType" SG_ 1424 KY_HF_Aktiv 3;
BA_ "GenSigSendType" SG_ 1424 KY_LF_Aktiv 3;
BA_ "GenSigSendType" SG_ 1424 KY_ELV_verr 3;
BA_ "GenSigSendType" SG_ 1424 KY_ELV_entr 3;
BA_ "GenSigSendType" SG_ 1424 KY_ELV_enable_Anforderung 3;
BA_ "GenSigSendType" SG_ 1424 KY_Valet_Parking 3;
BA_ "GenSigSendType" SG_ 1424 KY_Keyless_Verbau 3;
BA_ "GenSigSendType" SG_ 1424 KY_FBS_Fahrer_Hinweise 3;
BA_ "GenSigSendType" SG_ 1424 FBS_Warn_Lenkung_def 3;
BA_ "GenSigSendType" SG_ 1424 FBS_Warn_LenkVerriegelung_def 3;
BA_ "GenSigSendType" SG_ 1424 FBS_Warn_Schluessel_Batt 3;
BA_ "GenSigSendType" SG_ 1424 FBS_Prio_Warn_04 3;
BA_ "GenSigSendType" SG_ 1424 FBS_Prio_Warn_05 3;
BA_ "GenSigSendType" SG_ 1424 KY_KYL_Fahrer_Hinweise 3;
BA_ "GenSigSendType" SG_ 1424 KYL_Warn_kein_Schluessel 3;
BA_ "GenSigSendType" SG_ 1424 KYL_Warn_Kessy_defekt 3;
BA_ "GenSigSendType" SG_ 1424 KY_KYL_Prio_Warn_03 3;
BA_ "GenSigSendType" SG_ 1424 KY_KYL_Prio_Warn_04 3;
BA_ "GenSigSendType" SG_ 1424 KY_KYL_Prio_Warn_05 3;
BA_ "GenSigSendType" SG_ 1424 KY_Schluessel_Soll 3;
BA_ "GenSigSendType" SG_ 1424 KY_Schluessel_Ist 3;
BA_ "GenSigSendType" SG_ 1424 KY_WFS_Safe 3;
BA_ "GenSigSendType" SG_ 1424 KY_WFS_LZ 3;
BA_ "GenSigSendType" SG_ 1424 FBS_KD_Fehler 3;
BA_ "NWM-WakeupAllowed" SG_ 1424 SK_Anf_DTC_Abfrage_sofort 0;
BA_ "GenSigSendType" SG_ 1424 SK_Anf_DTC_Abfrage_sofort 3;
BA_ "NWM-WakeupAllowed" SG_ 1424 SK_Anf_DTC_Abfrage 0;
BA_ "GenSigSendType" SG_ 1424 SK_Anf_DTC_Abfrage 3;
BA_ "NWM-WakeupAllowed" SG_ 960 ZV_verriegelt_extern_soll_02 0;
BA_ "GenSigFuncType" SG_ 960 Klemmen_Status_01_CHK 3;
BA_ "GenSigFuncType" SG_ 960 Klemmen_Status_01_BZ 1;
BA_ "GenSigSendType" SG_ 960 ZAS_Kl_S 3;
BA_ "GenSigFuncType" SG_ 960 ZAS_Kl_15 6;
BA_ "GenSigSendType" SG_ 960 ZAS_Kl_15 3;
BA_ "GenSigSendType" SG_ 960 ZAS_Kl_X 3;
BA_ "GenSigSendType" SG_ 960 ZAS_Kl_50 3;
BA_ "NWM-WakeupAllowed" SG_ 1137 LH_Aussenlicht_def 0;
BA_ "NWM-WakeupAllowed" SG_ 1137 LH_Standlicht_H_aktiv 0;
BA_ "NWM-WakeupAllowed" SG_ 1137 LH_SL_BRL_BLK_re_def 0;
BA_ "NWM-WakeupAllowed" SG_ 1137 LH_SL_BRL_BLK_li_def 0;
BA_ "NWM-WakeupAllowed" SG_ 1137 LH_Schluss_Nebel_re_def 0;
BA_ "NWM-WakeupAllowed" SG_ 1137 LH_Schluss_Nebel_li_def 0;
BA_ "NWM-WakeupAllowed" SG_ 1137 LH_Schluss_Brems_re_def 0;
BA_ "NWM-WakeupAllowed" SG_ 1137 LH_Schluss_Brems_Nebel_re_def 0;
BA_ "NWM-WakeupAllowed" SG_ 1137 LH_Schluss_Brems_Nebel_li_def 0;
BA_ "NWM-WakeupAllowed" SG_ 1137 LH_Schluss_Brems_li_def 0;
BA_ "NWM-WakeupAllowed" SG_ 1137 LH_Rueckfahrlicht_aktiv 0;
BA_ "NWM-WakeupAllowed" SG_ 1137 LH_Rueckf_mi_def 0;
BA_ "NWM-WakeupAllowed" SG_ 1137 LH_Parklicht_HR_aktiv 0;
BA_ "NWM-WakeupAllowed" SG_ 1137 LH_Parklicht_HL_aktiv 0;
BA_ "NWM-WakeupAllowed" SG_ 1137 LH_Nebelschluss_aktiv 0;
BA_ "NWM-WakeupAllowed" SG_ 1137 LH_Nebel_mi_def 0;
BA_ "NWM-WakeupAllowed" SG_ 1137 LH_Bremslicht_H_aktiv 0;
BA_ "NWM-WakeupAllowed" SG_ 1137 LH_Brems_Blk_re_def 0;
BA_ "NWM-WakeupAllowed" SG_ 1137 LH_Brems_Blk_li_def 0;
BA_ "NWM-WakeupAllowed" SG_ 1137 LH_Blinker_re_def 0;
BA_ "NWM-WakeupAllowed" SG_ 1137 LH_Blinker_li_def 0;
BA_ "NWM-WakeupAllowed" SG_ 1137 LH_Blinker_HR_akt 0;
BA_ "NWM-WakeupAllowed" SG_ 1137 LH_Blinker_HL_akt 0;
BA_ "NWM-WakeupAllowed" SG_ 1137 LH_Bremsl_re_ges_def 0;
BA_ "NWM-WakeupAllowed" SG_ 1137 LH_Bremsl_li_ges_def 0;
BA_ "GenSigFuncType" SG_ 1137 Licht_hinten_01_BZ 1;
BA_ "NWM-WakeupAllowed" SG_ 1742 NMH_BMS_NL_Daten_EEPROM 0;
BA_ "NWM-WakeupAllowed" SG_ 1742 NMH_BMS_NL_Luefter 0;
BA_ "NWM-WakeupAllowed" SG_ 1742 NMH_BMS_Signalfehler 0;
BA_ "NWM-WakeupAllowed" SG_ 1742 NMH_BMS_TimeOut_Fehler 0;
BA_ "NWM-WakeupAllowed" SG_ 1742 NMH_BMS_CAN_Diag_deaktiv 0;
BA_ "NWM-WakeupAllowed" SG_ 1742 NMH_BMS_KompSchutz 0;
BA_ "NWM-WakeupAllowed" SG_ 1742 NMH_BMS_Mute_Mode 0;
BA_ "NWM-WakeupAllowed" SG_ 1742 NMH_BMS_Transport_Mode 0;
BA_ "NWM-WakeupAllowed" SG_ 1742 NMH_BMS_Abschaltstufe_aktiv 0;
BA_ "NWM-WakeupAllowed" SG_ 1742 NMH_BMS_Busfehler 0;
BA_ "NWM-WakeupAllowed" SG_ 1742 NMH_BMS_Lokalaktiv 0;
BA_ "NWM-WakeupAllowed" SG_ 1742 NMH_BMS_Subsystemaktiv 0;
BA_ "NWM-WakeupAllowed" SG_ 1742 NMH_BMS_Start_1 0;
BA_ "NWM-WakeupAllowed" SG_ 1742 NMH_BMS_Start_2 0;
BA_ "NWM-WakeupAllowed" SG_ 1742 NMH_BMS_Normal_Mode_1 0;
BA_ "NWM-WakeupAllowed" SG_ 1742 NMH_BMS_Normal_Mode_2 0;
BA_ "NWM-WakeupAllowed" SG_ 1742 NMH_BMS_Car_WakeUp 0;
BA_ "NWM-WakeupAllowed" SG_ 1742 NMH_BMS_Klemme_15 0;
BA_ "NWM-WakeupAllowed" SG_ 1742 NMH_BMS_Diagnose 0;
BA_ "NWM-WakeupAllowed" SG_ 1742 NMH_BMS_MindestAktivZeit 0;
BA_ "GenSigMissingSourceValue" SG_ 1612 GW_Fzg_Antrieb 15;
BA_ "GenSigMissingSourceValue" SG_ 1612 GW_Karosserie_Typ 15;
BA_ "GenSigMissingSourceValue" SG_ 1612 GW_Baureihe 15;
BA_ "GenSigMissingSourceValue" SG_ 1612 GW_Lenker 15;
BA_ "GenSigSendType" SG_ 1009 FSAktivBit 3;
BA_ "Fehlerwert" SG_ 1625 EKL_Comp_photo_temp 255;
BA_ "GenSigStartValue" SG_ 1625 EKL_Comp_photo_temp 255;
BA_ "Fehlerwert" SG_ 1625 EKL_Comp_current 255;
BA_ "GenSigStartValue" SG_ 1625 EKL_Comp_current 255;
BA_ "Fehlerwert" SG_ 1625 EKL_Comp_rev_stat 255;
BA_ "GenSigSendType" SG_ 2617027073 AB_EB2_Tx_Data 7;
BA_ "GenSigSendType" SG_ 2617027072 AB_EB1_Tx_Data 7;
BA_ "GenSigSendType" SG_ 1793 Diag_Rq_Fktnl_Data_KWP2000 7;
BA_ "GenSigSendType" SG_ 2015 Diag_Rq_Fktnl_Data_OBD 7;
BA_ "GenSigStartValue" SG_ 905 EPB_QBit_Schalterpos 1;
BA_ "NWM-WakeupAllowed" SG_ 905 KL_Segeln_Anf_deaktivieren 0;
BA_ "GenSigSendType" SG_ 905 KL_T_Abgasklappe 3;
BA_ "Bemerkung" SG_ 905 KL_Drehz_Anh "0=keine Drehzahlanhebung; 1=Drehzahlanhebung";
BA_ "Bemerkung" SG_ 905 KL_Anf_KL "Ansteuerung des Kuehlerluefters in Prozent";
BA_ "Fehlerwert" SG_ 905 KL_KaeltemittelDruck 255;
BA_ "GenSigMissingSourceValue" SG_ 905 DK_St_PAO_Leuchte 3;
BA_ "GenSigSendType" SG_ 905 KL_Sportmodus 3;
BA_ "GenSigStartValue" SG_ 905 F_EPB_01_Ant 1;
BA_ "GenSigStartValue" SG_ 905 F_Klima_03_Ant 1;
BA_ "GenSigSendType" SG_ 905 KL_T_PSM_off 3;
BA_ "GenSigStartValue" SG_ 905 F_Klima_01_1_Ant 1;
BA_ "GenSigStartValue" SG_ 905 F_Klima_08_1_PAG_Ant 1;
BA_ "GenSigStartValue" SG_ 905 F_BCM2_03_PAG_Ant 1;
BA_ "Fehlerwert" SG_ 905 KL_Last_Kompr 255;
BA_ "GenSigSendType" SG_ 905 KL_STH_Ansteuerung 3;
BA_ "GenSigSendType" SG_ 905 KL_STH_aktiv 3;
BA_ "NWM-WakeupAllowed" SG_ 18 WFS_GSG_RND 0;
BA_ "GenSigSendType" SG_ 18 WFS_GSG_RND 1;
BA_ "NWM-WakeupAllowed" SG_ 18 WFS_GSG_CRC 0;
BA_ "GenSigFuncType" SG_ 18 WFS_GSG_CRC 2;
BA_ "GenSigSendType" SG_ 18 WFS_GSG_CRC 7;
BA_ "GenSigSendType" SG_ 1917 Diag_Rs_DLSNFS_PSM 7;
BA_ "GenSigSendType" SG_ 1917 Diag_Rs_PCItype_PSM 7;
BA_ "GenSigSendType" SG_ 1917 Diag_Rs_Data_PSM 7;
BA_ "GenSigSendType" SG_ 2025 ISO_Getriebe_01_Resp_Data 7;
BA_ "GenSigSendType" SG_ 2024 ISO_MO_01_Resp_Data 7;
BA_ "GenSigStartValue" SG_ 279 ANB_Zielbrems_Teilbrems_Verz_Anf 834;
BA_ "GenSigFuncType" SG_ 279 ACC_10_CHK 3;
BA_ "GenSigFuncType" SG_ 279 ACC_10_BZ 1;
BA_ "Bemerkung" SG_ 279 AWV2_Priowarnung "Signal momentan nur als Vorhalt. Wird immer mit '0' befüllt.";
BA_ "GenSigSendType" SG_ 1919 Diag_Rs_DLSNFS_Airbag 7;
BA_ "GenSigSendType" SG_ 1919 Diag_Rs_PCItype_Airbag 7;
BA_ "GenSigSendType" SG_ 1919 Diag_Rs_Data_Airbag 7;
BA_ "GenSigSendType" SG_ 1811 Diag_Rq_DLSNFS_PSM 7;
BA_ "GenSigSendType" SG_ 1811 Diag_Rq_PCItype_PSM 7;
BA_ "GenSigSendType" SG_ 1811 Diag_Rq_Data_PSM 7;
BA_ "GenSigSendType" SG_ 1813 Diag_Rq_Data_Airbag 7;
BA_ "GenSigSendType" SG_ 1813 Diag_Rq_DLSNFS_Airbag 7;
BA_ "GenSigSendType" SG_ 1813 Diag_Rq_PCItype_Airbag 7;
BA_ "GenSigSendType" SG_ 1875 Diag_Rq_DLSNFS_Waehlhebel 7;
BA_ "GenSigSendType" SG_ 1875 Diag_Rq_PCItype_Waehlhebel 7;
BA_ "GenSigSendType" SG_ 1875 Diag_Rq_Data_Waehlhebel 7;
BA_ "GenSigSendType" SG_ 2017 Diag_Rq_PCItype_PDK_OBD 7;
BA_ "GenSigSendType" SG_ 2017 Diag_Rq_DLSNFS_PDK_OBD 7;
BA_ "GenSigSendType" SG_ 2017 Diag_Rq_Data_PDK_OBD 7;
BA_ "GenSigSendType" SG_ 2016 Diag_Rq_PCItype_Motor_OBD 7;
BA_ "GenSigSendType" SG_ 2016 Diag_Rq_DLSNFS_Motor_OBD 7;
BA_ "GenSigSendType" SG_ 2016 Diag_Rq_Data_Motor_OBD 7;
BA_ "NWM-WakeupAllowed" SG_ 1630 OBD_TG_F_Status_1 0;
BA_ "NWM-WakeupAllowed" SG_ 1630 OBD_TG_F_Status_2 0;
BA_ "NWM-WakeupAllowed" SG_ 1630 OBD_TG_F_Status_3 0;
BA_ "NWM-WakeupAllowed" SG_ 1630 OBD_TG_F_Status_4 0;
BA_ "NWM-WakeupAllowed" SG_ 1630 OBD_TG_Sens_Rohwert_1 0;
BA_ "NWM-WakeupAllowed" SG_ 1630 OBD_TG_Sens_Rohwert_2 0;
BA_ "NWM-WakeupAllowed" SG_ 1630 OBD_TG_Sens_Rohwert_3 0;
BA_ "NWM-WakeupAllowed" SG_ 1630 OBD_TG_Sens_Rohwert_4 0;
BA_ "NWM-WakeupAllowed" SG_ 1607 MO_Kraftstofffilter_Wasser 0;
BA_ "Fehlerwert" SG_ 1607 MO_ITM_Kuehlmittel_Temp 2;
BA_ "GenSigStartValue" SG_ 1607 MO_ITM_Kuehlmittel_Temp 1;
BA_ "NWM-WakeupAllowed" SG_ 1607 MO_ITM_Kuehlmittel_Temp 0;
BA_ "Fehlerwert" SG_ 1607 MO_CO2_Faktor 4095;
BA_ "NWM-WakeupAllowed" SG_ 1607 MO_CO2_Faktor 0;
BA_ "Fehlerwert" SG_ 1607 MO_E85_Sensor 15;
BA_ "GenSigStartValue" SG_ 1607 MO_E85_Sensor 14;
BA_ "NWM-WakeupAllowed" SG_ 1607 MO_E85_Sensor 0;
BA_ "GenSigStartValue" SG_ 1607 SCR_Anz_Motorstarts 15;
BA_ "NWM-WakeupAllowed" SG_ 1607 SCR_Anz_Motorstarts 0;
BA_ "GenSigStartValue" SG_ 1607 SCR_Reichweite 32767;
BA_ "NWM-WakeupAllowed" SG_ 1607 SCR_Reichweite 0;
BA_ "NWM-WakeupAllowed" SG_ 1607 SCR_Warnstufe_1 0;
BA_ "NWM-WakeupAllowed" SG_ 1607 SCR_Warnstufe_2 0;
BA_ "NWM-WakeupAllowed" SG_ 1607 SCR_Inducement_Strategie 0;
BA_ "NWM-WakeupAllowed" SG_ 1607 MO_MKB_MUX 0;
BA_ "NWM-WakeupAllowed" SG_ 1607 MO_MKB_01 0;
BA_ "NWM-WakeupAllowed" SG_ 1607 MO_MKB_02 0;
BA_ "NWM-WakeupAllowed" SG_ 1607 SCR_Text 0;
BA_ "NWM-WakeupAllowed" SG_ 1607 SCR_Akustik 0;
BA_ "NWM-WakeupAllowed" SG_ 1607 SCR_Systemfehler 0;
BA_ "NWM-WakeupAllowed" SG_ 1607 MO_MKB_04 0;
BA_ "NWM-WakeupAllowed" SG_ 1607 MO_MKB_03 0;
BA_ "NWM-WakeupAllowed" SG_ 269 ACC_Vorbefuellung_Bremsanlage 0;
BA_ "GenSigStartValue" SG_ 269 ACC_ax_Getriebe 84;
BA_ "GenSigStartValue" SG_ 269 ACC_Verz_anf 1444;
BA_ "GenSigFuncType" SG_ 269 ACC_05_CHK 3;
BA_ "GenSigFuncType" SG_ 269 ACC_05_BZ 1;
BA_ "GenSigStartValue" SG_ 1719 KBI_QBit_Aussen_Temp_gef 1;
BA_ "Fehlerwert" SG_ 1719 KBI_Kilometerstand 1048575;
BA_ "GenSigStartValue" SG_ 1719 KBI_Kilometerstand 1048574;
BA_ "Fehlerwert" SG_ 1719 KBI_Aussen_Temp_gef 255;
BA_ "GenSigStartValue" SG_ 1719 KBI_Aussen_Temp_gef 254;
BA_ "Fehlerwert" SG_ 1719 KBI_Inhalt_Tank 127;
BA_ "GenSigMissingSourceValue" SG_ 1719 KBI_Inhalt_Tank 127;
BA_ "NWM-WakeupAllowed" SG_ 779 KBI_Anzeigefehler_LDW 0;
BA_ "GenSigAutoGenDsp" SG_ 779 KBI_Anzeigefehler_LDW 1;
BA_ "GenSigAutoGenSnd" SG_ 779 KBI_Anzeigefehler_LDW 1;
BA_ "GenSigEnvVarType" SG_ 779 KBI_Anzeigefehler_LDW 0;
BA_ "NWM-WakeupAllowed" SG_ 779 KBI_MFA_v_Einheit_01 0;
BA_ "NWM-WakeupAllowed" SG_ 779 KBI_Anzeigefehler_SWA 0;
BA_ "Fehlerwert" SG_ 779 KBI_angez_Geschw 1023;
BA_ "GenSigStartValue" SG_ 779 KBI_Airbag_Lampe 1;
BA_ "Fehlerwert" SG_ 643 AB_AWS_Zustand 7;
BA_ "Bemerkung" SG_ 307 WHL_KD_Fehler "1=Fehler im Fehlerspeicher abgelegt ";
BA_ "GenSigFuncType" SG_ 307 WHL_CHK 4;
BA_ "GenSigFuncType" SG_ 307 WHL_BZ 1;
BA_ "Fehlerwert" SG_ 307 WHL_Pos 15;
BA_ "NWM-WakeupAllowed" SG_ 1315 SVB_Lift 0;
BA_ "NWM-WakeupAllowed" SG_ 1315 SVB_HAL 0;
BA_ "GenSigSendType" SG_ 390 BR_StartStopp_Info 3;
BA_ "Bemerkung" SG_ 390 BR_St_esp_dia "0: ESP nicht in Diagnose (EBV-, ABS-Sila und ESP-Mufla aus); 1: ESP in Diagnose (EBV-, ABS-Sila und ESP-Mufla blinken)";
BA_ "Bemerkung" SG_ 390 BR_mimsr "Keine MSR-Anforderung:00h..Fh = Botschaftszähler (BZ) - Zähler zählt nur bis 15!! MSR-Anforderung: 00h .. FEh = Wertebereich, Fehlerwert FFh wird nicht unterstützt";
BA_ "Bemerkung" SG_ 390 BR_miasrs "Keine MSR- und ASR-Anforderung (inaktiver Zustand): FEh, ASR-Anforderung: 00h .. FDh = Wertebereich, Fehlerwert FFh wird nicht unterstützt, MSR-Anforderung: (mimsr + BZ) bitinvertiert";
BA_ "Bemerkung" SG_ 390 BR_miasrl "Keine MSR- und ASR-Anforderung (inaktiver Zustand): FEh, ASR-Anforderung: 00h .. FDh = Wertebereich, Fehlerwert FFh wird nicht unterstützt, MSR-Anforderung:  00h .. Fh = Botschaftszähler (BZ) - Zähler zählt nur bis 15!!";
BA_ "Bemerkung" SG_ 390 BR_St_esp_pas "0: ESP aktiv (ESP-Mufla aus); 1: ESP passiv (ESP-Mufla an)";
BA_ "GenSigSendType" SG_ 390 BR_St_esp_pas 3;
BA_ "Bemerkung" SG_ 390 BR_St_msr "0: keine MSR-Anforderung; 1: MSR-Anforderung (siehe Signal 'mimsr')";
BA_ "Bemerkung" SG_ 390 BR_F_esp "0: ESP-Mufla aus; 1: ESP-Mufla an";
BA_ "Bemerkung" SG_ 390 BR_St_esp_info "0: ESP-Mufla aus; 1: ESP-Mufla blinkt";
BA_ "Bemerkung" SG_ 390 BR_St_esp "0: keine ESP-Eingriff; 1: ESP-Eingriff";
BA_ "Bemerkung" SG_ 390 BR_F_ebv "0: EBV-Sila aus; 1: EBV-Sila an";
BA_ "Bemerkung" SG_ 390 BR_S_BremsT "S_BremsL (HB) und S_BremsT (LB); 0: Bremspedal nicht betätigt; 1: Reserve; 2: Fehler / nicht plausibel; 3: Bremspedal betätigt";
BA_ "Bemerkung" SG_ 390 BR_S_BremsL "S_BremsL (HB) und S_BremsT (LB); 0: Bremspedal nicht betätigt; 1: Reserve; 2: Fehler / nicht plausibel; 3: Bremspedal betätigt";
BA_ "Bemerkung" SG_ 390 BR_St_asr "0: keine ASR-Anforderung; 1: ASR-Anforderung (siehe Signale  'miasrl' und 'miasrs')";
BA_ "Bemerkung" SG_ 390 BR_F_abs "0: ABS-Sila aus; 1: ABS-Sila an";
BA_ "Bemerkung" SG_ 390 BR_St_abs "0: keine ABS-Bremsung; 1: ABS-Bremsung";
BA_ "Bemerkung" SG_ 390 BR_St_bmr "0: keine Bremsmomenten-Eingriff; 1: Bremsmomenten-Eingriff";
BA_ "Bemerkung" SG_ 390 BR_asrb "0: keine Schaltbeeinflussung; 1: Schaltverbot";
BA_ "Bemerkung" SG_ 390 ESP_v_Signal "Signal ist eine aus den Radgeschwindigkeiten gebildete Geschwindigkeit";
BA_ "Fehlerwert" SG_ 390 ESP_v_Signal 65535;
BA_ "GenSigStartValue" SG_ 390 ESP_v_Signal 65534;
BA_ "GenSigMissingSourceValue" SG_ 390 ESP_v_Signal 65535;
BA_ "GenSigSendType" SG_ 1981 Diag_Rs_DLSNFS_Waehlhebel 7;
BA_ "GenSigSendType" SG_ 1981 Diag_Rs_PCItype_Waehlhebel 7;
BA_ "GenSigSendType" SG_ 1981 Diag_Rs_Data_Waehlhebel 7;
BA_ "Fehlerwert" SG_ 910 KBI_angez_Geschw 1023;
BA_ "GenSigStartValue" SG_ 910 F_Kombi_02_Ant 1;
BA_ "Fehlerwert" SG_ 910 KBI_Aussen_Temp_gef 255;
BA_ "GenSigStartValue" SG_ 910 KBI_Aussen_Temp_gef 254;
BA_ "Fehlerwert" SG_ 910 KBI_Inhalt_Tank 127;
BA_ "GenSigMissingSourceValue" SG_ 910 KBI_Inhalt_Tank 127;
BA_ "GenSigStartValue" SG_ 910 F_Kombi_11_PAG_Ant 1;
BA_ "GenSigStartValue" SG_ 910 F_Klima_08_PAG_Ant 1;
BA_ "Fehlerwert" SG_ 910 KL_Atemp_ungef 255;
BA_ "GenSigStartValue" SG_ 910 F_Kombi_01_Ant 1;
BA_ "GenSigStartValue" SG_ 910 KBI_Airbag_Lampe 1;
BA_ "GenSigMissingSourceValue" SG_ 910 KBI_Fotosensor 255;
BA_ "GenSigStartValue" SG_ 910 F_Anhaenger_01_Ant 1;
BA_ "GenSigStartValue" SG_ 787 F_PDCC_01_Ant 1;
BA_ "Fehlerwert" SG_ 787 PDCC_Last_RKP 255;
BA_ "GenSigStartValue" SG_ 787 ACC_05_alt 1;
BA_ "GenSigStartValue" SG_ 787 F_PCM_CDR_01_Ant 1;
BA_ "Fehlerwert" SG_ 787 HU_Fotosensor 511;
BA_ "GenSigSendType" SG_ 787 BH_Blinker_re 3;
BA_ "GenSigSendType" SG_ 787 BH_Blinker_li 3;
BA_ "GenSigStartValue" SG_ 787 F_Kombi_02_1_Ant 1;
BA_ "GenSigStartValue" SG_ 787 F_SMLS_01_Ant 1;
BA_REL_ "GenSigTimeoutTime" BU_SG_REL_ Motor_EDC17_Pirol SG_ 17 WFS_IMS_MSG1 500;
BA_REL_ "GenSigTimeoutTime" BU_SG_REL_ Motor_MED17_Hybrid SG_ 17 WFS_IMS_MSG1 500;
BA_REL_ "GenSigTimeoutTime" BU_SG_REL_ Waehlhebel SG_ 1705 KBI_Fzg_ID_10 5000;
BA_REL_ "GenSigTimeoutTime" BU_SG_REL_ Waehlhebel SG_ 1705 KBI_Fzg_ID_11 5000;
BA_REL_ "GenSigTimeoutTime" BU_SG_REL_ Waehlhebel SG_ 1705 KBI_Fzg_ID_12 5000;
BA_REL_ "GenSigTimeoutTime" BU_SG_REL_ Waehlhebel SG_ 1705 KBI_Fzg_ID_13 5000;
BA_REL_ "GenSigTimeoutTime" BU_SG_REL_ Waehlhebel SG_ 1705 KBI_Fzg_ID_14 5000;
BA_REL_ "GenSigTimeoutTime" BU_SG_REL_ Waehlhebel SG_ 1705 KBI_Fzg_ID_15 5000;
BA_REL_ "GenSigTimeoutTime" BU_SG_REL_ Waehlhebel SG_ 1705 KBI_Fzg_ID_16 5000;
BA_REL_ "GenSigTimeoutTime" BU_SG_REL_ Waehlhebel SG_ 1705 KBI_Fzg_ID_17 5000;
BA_REL_ "GenSigTimeoutTime" BU_SG_REL_ Waehlhebel SG_ 1705 KBI_Fzg_ID_4 5000;
BA_REL_ "GenSigTimeoutTime" BU_SG_REL_ Waehlhebel SG_ 1705 KBI_Fzg_ID_5 5000;
BA_REL_ "GenSigTimeoutTime" BU_SG_REL_ Waehlhebel SG_ 1705 KBI_Fzg_ID_8 5000;
BA_REL_ "GenSigTimeoutTime" BU_SG_REL_ Ladegeraet_PAG_PF SG_ 1792 Diag_Rq_Fktnl_Data_UDS 500;
BA_REL_ "GenSigTimeoutTime" BU_SG_REL_ Motor_EDC17_Pirol SG_ 1792 Diag_Rq_Fktnl_Data_UDS 500;
BA_REL_ "GenSigTimeoutTime" BU_SG_REL_ Airbag SG_ 1792 Diag_Rq_Fktnl_Data_UDS 500;
BA_REL_ "GenSigTimeoutTime" BU_SG_REL_ Motor_MED17_Hybrid SG_ 1792 Diag_Rq_Fktnl_Data_UDS 500;
BA_REL_ "GenSigTimeoutTime" BU_SG_REL_ LEH_Hybrid SG_ 1792 Diag_Rq_Fktnl_Data_UDS 500;
BA_REL_ "GenSigTimeoutTime" BU_SG_REL_ BMS_Hybrid SG_ 1792 Diag_Rq_Fktnl_Data_UDS 500;
BA_REL_ "GenSigTimeoutTime" BU_SG_REL_ Getriebe_Derivate SG_ 1792 Diag_Rq_Fktnl_Data_UDS 500;
BA_REL_ "GenSigTimeoutTime" BU_SG_REL_ PSM_Ant_Derivate SG_ 1792 Diag_Rq_Fktnl_Data_UDS 500;
BA_REL_ "GenSigTimeoutTime" BU_SG_REL_ Motor_EDC17_Pirol SG_ 1424 KY_StartStopp_Info 2000;
BA_REL_ "GenSigTimeoutTime" BU_SG_REL_ Motor_MED17_Hybrid SG_ 1424 KY_StartStopp_Info 2000;
BA_REL_ "GenSigTimeoutTime" BU_SG_REL_ LEH_Hybrid SG_ 960 Klemmen_Status_01_CHK 1000;
BA_REL_ "GenSigTimeoutTime" BU_SG_REL_ BMS_Hybrid SG_ 960 Klemmen_Status_01_CHK 1000;
BA_REL_ "GenSigTimeoutTime" BU_SG_REL_ Motor_EDC17_Pirol SG_ 960 Klemmen_Status_01_CHK 1000;
BA_REL_ "GenSigTimeoutTime" BU_SG_REL_ Motor_MED17_Hybrid SG_ 960 Klemmen_Status_01_CHK 1000;
BA_REL_ "GenSigTimeoutTime" BU_SG_REL_ LEH_Hybrid SG_ 960 Klemmen_Status_01_BZ 1000;
BA_REL_ "GenSigTimeoutTime" BU_SG_REL_ BMS_Hybrid SG_ 960 Klemmen_Status_01_BZ 1000;
BA_REL_ "GenSigTimeoutTime" BU_SG_REL_ Motor_EDC17_Pirol SG_ 960 Klemmen_Status_01_BZ 1000;
BA_REL_ "GenSigTimeoutTime" BU_SG_REL_ Motor_MED17_Hybrid SG_ 960 Klemmen_Status_01_BZ 1000;
BA_REL_ "GenSigTimeoutTime" BU_SG_REL_ Ladegeraet_PAG_PF SG_ 960 ZAS_Kl_15 1000;
BA_REL_ "GenSigTimeoutTime" BU_SG_REL_ LEH_Hybrid SG_ 960 ZAS_Kl_15 1000;
BA_REL_ "GenSigTimeoutTime" BU_SG_REL_ BMS_Hybrid SG_ 960 ZAS_Kl_15 1000;
BA_REL_ "GenSigTimeoutTime" BU_SG_REL_ Motor_EDC17_Pirol SG_ 960 ZAS_Kl_15 1000;
BA_REL_ "GenSigTimeoutTime" BU_SG_REL_ Motor_MED17_Hybrid SG_ 960 ZAS_Kl_15 1000;
BA_REL_ "GenSigTimeoutTime" BU_SG_REL_ LEH_Hybrid SG_ 960 ZAS_Kl_50 1000;
BA_REL_ "GenSigTimeoutTime" BU_SG_REL_ Motor_EDC17_Pirol SG_ 960 ZAS_Kl_50 1000;
BA_REL_ "GenSigTimeoutTime" BU_SG_REL_ Waehlhebel SG_ 960 ZAS_Kl_50 1000;
BA_REL_ "GenSigTimeoutTime" BU_SG_REL_ Motor_MED17_Hybrid SG_ 960 ZAS_Kl_50 1000;
BA_REL_ "GenSigTimeoutTime" BU_SG_REL_ Ladegeraet_PAG_PF SG_ 960 ZAS_Kl_50 1000;
BA_REL_ "GenSigTimeoutTime" BU_SG_REL_ Motor_EDC17_Pirol SG_ 1137 BCM2_Bremsl_durch_ECD 1000;
BA_REL_ "GenSigTimeoutTime" BU_SG_REL_ Motor_MED17_Hybrid SG_ 1137 BCM2_Bremsl_durch_ECD 1000;
BA_REL_ "GenSigTimeoutTime" BU_SG_REL_ Motor_EDC17_Pirol SG_ 1137 LH_Bremsl_re_ges_def 1000;
BA_REL_ "GenSigTimeoutTime" BU_SG_REL_ Motor_MED17_Hybrid SG_ 1137 LH_Bremsl_re_ges_def 1000;
BA_REL_ "GenSigTimeoutTime" BU_SG_REL_ Motor_EDC17_Pirol SG_ 1137 LH_Bremsl_li_ges_def 1000;
BA_REL_ "GenSigTimeoutTime" BU_SG_REL_ Motor_MED17_Hybrid SG_ 1137 LH_Bremsl_li_ges_def 1000;
BA_REL_ "GenSigTimeoutTime" BU_SG_REL_ Motor_EDC17_Pirol SG_ 1137 Licht_hinten_01_BZ 1000;
BA_REL_ "GenSigTimeoutTime" BU_SG_REL_ Motor_MED17_Hybrid SG_ 1137 Licht_hinten_01_BZ 1000;
BA_REL_ "GenSigTimeoutTime" BU_SG_REL_ Motor_EDC17_Pirol SG_ 1137 LH_3_Bremsl_def 1000;
BA_REL_ "GenSigTimeoutTime" BU_SG_REL_ Motor_MED17_Hybrid SG_ 1137 LH_3_Bremsl_def 1000;
BA_REL_ "GenSigTimeoutTime" BU_SG_REL_ Getriebe_Derivate SG_ 1742 NMH_BMS_Start_1 2000;
BA_REL_ "GenSigTimeoutTime" BU_SG_REL_ LEH_Hybrid SG_ 1742 NMH_BMS_Start_1 2000;
BA_REL_ "GenSigTimeoutTime" BU_SG_REL_ Ladegeraet_PAG_PF SG_ 1742 NMH_BMS_Start_1 2000;
BA_REL_ "GenSigTimeoutTime" BU_SG_REL_ Motor_MED17_Hybrid SG_ 1742 NMH_BMS_Start_1 2000;
BA_REL_ "GenSigTimeoutTime" BU_SG_REL_ GW_Applikation_Derivate SG_ 1742 NMH_BMS_Start_1 2000;
BA_REL_ "GenSigTimeoutTime" BU_SG_REL_ GW_Applikation_Derivate SG_ 1742 NMH_BMS_Start_2 2000;
BA_REL_ "GenSigTimeoutTime" BU_SG_REL_ GW_Applikation_Derivate SG_ 1742 NMH_BMS_Normal_Mode_1 2000;
BA_REL_ "GenSigTimeoutTime" BU_SG_REL_ GW_Applikation_Derivate SG_ 1742 NMH_BMS_Normal_Mode_2 2000;
BA_REL_ "GenSigTimeoutTime" BU_SG_REL_ PSM_Ant_Derivate SG_ 1612 GW_Fzg_Antrieb 5000;
BA_REL_ "GenSigTimeoutTime" BU_SG_REL_ PSM_Ant_Derivate SG_ 1612 GW_Karosserie_Typ 5000;
BA_REL_ "GenSigTimeoutTime" BU_SG_REL_ BMS_Hybrid SG_ 1612 GW_Baureihe 5000;
BA_REL_ "GenSigTimeoutTime" BU_SG_REL_ PSM_Ant_Derivate SG_ 1612 GW_Baureihe 5000;
BA_REL_ "GenSigTimeoutTime" BU_SG_REL_ PSM_Ant_Derivate SG_ 1612 GW_Lenker 5000;
BA_REL_ "GenSigTimeoutTime" BU_SG_REL_ Airbag SG_ 1612 GW_Lenker 5000;
BA_REL_ "GenSigTimeoutTime" BU_SG_REL_ Ladegeraet_PAG_PF SG_ 1009 GW_STH_Anf 1000;
BA_REL_ "GenSigTimeoutTime" BU_SG_REL_ Airbag SG_ 1009 FSAktivBit 400;
BA_REL_ "GenSigTimeoutTime" BU_SG_REL_ Waehlhebel SG_ 1009 FSAktivBit 400;
BA_REL_ "GenSigTimeoutTime" BU_SG_REL_ Ladegeraet_PAG_PF SG_ 1625 EKL_Comp_current 5000;
BA_REL_ "GenSigTimeoutTime" BU_SG_REL_ Motor_MED17_Hybrid SG_ 1625 EKL_Comp_current 5000;
BA_REL_ "GenSigTimeoutTime" BU_SG_REL_ BMS_Hybrid SG_ 1625 EKL_Comp_current 5000;
BA_REL_ "GenSigTimeoutTime" BU_SG_REL_ BMS_Hybrid SG_ 1625 EKL_Comp_rev_stat 5000;
BA_REL_ "GenSigTimeoutTime" BU_SG_REL_ Waehlhebel SG_ 1793 Diag_Rq_Fktnl_Data_KWP2000 500;
BA_REL_ "GenSigTimeoutTime" BU_SG_REL_ Ladegeraet_PAG_PF SG_ 2015 Diag_Rq_Fktnl_Data_OBD 500;
BA_REL_ "GenSigTimeoutTime" BU_SG_REL_ Motor_EDC17_Pirol SG_ 2015 Diag_Rq_Fktnl_Data_OBD 500;
BA_REL_ "GenSigTimeoutTime" BU_SG_REL_ Getriebe_Derivate SG_ 2015 Diag_Rq_Fktnl_Data_OBD 500;
BA_REL_ "GenSigTimeoutTime" BU_SG_REL_ Motor_MED17_Hybrid SG_ 2015 Diag_Rq_Fktnl_Data_OBD 500;
BA_REL_ "GenSigTimeoutTime" BU_SG_REL_ LEH_Hybrid SG_ 2015 Diag_Rq_Fktnl_Data_OBD 500;
BA_REL_ "GenSigTimeoutTime" BU_SG_REL_ BMS_Hybrid SG_ 2015 Diag_Rq_Fktnl_Data_OBD 500;
BA_REL_ "GenSigTimeoutTime" BU_SG_REL_ Airbag SG_ 905 DK_PAO_Signalzaehler 1000;
BA_REL_ "GenSigTimeoutTime" BU_SG_REL_ Airbag SG_ 905 DK_St_PAO_Leuchte 1000;
BA_REL_ "GenSigTimeoutTime" BU_SG_REL_ PSM_Ant_Derivate SG_ 905 KL_Sportmodus 1000;
BA_REL_ "GenSigTimeoutTime" BU_SG_REL_ PSM_Ant_Derivate SG_ 905 KL_T_PSM_off 1000;
BA_REL_ "GenSigTimeoutTime" BU_SG_REL_ PSM_Ant_Derivate SG_ 905 F_Klima_08_1_PAG_Ant 1000;
BA_REL_ "GenSigTimeoutTime" BU_SG_REL_ Airbag SG_ 905 F_BCM2_03_PAG_Ant 1000;
BA_REL_ "GenSigTimeoutTime" BU_SG_REL_ GW_Routing_Derivate SG_ 1917 Diag_Rs_DLSNFS_PSM 500;
BA_REL_ "GenSigTimeoutTime" BU_SG_REL_ GW_Routing_Derivate SG_ 1917 Diag_Rs_PCItype_PSM 500;
BA_REL_ "GenSigTimeoutTime" BU_SG_REL_ GW_Routing_Derivate SG_ 1917 Diag_Rs_Data_PSM 500;
BA_REL_ "GenSigTimeoutTime" BU_SG_REL_ GW_Routing_Derivate SG_ 2025 ISO_Getriebe_01_Resp_Data 500;
BA_REL_ "GenSigTimeoutTime" BU_SG_REL_ GW_Routing_Derivate SG_ 2024 ISO_MO_01_Resp_Data 500;
BA_REL_ "GenSigTimeoutTime" BU_SG_REL_ PSM_Ant_Derivate SG_ 279 AWV1_Freigabe 500;
BA_REL_ "GenSigTimeoutTime" BU_SG_REL_ PSM_Ant_Derivate SG_ 279 AWV_Vorstufe 500;
BA_REL_ "GenSigTimeoutTime" BU_SG_REL_ PSM_Ant_Derivate SG_ 279 ANB_Zielbremsung_Freigabe 500;
BA_REL_ "GenSigTimeoutTime" BU_SG_REL_ PSM_Ant_Derivate SG_ 279 ANB_Zielbrems_Teilbrems_Verz_Anf 500;
BA_REL_ "GenSigTimeoutTime" BU_SG_REL_ PSM_Ant_Derivate SG_ 279 ANB_Teilbremsung_Freigabe 500;
BA_REL_ "GenSigTimeoutTime" BU_SG_REL_ PSM_Ant_Derivate SG_ 279 ANB_Notfallblinken 500;
BA_REL_ "GenSigTimeoutTime" BU_SG_REL_ PSM_Ant_Derivate SG_ 279 ANB_Info_Teilbremsung 500;
BA_REL_ "GenSigTimeoutTime" BU_SG_REL_ PSM_Ant_Derivate SG_ 279 ACC_10_CHK 500;
BA_REL_ "GenSigTimeoutTime" BU_SG_REL_ PSM_Ant_Derivate SG_ 279 ACC_10_BZ 500;
BA_REL_ "GenSigTimeoutTime" BU_SG_REL_ PSM_Ant_Derivate SG_ 279 AWV1_Anf_Prefill 500;
BA_REL_ "GenSigTimeoutTime" BU_SG_REL_ PSM_Ant_Derivate SG_ 279 AWV2_Freigabe 500;
BA_REL_ "GenSigTimeoutTime" BU_SG_REL_ PSM_Ant_Derivate SG_ 279 AWV2_Priowarnung 500;
BA_REL_ "GenSigTimeoutTime" BU_SG_REL_ PSM_Ant_Derivate SG_ 279 AWV1_HBA_Param 500;
BA_REL_ "GenSigTimeoutTime" BU_SG_REL_ PSM_Ant_Derivate SG_ 279 AWV2_Ruckprofil 500;
BA_REL_ "GenSigTimeoutTime" BU_SG_REL_ GW_Routing_Derivate SG_ 1919 Diag_Rs_DLSNFS_Airbag 500;
BA_REL_ "GenSigTimeoutTime" BU_SG_REL_ GW_Routing_Derivate SG_ 1919 Diag_Rs_PCItype_Airbag 500;
BA_REL_ "GenSigTimeoutTime" BU_SG_REL_ GW_Routing_Derivate SG_ 1919 Diag_Rs_Data_Airbag 500;
BA_REL_ "GenSigTimeoutTime" BU_SG_REL_ PSM_Ant_Derivate SG_ 1811 Diag_Rq_DLSNFS_PSM 500;
BA_REL_ "GenSigTimeoutTime" BU_SG_REL_ PSM_Ant_Derivate SG_ 1811 Diag_Rq_PCItype_PSM 500;
BA_REL_ "GenSigTimeoutTime" BU_SG_REL_ PSM_Ant_Derivate SG_ 1811 Diag_Rq_Data_PSM 500;
BA_REL_ "GenSigTimeoutTime" BU_SG_REL_ Airbag SG_ 1813 Diag_Rq_Data_Airbag 500;
BA_REL_ "GenSigTimeoutTime" BU_SG_REL_ Airbag SG_ 1813 Diag_Rq_DLSNFS_Airbag 500;
BA_REL_ "GenSigTimeoutTime" BU_SG_REL_ Airbag SG_ 1813 Diag_Rq_PCItype_Airbag 500;
BA_REL_ "GenSigTimeoutTime" BU_SG_REL_ Waehlhebel SG_ 1875 Diag_Rq_DLSNFS_Waehlhebel 500;
BA_REL_ "GenSigTimeoutTime" BU_SG_REL_ Waehlhebel SG_ 1875 Diag_Rq_PCItype_Waehlhebel 500;
BA_REL_ "GenSigTimeoutTime" BU_SG_REL_ Waehlhebel SG_ 1875 Diag_Rq_Data_Waehlhebel 500;
BA_REL_ "GenSigTimeoutTime" BU_SG_REL_ Getriebe_Derivate SG_ 2017 Diag_Rq_PCItype_PDK_OBD 500;
BA_REL_ "GenSigTimeoutTime" BU_SG_REL_ Getriebe_Derivate SG_ 2017 Diag_Rq_DLSNFS_PDK_OBD 500;
BA_REL_ "GenSigTimeoutTime" BU_SG_REL_ Getriebe_Derivate SG_ 2017 Diag_Rq_Data_PDK_OBD 500;
BA_REL_ "GenSigTimeoutTime" BU_SG_REL_ Motor_EDC17_Pirol SG_ 2016 Diag_Rq_PCItype_Motor_OBD 500;
BA_REL_ "GenSigTimeoutTime" BU_SG_REL_ Motor_MED17_Hybrid SG_ 2016 Diag_Rq_PCItype_Motor_OBD 500;
BA_REL_ "GenSigTimeoutTime" BU_SG_REL_ Motor_EDC17_Pirol SG_ 2016 Diag_Rq_DLSNFS_Motor_OBD 500;
BA_REL_ "GenSigTimeoutTime" BU_SG_REL_ Motor_MED17_Hybrid SG_ 2016 Diag_Rq_DLSNFS_Motor_OBD 500;
BA_REL_ "GenSigTimeoutTime" BU_SG_REL_ Motor_EDC17_Pirol SG_ 2016 Diag_Rq_Data_Motor_OBD 500;
BA_REL_ "GenSigTimeoutTime" BU_SG_REL_ Motor_MED17_Hybrid SG_ 2016 Diag_Rq_Data_Motor_OBD 500;
BA_REL_ "GenSigTimeoutTime" BU_SG_REL_ Motor_MED17_Hybrid SG_ 1630 OBD_TG_F_Status_1 5000;
BA_REL_ "GenSigTimeoutTime" BU_SG_REL_ Motor_MED17_Hybrid SG_ 1630 OBD_TG_F_Status_2 5000;
BA_REL_ "GenSigTimeoutTime" BU_SG_REL_ Motor_MED17_Hybrid SG_ 1630 OBD_TG_F_Status_3 5000;
BA_REL_ "GenSigTimeoutTime" BU_SG_REL_ Motor_MED17_Hybrid SG_ 1630 OBD_TG_F_Status_4 5000;
BA_REL_ "GenSigTimeoutTime" BU_SG_REL_ Motor_MED17_Hybrid SG_ 1630 OBD_TG_Sens_Rohwert_1 5000;
BA_REL_ "GenSigTimeoutTime" BU_SG_REL_ Motor_MED17_Hybrid SG_ 1630 OBD_TG_Sens_Rohwert_2 5000;
BA_REL_ "GenSigTimeoutTime" BU_SG_REL_ Motor_MED17_Hybrid SG_ 1630 OBD_TG_Sens_Rohwert_3 5000;
BA_REL_ "GenSigTimeoutTime" BU_SG_REL_ Motor_MED17_Hybrid SG_ 1630 OBD_TG_Sens_Rohwert_4 5000;
BA_REL_ "GenSigTimeoutTime" BU_SG_REL_ GW_Routing_Derivate SG_ 1607 MO_Kraftstofffilter_Wasser 5000;
BA_REL_ "GenSigTimeoutTime" BU_SG_REL_ GW_Routing_Derivate SG_ 1607 MO_ITM_Kuehlmittel_Temp 5000;
BA_REL_ "GenSigTimeoutTime" BU_SG_REL_ GW_Routing_Derivate SG_ 1607 MO_CO2_Faktor 5000;
BA_REL_ "GenSigTimeoutTime" BU_SG_REL_ GW_Routing_Derivate SG_ 1607 MO_E85_Sensor 5000;
BA_REL_ "GenSigTimeoutTime" BU_SG_REL_ GW_Routing_Derivate SG_ 1607 SCR_Anz_Motorstarts 5000;
BA_REL_ "GenSigTimeoutTime" BU_SG_REL_ GW_Routing_Derivate SG_ 1607 SCR_Reichweite 5000;
BA_REL_ "GenSigTimeoutTime" BU_SG_REL_ GW_Routing_Derivate SG_ 1607 SCR_Warnstufe_1 5000;
BA_REL_ "GenSigTimeoutTime" BU_SG_REL_ GW_Routing_Derivate SG_ 1607 SCR_Warnstufe_2 5000;
BA_REL_ "GenSigTimeoutTime" BU_SG_REL_ GW_Routing_Derivate SG_ 1607 SCR_Inducement_Strategie 5000;
BA_REL_ "GenSigTimeoutTime" BU_SG_REL_ GW_Routing_Derivate SG_ 1607 MO_MKB_MUX 5000;
BA_REL_ "GenSigTimeoutTime" BU_SG_REL_ GW_Routing_Derivate SG_ 1607 MO_MKB_01 5000;
BA_REL_ "GenSigTimeoutTime" BU_SG_REL_ GW_Routing_Derivate SG_ 1607 MO_MKB_02 5000;
BA_REL_ "GenSigTimeoutTime" BU_SG_REL_ GW_Routing_Derivate SG_ 1607 SCR_Text 5000;
BA_REL_ "GenSigTimeoutTime" BU_SG_REL_ GW_Routing_Derivate SG_ 1607 SCR_Akustik 5000;
BA_REL_ "GenSigTimeoutTime" BU_SG_REL_ GW_Routing_Derivate SG_ 1607 SCR_Systemfehler 5000;
BA_REL_ "GenSigTimeoutTime" BU_SG_REL_ GW_Routing_Derivate SG_ 1607 MO_MKB_04 5000;
BA_REL_ "GenSigTimeoutTime" BU_SG_REL_ GW_Routing_Derivate SG_ 1607 MO_MKB_03 5000;
BA_REL_ "GenSigTimeoutTime" BU_SG_REL_ Motor_MED17_Hybrid SG_ 269 ACC_StartStopp_Info 500;
BA_REL_ "GenSigTimeoutTime" BU_SG_REL_ Motor_EDC17_Pirol SG_ 269 ACC_StartStopp_Info 500;
BA_REL_ "GenSigTimeoutTime" BU_SG_REL_ PSM_Ant_Derivate SG_ 269 ACC_Anhalten 500;
BA_REL_ "GenSigTimeoutTime" BU_SG_REL_ Motor_EDC17_Pirol SG_ 269 ACC_Betaetigung_EPB 500;
BA_REL_ "GenSigTimeoutTime" BU_SG_REL_ Motor_MED17_Hybrid SG_ 269 ACC_Betaetigung_EPB 500;
BA_REL_ "GenSigTimeoutTime" BU_SG_REL_ Getriebe_Derivate SG_ 269 ACC_Status_ACC 500;
BA_REL_ "GenSigTimeoutTime" BU_SG_REL_ Motor_MED17_Hybrid SG_ 269 ACC_Status_ACC 500;
BA_REL_ "GenSigTimeoutTime" BU_SG_REL_ Motor_EDC17_Pirol SG_ 269 ACC_Status_ACC 500;
BA_REL_ "GenSigTimeoutTime" BU_SG_REL_ Getriebe_Derivate SG_ 269 ACC_ax_Getriebe 500;
BA_REL_ "GenSigTimeoutTime" BU_SG_REL_ PSM_Ant_Derivate SG_ 269 ACC_Loeseanforderung 500;
BA_REL_ "GenSigTimeoutTime" BU_SG_REL_ PSM_Ant_Derivate SG_ 269 ACC_Verz_anf 500;
BA_REL_ "GenSigTimeoutTime" BU_SG_REL_ Motor_MED17_Hybrid SG_ 269 ACC_Momentenanforderung 500;
BA_REL_ "GenSigTimeoutTime" BU_SG_REL_ Motor_EDC17_Pirol SG_ 269 ACC_Momentenanforderung 500;
BA_REL_ "GenSigTimeoutTime" BU_SG_REL_ Motor_EDC17_Pirol SG_ 269 ACC_limitierte_Anfahrdyn 500;
BA_REL_ "GenSigTimeoutTime" BU_SG_REL_ Motor_MED17_Hybrid SG_ 269 ACC_limitierte_Anfahrdyn 500;
BA_REL_ "GenSigTimeoutTime" BU_SG_REL_ Getriebe_Derivate SG_ 269 ACC_Freigabe_Verzanf 500;
BA_REL_ "GenSigTimeoutTime" BU_SG_REL_ Motor_EDC17_Pirol SG_ 269 ACC_Freigabe_Momentenanf 500;
BA_REL_ "GenSigTimeoutTime" BU_SG_REL_ Motor_MED17_Hybrid SG_ 269 ACC_Freigabe_Momentenanf 500;
BA_REL_ "GenSigTimeoutTime" BU_SG_REL_ Motor_EDC17_Pirol SG_ 269 ACC_05_CHK 500;
BA_REL_ "GenSigTimeoutTime" BU_SG_REL_ PSM_Ant_Derivate SG_ 269 ACC_05_CHK 500;
BA_REL_ "GenSigTimeoutTime" BU_SG_REL_ Getriebe_Derivate SG_ 269 ACC_05_CHK 500;
BA_REL_ "GenSigTimeoutTime" BU_SG_REL_ Motor_MED17_Hybrid SG_ 269 ACC_05_CHK 500;
BA_REL_ "GenSigTimeoutTime" BU_SG_REL_ Motor_EDC17_Pirol SG_ 269 ACC_05_BZ 500;
BA_REL_ "GenSigTimeoutTime" BU_SG_REL_ PSM_Ant_Derivate SG_ 269 ACC_05_BZ 500;
BA_REL_ "GenSigTimeoutTime" BU_SG_REL_ Getriebe_Derivate SG_ 269 ACC_05_BZ 500;
BA_REL_ "GenSigTimeoutTime" BU_SG_REL_ Motor_MED17_Hybrid SG_ 269 ACC_05_BZ 500;
BA_REL_ "GenSigTimeoutTime" BU_SG_REL_ Motor_EDC17_Pirol SG_ 1719 KBI_FStatus_Tank 5000;
BA_REL_ "GenSigTimeoutTime" BU_SG_REL_ Motor_MED17_Hybrid SG_ 1719 KBI_FStatus_Tank 5000;
BA_REL_ "GenSigTimeoutTime" BU_SG_REL_ Motor_EDC17_Pirol SG_ 1719 KBI_QBit_Aussen_Temp_gef 5000;
BA_REL_ "GenSigTimeoutTime" BU_SG_REL_ Motor_MED17_Hybrid SG_ 1719 KBI_QBit_Aussen_Temp_gef 5000;
BA_REL_ "GenSigTimeoutTime" BU_SG_REL_ BMS_Hybrid SG_ 1719 KBI_QBit_Aussen_Temp_gef 5000;
BA_REL_ "GenSigTimeoutTime" BU_SG_REL_ Motor_EDC17_Pirol SG_ 1719 KBI_Reset_Standzeit 5000;
BA_REL_ "GenSigTimeoutTime" BU_SG_REL_ Motor_MED17_Hybrid SG_ 1719 KBI_Reset_Standzeit 5000;
BA_REL_ "GenSigTimeoutTime" BU_SG_REL_ Motor_EDC17_Pirol SG_ 1719 KBI_Standzeit 5000;
BA_REL_ "GenSigTimeoutTime" BU_SG_REL_ Motor_MED17_Hybrid SG_ 1719 KBI_Standzeit 5000;
BA_REL_ "GenSigTimeoutTime" BU_SG_REL_ Getriebe_Derivate SG_ 1719 KBI_Kilometerstand 5000;
BA_REL_ "GenSigTimeoutTime" BU_SG_REL_ Motor_EDC17_Pirol SG_ 1719 KBI_Aussen_Temp_gef 5000;
BA_REL_ "GenSigTimeoutTime" BU_SG_REL_ Motor_MED17_Hybrid SG_ 1719 KBI_Aussen_Temp_gef 5000;
BA_REL_ "GenSigTimeoutTime" BU_SG_REL_ BMS_Hybrid SG_ 1719 KBI_Aussen_Temp_gef 5000;
BA_REL_ "GenSigTimeoutTime" BU_SG_REL_ Motor_EDC17_Pirol SG_ 1719 KBI_Inhalt_Tank 5000;
BA_REL_ "GenSigTimeoutTime" BU_SG_REL_ Motor_MED17_Hybrid SG_ 1719 KBI_Inhalt_Tank 5000;
BA_REL_ "GenSigTimeoutTime" BU_SG_REL_ Motor_EDC17_Pirol SG_ 779 KBI_Vorglueh_System_Lampe 500;
BA_REL_ "GenSigTimeoutTime" BU_SG_REL_ Motor_EDC17_Pirol SG_ 779 KBI_Fehler_Anzeige_ACC 500;
BA_REL_ "GenSigTimeoutTime" BU_SG_REL_ Motor_MED17_Hybrid SG_ 779 KBI_Fehler_Anzeige_ACC 500;
BA_REL_ "GenSigTimeoutTime" BU_SG_REL_ Motor_EDC17_Pirol SG_ 779 KBI_Einheit_Tacho 500;
BA_REL_ "GenSigTimeoutTime" BU_SG_REL_ Motor_MED17_Hybrid SG_ 779 KBI_Einheit_Tacho 500;
BA_REL_ "GenSigTimeoutTime" BU_SG_REL_ Motor_EDC17_Pirol SG_ 779 KBI_Tankwarnung 500;
BA_REL_ "GenSigTimeoutTime" BU_SG_REL_ Motor_MED17_Hybrid SG_ 779 KBI_Tankwarnung 500;
BA_REL_ "GenSigTimeoutTime" BU_SG_REL_ Motor_EDC17_Pirol SG_ 779 KBI_angez_Geschw 500;
BA_REL_ "GenSigTimeoutTime" BU_SG_REL_ Getriebe_Derivate SG_ 779 KBI_angez_Geschw 500;
BA_REL_ "GenSigTimeoutTime" BU_SG_REL_ Motor_MED17_Hybrid SG_ 779 KBI_angez_Geschw 500;
BA_REL_ "GenSigTimeoutTime" BU_SG_REL_ GW_Routing_Derivate SG_ 643 AB_Gurtwarn_HM 500;
BA_REL_ "GenSigTimeoutTime" BU_SG_REL_ GW_Routing_Derivate SG_ 643 AB_Gurtwarn_HB 500;
BA_REL_ "GenSigTimeoutTime" BU_SG_REL_ GW_Routing_Derivate SG_ 643 AB_Gurtwarn_HF 500;
BA_REL_ "GenSigTimeoutTime" BU_SG_REL_ GW_Routing_Derivate SG_ 643 AB_PAO_Info 500;
BA_REL_ "GenSigTimeoutTime" BU_SG_REL_ GW_Routing_Derivate SG_ 643 AB_AWS_Zustand 500;
BA_REL_ "GenSigTimeoutTime" BU_SG_REL_ GW_Routing_Derivate SG_ 643 AB_Crashdaten 500;
BA_REL_ "GenSigTimeoutTime" BU_SG_REL_ GW_Routing_Derivate SG_ 643 AB_SF_URS 500;
BA_REL_ "GenSigTimeoutTime" BU_SG_REL_ GW_Routing_Derivate SG_ 643 AB_SF_AWS 500;
BA_REL_ "GenSigTimeoutTime" BU_SG_REL_ GW_Routing_Derivate SG_ 643 AB_W_AWS_S 500;
BA_REL_ "GenSigTimeoutTime" BU_SG_REL_ GW_Applikation_Derivate SG_ 307 WHL_KD_Fehler 500;
BA_REL_ "GenSigTimeoutTime" BU_SG_REL_ Getriebe_Derivate SG_ 307 WHL_Magnet_Pos 500;
BA_REL_ "GenSigTimeoutTime" BU_SG_REL_ Getriebe_Derivate SG_ 307 WHL_BZ 500;
BA_REL_ "GenSigTimeoutTime" BU_SG_REL_ Getriebe_Derivate SG_ 307 WHL_TipUp 500;
BA_REL_ "GenSigTimeoutTime" BU_SG_REL_ Getriebe_Derivate SG_ 307 WHL_TipDown 500;
BA_REL_ "GenSigTimeoutTime" BU_SG_REL_ Getriebe_Derivate SG_ 307 WHL_Pos_komplement 500;
BA_REL_ "GenSigTimeoutTime" BU_SG_REL_ Ladegeraet_PAG_PF SG_ 307 WHL_Pos 500;
BA_REL_ "GenSigTimeoutTime" BU_SG_REL_ Getriebe_Derivate SG_ 307 WHL_Pos 500;
BA_REL_ "GenSigTimeoutTime" BU_SG_REL_ PSM_Ant_Derivate SG_ 1315 SVB_PDCC 2500;
BA_REL_ "GenSigTimeoutTime" BU_SG_REL_ PSM_Ant_Derivate SG_ 1315 SVB_EPB 2500;
BA_REL_ "GenSigTimeoutTime" BU_SG_REL_ PSM_Ant_Derivate SG_ 1315 SVB_QSP 2500;
BA_REL_ "GenSigTimeoutTime" BU_SG_REL_ PSM_Ant_Derivate SG_ 1315 SVB_ACC 2500;
BA_REL_ "GenSigTimeoutTime" BU_SG_REL_ PSM_Ant_Derivate SG_ 1315 SVB_PDK 2500;
BA_REL_ "GenSigTimeoutTime" BU_SG_REL_ PSM_Ant_Derivate SG_ 1315 SVB_AAG 2500;
BA_REL_ "GenSigTimeoutTime" BU_SG_REL_ PSM_Ant_Derivate SG_ 1315 SVB_PASM_NRA 2500;
BA_REL_ "GenSigTimeoutTime" BU_SG_REL_ Airbag SG_ 390 ESP_v_Signal 500;
BA_REL_ "GenSigTimeoutTime" BU_SG_REL_ GW_Routing_Derivate SG_ 1981 Diag_Rs_DLSNFS_Waehlhebel 500;
BA_REL_ "GenSigTimeoutTime" BU_SG_REL_ GW_Routing_Derivate SG_ 1981 Diag_Rs_PCItype_Waehlhebel 500;
BA_REL_ "GenSigTimeoutTime" BU_SG_REL_ GW_Routing_Derivate SG_ 1981 Diag_Rs_Data_Waehlhebel 500;
BA_REL_ "GenSigTimeoutTime" BU_SG_REL_ Airbag SG_ 910 F_Kombi_11_PAG_Ant 1000;
BA_REL_ "GenSigTimeoutTime" BU_SG_REL_ Airbag SG_ 910 F_Klima_08_PAG_Ant 1000;
BA_REL_ "GenSigTimeoutTime" BU_SG_REL_ Airbag SG_ 910 KL_Atemp_ungef 1000;
BA_REL_ "GenSigTimeoutTime" BU_SG_REL_ Airbag SG_ 910 F_Kombi_01_Ant 1000;
BA_REL_ "GenSigTimeoutTime" BU_SG_REL_ Airbag SG_ 910 KBI_Airbag_Lampe 1000;
BA_REL_ "GenSigTimeoutTime" BU_SG_REL_ Airbag SG_ 910 KBI_Fotosensor 1000;
BA_REL_ "GenSigTimeoutTime" BU_SG_REL_ Airbag SG_ 787 F_PCM_CDR_01_Ant 500;
BA_REL_ "GenSigTimeoutTime" BU_SG_REL_ Airbag SG_ 787 HU_Fotosensor 500;
BA_REL_ "HYB_Tx_Baureihe" BU_BO_REL_ GW_Routing_Derivate 17 2;
BA_REL_ "HYB_Tx_Baureihe" BU_BO_REL_ GW_Routing_Derivate 1705 2;
BA_REL_ "HYB_Tx_Baureihe" BU_BO_REL_ GW_Routing_Derivate 1704 2;
BA_REL_ "HYB_Tx_Baureihe" BU_BO_REL_ GW_Routing_Derivate 1792 2;
BA_REL_ "HYB_Tx_Baureihe" BU_BO_REL_ GW_Routing_Derivate 1424 2;
BA_REL_ "HYB_Tx_Baureihe" BU_BO_REL_ GW_Routing_Derivate 960 2;
BA_REL_ "HYB_Tx_Baureihe" BU_BO_REL_ GW_Routing_Derivate 1137 2;
BA_REL_ "HYB_Tx_Baureihe" BU_BO_REL_ GW_Routing_Derivate 1625 2;
BA_REL_ "HYB_Tx_Baureihe" BU_BO_REL_ GW_Routing_Derivate 1793 2;
BA_REL_ "HYB_Tx_Baureihe" BU_BO_REL_ GW_Routing_Derivate 2015 2;
BA_REL_ "HYB_Tx_Baureihe" BU_BO_REL_ GW_Routing_Derivate 905 2;
BA_REL_ "HYB_Tx_Baureihe" BU_BO_REL_ GW_Routing_Derivate 279 2;
BA_REL_ "HYB_Tx_Baureihe" BU_BO_REL_ GW_Routing_Derivate 1811 2;
BA_REL_ "HYB_Tx_Baureihe" BU_BO_REL_ GW_Routing_Derivate 1813 2;
BA_REL_ "HYB_Tx_Baureihe" BU_BO_REL_ GW_Routing_Derivate 1875 2;
BA_REL_ "HYB_Tx_Baureihe" BU_BO_REL_ GW_Routing_Derivate 2017 2;
BA_REL_ "HYB_Tx_Baureihe" BU_BO_REL_ GW_Routing_Derivate 2016 2;
BA_REL_ "HYB_Tx_Baureihe" BU_BO_REL_ GW_Routing_Derivate 1630 2;
BA_REL_ "HYB_Tx_Baureihe" BU_BO_REL_ GW_Routing_Derivate 269 2;
BA_REL_ "HYB_Tx_Baureihe" BU_BO_REL_ GW_Routing_Derivate 1719 2;
BA_REL_ "HYB_Tx_Verwendung" BU_BO_REL_ GW_Routing_Derivate 1719 1;
BA_REL_ "HYB_Tx_Baureihe" BU_BO_REL_ GW_Routing_Derivate 779 2;
BA_REL_ "HYB_Tx_Baureihe" BU_BO_REL_ GW_Routing_Derivate 390 2;
BA_REL_ "HYB_Tx_Baureihe" BU_BO_REL_ GW_Routing_Derivate 910 2;
BA_REL_ "HYB_Tx_Baureihe" BU_BO_REL_ GW_Routing_Derivate 787 2;
VAL_ 1704 KBI_Steigerung_Luftmenge_Fond 0 "Aus" 1 "Ein" ;
VAL_ 1704 KBI_PTC_Zuheizer 0 "PTC_Zuheizer_Aus" 1 "PTC_Zuheizer_An" ;
VAL_ 1704 KBI_FLA_GLW_Aktiv 0 "Einstellung_FLA_GLW_inaktiv" 1 "Einstellung_FLA_GLW_aktiv" ;
VAL_ 1704 KBI_ASD_innen 1 "An" 0 "Aus" ;
VAL_ 1704 KBI_ASD_aussen 1 "An" 0 "Aus" ;
VAL_ 1704 KBI_LDW_aktiv 0 "Inaktiv" 1 "Aktiv" ;
VAL_ 1704 KBI_Jokerkey_Hupe_Aktiv 0 "Einstellung_Jokerkey_Hupe_Inaktiv" 1 "Einstellung_Jokerkey_Hupe_Aktiv" ;
VAL_ 1704 KBI_Automem_inaktiv 1 "Automem nicht aktiv" 0 "Automem aktiv" ;
VAL_ 1704 KBI_Heckrollo_b_R 1 "Aktiv" 0 "Inaktiv" ;
VAL_ 1704 KBI_Klimastyles 3 "nicht definiert" 2 "strong" 1 "medium" 0 "soft" ;
VAL_ 1704 KBI_WV_Entr_Kof 15 "80 Sek." 14 "75 Sek." 13 "70 Sek." 12 "65 Sek." 11 "60 Sek." 10 "55 Sek." 9 "50 Sek." 8 "45 Sek." 7 "40 Sek." 6 "35 Sek." 5 "30 Sek." 4 "25 Sek." 3 "20 Sek." 2 "15 Sek." 1 "10 Sek." 0 "Türen werden nicht entriegelt" ;
VAL_ 1704 KBI_Carjack 3 "verr. bei KL15 oder v > 0 km/h" 2 "verr. bei v > 0 km/h" 1 "verr. bei KL15" 0 "inaktiv" ;
VAL_ 1704 KBI_Tuerentr_T 1 "nur Fahrertür" 0 "beide Türen" ;
VAL_ 1704 KBI_Einstiegshilfe_aktiv 1 "Aktiv" 0 "Inaktiv" ;
VAL_ 1704 KBI_FULL_AFS_Tourist 1 "Basiscodierung invertiert" 0 "Basiscodierung" ;
VAL_ 1704 KBI_Aussenspiegel_einklapp_auto 1 "ein" 0 "aus" ;
VAL_ 1704 KBI_Aussenspiegel_absenken_auto 1 "ein" 0 "aus" ;
VAL_ 1704 KBI_Heckw_b_R 3 "nicht definiert" 2 "nicht definiert" 1 "aktiv" 0 "inaktiv" ;
VAL_ 1704 KBI_TFL_akt 1 "Aktiv" 0 "Inaktiv" ;
VAL_ 1704 KBI_Erw_BelueftFeld 1 "Aktiv" 0 "Inaktiv" ;
VAL_ 1704 KBI_Auto_Umluft 1 "Aktiv" 0 "Inaktiv" ;
VAL_ 1704 KBI_Schaltpkt_Anz_ein 1 "ein" 0 "aus" ;
VAL_ 1704 KBI_RS_d_akt 1 "nicht Autoaktiv" 0 "Autoaktiv" ;
VAL_ 1424 KYL_Warn_Notzuendschloss 0 "Aus" 1 "Ein" ;
VAL_ 1424 KYL_Notzuendschloss 0 "nicht_verbaut" 1 "verbaut" ;
VAL_ 1424 KY_StartStopp_Info 3 "Systemfehler" 2 "Motoranlauf zwingend notwendig (Startanforderung)" 1 "Motoranlauf nicht zwingend notwendig (Stoppverbot, keine Startanforderung, evtl. Komforteinbussen)" 0 "Motorlauf langfristig nicht notwendig (Stoppfreigabe)" ;
VAL_ 1424 KY_Funkschl_Nr 12 "ungueltig_12" 3 "aktive_Funkschluessel_Nr_03" 8 "aktive_Funkschluessel_Nr_08" 4 "aktive_Funkschluessel_Nr_04" 0 "kein authorisierter Schluessel erkannt" 15 "ungueltig_15" 1 "aktive_Funkschluessel_Nr_01" 9 "ungueltig_09" 2 "aktive_Funkschluessel_Nr_02" 11 "ungueltig_11" 5 "aktive_Funkschluessel_Nr_05" 14 "ungueltig_14" 7 "aktive_Funkschluessel_Nr_07" 13 "ungueltig_13" 6 "aktive_Funkschluessel_Nr_06" 10 "ungueltig_10" ;
VAL_ 1424 KY_ID_Geb_autorisiert 1 "authorisiert" 0 "nicht authorisiert" ;
VAL_ 1424 KY_ID_Geb_steckt 1 "Schlüssel steckt im Zündschloss" 0 "kein Schlüssel im Zündschloss" ;
VAL_ 1424 KY_FFB_Frequenz 3 "868 MHz" 2 "315 MHz" 1 "433 MHz" ;
VAL_ 1424 KY_HF_Aktiv 1 "Aktiv" 0 "Inaktiv" ;
VAL_ 1424 KY_LF_Aktiv 1 "Aktiv" 0 "Inaktiv" ;
VAL_ 1424 KY_ELV_verr 1 "verriegelt" 0 "nicht verriegelt" ;
VAL_ 1424 KY_ELV_entr 1 "entriegelt" 0 "nicht entriegelt" ;
VAL_ 1424 KY_ELV_enable_Anforderung 1 "Freigabe wird angefordert" 0 "Freigabe nicht angefordert" ;
VAL_ 1424 KY_Valet_Parking 1 "Valet Schlüssel erkannt" 0 "kein Valet Schlüssel erkannt" ;
VAL_ 1424 KY_Keyless_Verbau 1 "Keyless verbaut" 0 "kein Keyless verbaut" ;
VAL_ 1424 FBS_Warn_Lenkung_def 1 "defekt" 0 "OK" ;
VAL_ 1424 FBS_Warn_LenkVerriegelung_def 1 "defekt" 0 "OK" ;
VAL_ 1424 FBS_Warn_Schluessel_Batt 1 "defekt" 0 "OK" ;
VAL_ 1424 KYL_Warn_kein_Schluessel 0 "kein Schlüssel erkannt" ;
VAL_ 1424 KYL_Warn_Kessy_defekt 1 "defekt" 0 "OK" ;
VAL_ 1424 KY_WFS_Safe 1 "WFS nicht deaktiviert" ;
VAL_ 1424 KY_WFS_LZ 3 "LZ 3" 2 "LZ 2" 1 "LZ 1" 0 "nicht def." ;
VAL_ 1424 FBS_KD_Fehler 1 "mind. ein KD-Fehler vorhanden" 0 "kein KD-Fehler" ;
VAL_ 1424 SK_Anf_DTC_Abfrage_sofort 1 "DTC_Abfrage_sofort" ;
VAL_ 1424 SK_Anf_DTC_Abfrage 1 "DTC_Abfrage" ;
VAL_ 960 ZV_verriegelt_extern_soll_02 1 "Fahrzeug verriegelt extern; Sollzusstand" ;
VAL_ 960 ZAS_Kl_S 1 "ein" 0 "aus" ;
VAL_ 960 ZAS_Kl_15 1 "ein" 0 "aus" ;
VAL_ 960 ZAS_Kl_X 1 "ein" 0 "aus" ;
VAL_ 960 ZAS_Kl_50 1 "ein" 0 "aus" ;
VAL_ 1137 LH_Aussenlicht_def 0 "OK" 1 "defekt" ;
VAL_ 1137 LH_Standlicht_H_aktiv 1 "Standlicht hinten aktiv" ;
VAL_ 1137 LH_SL_BRL_BLK_re_def 0 "OK" 1 "defekt" ;
VAL_ 1137 LH_SL_BRL_BLK_li_def 0 "OK" 1 "defekt" ;
VAL_ 1137 LH_Schluss_Nebel_re_def 0 "OK" 1 "defekt" ;
VAL_ 1137 LH_Schluss_Nebel_li_def 0 "OK" 1 "defekt" ;
VAL_ 1137 LH_Schluss_Brems_re_def 0 "OK" 1 "defekt" ;
VAL_ 1137 LH_Schluss_Brems_Nebel_re_def 0 "iO" 1 "defekt" ;
VAL_ 1137 LH_Schluss_Brems_Nebel_li_def 0 "iO" 1 "defekt" ;
VAL_ 1137 LH_Schluss_Brems_li_def 0 "OK" 1 "defekt" ;
VAL_ 1137 LH_Rueckfahrlicht_aktiv 0 "nicht aktiv" 1 "aktiv" ;
VAL_ 1137 LH_Rueckf_mi_def 0 "OK" 1 "Rückfahllicht Mitte defekt" ;
VAL_ 1137 LH_Parklicht_HR_aktiv 0 "nicht aktiv" 1 "Parklicht hinten rechts aktiv" ;
VAL_ 1137 LH_Parklicht_HL_aktiv 0 "nicht aktiv" 1 "Parklicht hinten links aktiv" ;
VAL_ 1137 LH_Nebelschluss_aktiv 0 "nicht aktiv" 1 "aktiv" ;
VAL_ 1137 LH_Nebel_mi_def 0 "OK" 1 " Nebelschlusslicht hinten Mitte defekt" ;
VAL_ 1137 LH_Bremslicht_H_aktiv 1 "Bremslicht hinten aktiv" ;
VAL_ 1137 LH_Brems_Blk_re_def 0 "OK" 1 "defekt" ;
VAL_ 1137 LH_Brems_Blk_li_def 0 "OK" 1 "defekt" ;
VAL_ 1137 LH_Blinker_re_def 0 "OK" 1 "Blinker hinten rechts defekt" ;
VAL_ 1137 LH_Blinker_li_def 0 "OK" 1 "Blinker hinten links defekt" ;
VAL_ 1137 LH_Blinker_HR_akt 1 "Blinker hinten rechts aktiv" ;
VAL_ 1137 LH_Blinker_HL_akt 1 "Blinker hinten links aktiv" ;
VAL_ 1137 BCM2_Bremsl_durch_ECD 1 "Bremslicht_durch_ECD_aktiv" 0 "Bremslicht_ist_aus" ;
VAL_ 1137 LH_Bremsl_re_ges_def 0 "OK" 1 "Alle Bremslichter hinten rechts defekt" ;
VAL_ 1137 LH_Bremsl_li_ges_def 0 "OK" 1 "Alle Bremslichter hinten links defekt" ;
VAL_ 1742 NMH_BMS_NL_Daten_EEPROM 0 "kein_Nachlauf" 1 "EEPROM_schreibzugriff" ;
VAL_ 1742 NMH_BMS_NL_Luefter 1 "Luefter_aktiv" 0 "kein_Nachlauf" ;
VAL_ 1742 NMH_BMS_Signalfehler 1 "Aktiver_Signalfehler_eingetragen" ;
VAL_ 1742 NMH_BMS_TimeOut_Fehler 1 "Aktiver Timeout Fehlerspeichereintrag" ;
VAL_ 1742 NMH_BMS_CAN_Diag_deaktiv 1 "CAN Bus bezogene Eigendiagnose deaktiviert" ;
VAL_ 1742 NMH_BMS_KompSchutz 1 "KS aktiv" ;
VAL_ 1742 NMH_BMS_Mute_Mode 1 "Mute Mode aktiv" ;
VAL_ 1742 NMH_BMS_Transport_Mode 1 "Transportmodus aktiv" ;
VAL_ 1742 NMH_BMS_Abschaltstufe_aktiv 1 "Funktionsabschaltung wegen Abschaltschaltstufe" ;
VAL_ 1742 NMH_BMS_Busfehler 1 "Busfehler" ;
VAL_ 1742 NMH_BMS_Lokalaktiv 0 "war_nicht_lokal_aktiv" 1 "war_lokal_aktiv" ;
VAL_ 1742 NMH_BMS_Subsystemaktiv 1 "war Lokalaktiv" 0 "Subsystem war nicht lokalaktiv" ;
VAL_ 1742 NMH_BMS_Start_1 1 "Zustand Start (<--Sleep)" ;
VAL_ 1742 NMH_BMS_Start_2 1 "Zustand Start (<--Prepare to Sleep)" ;
VAL_ 1742 NMH_BMS_Normal_Mode_1 1 "Zustand Normal Mode (<-- Start)" ;
VAL_ 1742 NMH_BMS_Normal_Mode_2 1 "Zustand Normal Mode (<-- Ready to Sleep)" ;
VAL_ 1742 NMH_BMS_Car_WakeUp 1 "Car Wake Up" ;
VAL_ 1742 NMH_BMS_Per_WakeUp 2 "P_WakeUp_Ursache_unbekannt" 3 "KL_15_Hardware_falls_vorhanden" 0 "Funktions-WakeUp" 1 "CAN" ;
VAL_ 1742 NMH_BMS_Fkt_WakeUp 0 "Peripheriewakeup" ;
VAL_ 1742 NMH_BMS_Klemme_15 1 "Klemme 15 ein" ;
VAL_ 1742 NMH_BMS_Diagnose 1 "Diagnose bei Kl 15 aus" ;
VAL_ 1742 NMH_BMS_MindestAktivZeit 1 "aktiv" ;
VAL_ 1612 GW_Fzg_Antrieb 15 "Reserve" 14 "Reserve" 13 "Reserve" 12 "Reserve" 11 "Reserve" 10 "Reserve" 9 "Reserve" 8 "Reserve" 7 "Reserve" 6 "Reserve" 5 "Reserve" 4 "Reserve" 3 "Reserve" 2 "Reserve" 1 "Vierradantrieb" 0 "Zweiradantrieb" ;
VAL_ 1612 GW_Karosserie_Typ 15 "Reserve" 14 "Reserve" 13 "Reserve" 12 "Reserve" 11 "Reserve" 10 "Reserve" 9 "Reserve" 8 "Reserve" 7 "Reserve" 6 "Reserve" 5 "Reserve" 4 "Reserve" 3 "Reserve" 2 "Targa" 1 "Cabrio" 0 "Coupe" ;
VAL_ 1612 GW_Baureihe 15 "Reserve" 14 "Reserve" 13 "Reserve" 12 "Reserve" 11 "Reserve" 10 "Reserve" 9 "Reserve" 8 "Reserve" 7 "Reserve" 6 "Reserve" 5 "Reserve" 4 "Reserve" 3 "Boxster" 2 "Carrera" 1 "Cayenne" 0 "Panamera" ;
VAL_ 1612 GW_Lenker 1 "Rechtslenker" 0 "Linkslenker" ;
VAL_ 1009 GW_STH_Anf 3 "STH Timer aktiv" 2 "Standheizung AUS" 1 "Standheizung EIN" 0 "keine EIN/AUS-Anf/kein Timer akt" ;
VAL_ 1009 FSAktivBit 1 "Fehler speichern" 0 "keine Fehler speichern" ;
VAL_ 1625 EKL_KD_Fehler 1 "KD_Fehler" 0 "kein_KD_Fehler" ;
VAL_ 1625 EKL_Comp_SCI_com_stat 0 "normal" 1 "CAN_error" 2 "Inverter_error" 3 "CAN_and_Inverter_error" ;
VAL_ 1625 EKL_Comp_output_stat 2 "output_line_cut_out" 3 "abnormal_current_detection" 1 "output_line_short" 0 "normal" ;
VAL_ 1625 EKL_Comp_main_stat 1 "Comp_enabled" 0 "Comp_not_enabled" ;
VAL_ 1625 EKL_Comp_ovld_stat 6 "over_input_current" 4 "over_load" 3 "software_over_current" 2 "current_restriction" 0 "normal" 1 "voltage_restriction" ;
VAL_ 1625 EKL_Comp_Inv_stat 2 "temperature_protection" 0 "normal" 1 "start_fail" 3 "system_abnormal_stop" ;
VAL_ 1625 EKL_Comp_photo_temp_stat 3 "sermister_abnormal" 2 "over_heat_S" 0 "normal" 1 "over_heat_L" ;
VAL_ 1625 EKL_Comp_photo_temp 255 "Fehler" ;
VAL_ 1625 EKL_Comp_current 255 "Fehler" ;
VAL_ 1625 EKL_Comp_rev_stat 255 "Fehler" ;
VAL_ 905 EPB_Anfahrwunsch_erkannt 1 "Anfahrwunsch erkannt" 0 "kein Anfahrwunsch erkannt" ;
VAL_ 905 EPB_QBit_Schalterpos 1 "Ersatz-, Init- oder Fehlerwert (Schalter ausser Funktion)" 0 "gültiger Wert (volle Funktion)" ;
VAL_ 905 EPB_Schalterposition 2 "Fahreranforderung_Schliessen" 0 "keine_Fahreranforderung" 1 "Fahreranforderung_Oeffnen" 3 "Schalterfehler" ;
VAL_ 905 EPB_Freig_Verzoeg_Anf 0 "Verzögerungsanforderung nicht freigegeben" 1 "Verzögerungsanforderung freigegeben" ;
VAL_ 905 KL_Segeln_Anf_deaktivieren 0 "Segeln nicht deaktiveren " 1 "Segeln deaktvieren" ;
VAL_ 905 KL_T_Abgasklappe 1 "Taster betätigt" 0 "Taster nicht betätigt" ;
VAL_ 905 KL_St_Atemp 3 "Unterbrechung" 4 "Sensorsignal unplausibel" 2 "Kurzschluss gegen Spg > 5V" 1 "Kurzschluss nach Masse" 0 "Kein Fehler" ;
VAL_ 905 KL_Komp_ein 1 "Aktiv" 0 "Inaktiv" ;
VAL_ 905 KL_KaeltemittelDruck 255 "Fehler" ;
VAL_ 905 DK_St_PAO_Leuchte 3 "ungültig" 2 "defekt" 1 "ein" 0 "aus" ;
VAL_ 905 KL_Sportmodus 0 "Normal" 7 "Reserve" 1 "Sport 1" 3 "Reserve" 4 "Reserve" 2 "Sport 2" 6 "Reserve" 5 "Reserve" ;
VAL_ 905 F_EPB_01_Ant 1 "veraltet" 0 "aktuell" ;
VAL_ 905 EPB_Status 3 "unbekannt" 2 "Aktuator im Lauf" 0 "Bremse_geoeffnet" 1 "Bremse_geschlossen" ;
VAL_ 905 F_Klima_03_Ant 1 "veraltet" 0 "aktuell" ;
VAL_ 905 KL_Magnetventil 1 "Wasserventil geschlossen" 0 "Wasserventil geoeffnet" ;
VAL_ 905 KL_T_PSM_off 0 "Taste nicht betaetigt" 1 "Taste betaetigt" ;
VAL_ 905 F_Klima_01_1_Ant 1 "veraltet" 0 "aktuell" ;
VAL_ 905 F_Klima_08_1_PAG_Ant 1 "veraltet" 0 "aktuell" ;
VAL_ 905 F_BCM2_03_PAG_Ant 1 "veraltet" 0 "aktuell" ;
VAL_ 905 KL_Last_Kompr 255 "Fehler" ;
VAL_ 905 KL_STH_Ansteuerung 3 "Heizleistung reduziert" 2 "Ein mit Motorvorwaermung" 1 "Ein" 0 "Aus" ;
VAL_ 905 KL_STH_aktiv 1 "Aktiv" 0 "Inaktiv" ;
VAL_ 905 EPB_Fehlerstatus 2 "EPB temporär nicht verfügbar - Spannen nicht möglich da Fzg. in Fahrt" 1 "EPB temporär nicht verfügbar - AVH darf nicht aktiv werden, sondern muss bei AVH-Anforderung warnen" 3 "Fehler in EPB - AVH darf von ESP nicht ausgeführt werden" 0 "kein Fehler in EPB - AVH darf von ESP ausgeführt werden" ;
VAL_ 1917 Diag_Rs_PCItype_PSM 3 "FlowControl (FC)" 2 "ConsecutiveFrame (CF)" 1 "FirstFrame (FF)" 0 "SingleFrame (SF)" ;
VAL_ 279 AWV_Vorstufe 0 "keine_Notbremsung_erwartet" 1 "Notbremsung_in_Kuerze" ;
VAL_ 279 ANB_Zielbremsung_Freigabe 0 "Zielbremsung_nicht_freigegeben" 1 "Zielbremsung_freigegeben" ;
VAL_ 279 ANB_Teilbremsung_Freigabe 0 "Teilbremsung_nicht_freigegeben" 1 "Teilbremsung_freigegeben" ;
VAL_ 279 ANB_Notfallblinken 0 "kein_ANB_Notfallblinken" 1 "Notfallblinken_ANB_angefordert" ;
VAL_ 279 ANB_Info_Teilbremsung 0 "Auspraegung_Standard" 1 "Auspraegung_Erweitert" ;
VAL_ 279 ANB_CM_Anforderung 0 "keine_Anforderung" 1 "Anforderung_aktiv" ;
VAL_ 1919 Diag_Rs_PCItype_Airbag 3 "FlowControl (FC)" 2 "ConsecutiveFrame (CF)" 1 "FirstFrame (FF)" 0 "SingleFrame (SF)" ;
VAL_ 1811 Diag_Rq_PCItype_PSM 3 "FlowControl (FC)" 2 "ConsecutiveFrame (CF)" 1 "FirstFrame (FF)" 0 "SingleFrame (SF)" ;
VAL_ 1813 Diag_Rq_PCItype_Airbag 3 "FlowControl (FC)" 2 "ConsecutiveFrame (CF)" 1 "FirstFrame (FF)" 0 "SingleFrame (SF)" ;
VAL_ 1875 Diag_Rq_PCItype_Waehlhebel 3 "FlowControl (FC)" 2 "ConsecutiveFrame (CF)" 1 "FirstFrame (FF)" 0 "SingleFrame (SF)" ;
VAL_ 2017 Diag_Rq_PCItype_PDK_OBD 3 "FlowControl (FC)" 2 "ConsecutiveFrame (CF)" 1 "FirstFrame (FF)" 0 "SingleFrame (SF)" ;
VAL_ 2016 Diag_Rq_PCItype_Motor_OBD 3 "FlowControl (FC)" 2 "ConsecutiveFrame (CF)" 1 "FirstFrame (FF)" 0 "SingleFrame (SF)" ;
VAL_ 1630 OBD_TG_F_Status_1 0 "kein Fehler / Init / nicht verbaut" 1 "KS-" 2 "KS+ (B8: nicht bedient)" 3 "OC (Leitungsunterbrechung) (B8: nicht bedient)" 4 "OOR+ (out of range high) (B8: nicht bedient)" 5 "OOR- (out of range low) (B8: nicht bedient)" 6 "RC+ (Signal unplausibel hoch) (B8: nicht bedient)" 7 "RC- (Signal unplausibel niedrig) (B8: nicht bedient)" 8 "KS+/OC" 9 "KS-/OC (B8: nicht bedient)" 10 "KS-/KS+ (B8: nicht bedient)" 11 "KS-/KS+/OC (allgemeiner Fehler)" 12 "frei" 13 "frei" 14 "frei" 15 "frei" ;
VAL_ 1630 OBD_TG_F_Status_2 0 "kein Fehler / Init / nicht verbaut" 1 "KS-" 2 "KS+ (B8: nicht bedient)" 3 "OC (Leitungsunterbrechung) (B8: nicht bedient)" 4 "OOR+ (out of range high) (B8: nicht bedient)" 5 "OOR- (out of range low) (B8: nicht bedient)" 6 "RC+ (Signal unplausibel hoch) (B8: nicht bedient)" 7 "RC- (Signal unplausibel niedrig) (B8: nicht bedient)" 8 "KS+/OC" 9 "KS-/OC (B8: nicht bedient)" 10 "KS-/KS+ (B8: nicht bedient)" 11 "KS-/KS+/OC (allgemeiner Fehler)" 12 "frei" 13 "frei" 14 "frei" 15 "frei" ;
VAL_ 1630 OBD_TG_F_Status_3 0 "kein Fehler / Init / nicht verbaut" 1 "KS-" 2 "KS+ (B8: nicht bedient)" 3 "OC (Leitungsunterbrechung) (B8: nicht bedient)" 4 "OOR+ (out of range high) (B8: nicht bedient)" 5 "OOR- (out of range low) (B8: nicht bedient)" 6 "RC+ (Signal unplausibel hoch) (B8: nicht bedient)" 7 "RC- (Signal unplausibel niedrig) (B8: nicht bedient)" 8 "KS+/OC" 9 "KS-/OC (B8: nicht bedient)" 10 "KS-/KS+ (B8: nicht bedient)" 11 "KS-/KS+/OC (allgemeiner Fehler)" 12 "frei" 13 "frei" 14 "frei" 15 "frei" ;
VAL_ 1630 OBD_TG_F_Status_4 0 "kein Fehler / Init / nicht verbaut" 1 "KS-" 2 "KS+ (B8: nicht bedient)" 3 "OC (Leitungsunterbrechung) (B8: nicht bedient)" 4 "OOR+ (out of range high) (B8: nicht bedient)" 5 "OOR- (out of range low) (B8: nicht bedient)" 6 "RC+ (Signal unplausibel hoch) (B8: nicht bedient)" 7 "RC- (Signal unplausibel niedrig) (B8: nicht bedient)" 8 "KS+/OC" 9 "KS-/OC (B8: nicht bedient)" 10 "KS-/KS+ (B8: nicht bedient)" 11 "KS-/KS+/OC (allgemeiner Fehler)" 12 "frei" 13 "frei" 14 "frei" 15 "frei" ;
VAL_ 1607 MO_Kraftstofffilter_Wasser 0 "keine_Anzeige" 1 "Abscheidevolumen_erschoepft" ;
VAL_ 1607 MO_ITM_Kuehlmittel_Temp 0 "nicht_verbaut" 2 "Fehler" ;
VAL_ 1607 MO_CO2_Faktor 0 "nicht_verbaut" 4095 "Fehler" ;
VAL_ 1607 MO_E85_Sensor 13 "nicht_verbaut" 15 "Fehler" ;
VAL_ 1607 SCR_Anz_Motorstarts 15 "keine Einschränkung (Anzeige Reichweite)" ;
VAL_ 1607 SCR_Reichweite 32767 "Init" ;
VAL_ 1607 SCR_Warnstufe_1 0 "nicht aktiv" 1 "Warnstufe 1 aktiv" ;
VAL_ 1607 SCR_Warnstufe_2 0 "nicht aktiv" 1 "Warnstufe 2 aktiv" ;
VAL_ 1607 SCR_Inducement_Strategie 0 "Restart_Strategie" 1 "Reduced_Drivability_Strategie" ;
VAL_ 1607 MO_MKB_MUX 0 "MKB_01" 2 "MKB_03" 3 "MKB_04" 1 "MKB_02" ;
VAL_ 1607 MO_MKB_01 7 "G" 1 "A" 28 "Leerzeichen" 14 "N" 31 "Unterstrich" 9 "I" 3 "C" 6 "F" 23 "W" 26 "Z" 10 "J" 8 "H" 24 "X" 27 "Leerzeichen" 30 "Leerzeichen" 16 "P" 18 "R" 17 "Q" 25 "Y" 12 "L" 19 "S" 11 "K" 5 "E" 4 "D" 0 "Minus" 20 "T" 15 "O" 29 "Leerzeichen" 13 "M" 2 "B" 21 "U" 22 "V" ;
VAL_ 1607 MO_MKB_02 7 "G" 1 "A" 28 "Leerzeichen" 14 "N" 31 "Unterstrich" 9 "I" 3 "C" 6 "F" 23 "W" 26 "Z" 10 "J" 8 "H" 24 "X" 27 "Leerzeichen" 30 "Leerzeichen" 16 "P" 18 "R" 17 "Q" 25 "Y" 12 "L" 19 "S" 11 "K" 5 "E" 4 "D" 0 "Minus" 20 "T" 15 "O" 29 "Leerzeichen" 13 "M" 2 "B" 21 "U" 22 "V" ;
VAL_ 1607 SCR_Text 1 "Warntext 1" 2 "Warntext 2" 3 "Hinweistext (nur AUDI)" 0 "kein Text" 5 "Warntext 'SCR-Systemfehler Stufe 1'" 4 "Reserve" 6 "Warntext 'SCR-Systemfehler Stufe 2'" ;
VAL_ 1607 SCR_Akustik 0 "keine Akustik" 1 "Akustik 1" 3 "frei" 2 "Akustik 2" ;
VAL_ 1607 SCR_Systemfehler 1 "Warnung_aktiv" 0 "Warnung_nicht_aktiv" ;
VAL_ 1607 MO_MKB_04 7 "G" 1 "A" 28 "Leerzeichen" 14 "N" 31 "Unterstrich" 9 "I" 3 "C" 6 "F" 23 "W" 26 "Z" 10 "J" 8 "H" 24 "X" 27 "Leerzeichen" 30 "Leerzeichen" 16 "P" 18 "R" 17 "Q" 25 "Y" 12 "L" 19 "S" 11 "K" 5 "E" 4 "D" 0 "Minus" 20 "T" 15 "O" 29 "Leerzeichen" 13 "M" 2 "B" 21 "U" 22 "V" ;
VAL_ 1607 MO_MKB_03 7 "G" 1 "A" 28 "Leerzeichen" 14 "N" 31 "Unterstrich" 9 "I" 3 "C" 6 "F" 23 "W" 26 "Z" 10 "J" 8 "H" 24 "X" 27 "Leerzeichen" 30 "Leerzeichen" 16 "P" 18 "R" 17 "Q" 25 "Y" 12 "L" 19 "S" 11 "K" 5 "E" 4 "D" 0 "Minus" 20 "T" 15 "O" 29 "Leerzeichen" 13 "M" 2 "B" 21 "U" 22 "V" ;
VAL_ 269 ACC_Vorbefuellung_Bremsanlage 0 "Vorbefuellung_AUS" 1 "Vorbefuellung_EIN" ;
VAL_ 269 ACC_KD_Fehler 1 "mind. ein KD-Fehler vorhanden" 0 "kein KD-Fehler" ;
VAL_ 269 ACC_Anhalten 1 "Anhalten gewünscht" 0 "kein Anhalten gewünscht" ;
VAL_ 269 ACC_Beeinflussung_ESP 1 "ESP Zwangszuschaltung" 0 "keine ESP Zwangszuschaltung" ;
VAL_ 269 ACC_Betaetigung_EPB 1 "EPB Aktuator schliessen" 0 "keine EPB Anforderung" ;
VAL_ 269 ACC_Status_ACC 7 "irreversibler_Fehler_im_ACC_System" 6 "reversibler_Fehler_im_ACC_System" 5 "nicht_definiert" 4 "ACC_OVERRIDE" 3 "ACC_AKTIV_regelt" 2 "ACC_STANDBY" 1 "ACC_INIT" 0 "ACC_OFF_Hauptschalter_aus" ;
VAL_ 269 ACC_Loeseanforderung 1 "Löseanforderung" 0 "keine Löseanforderung" ;
VAL_ 269 ACC_limitierte_Anfahrdyn 1 "Limitierung Anfahrdynamik angefordert" 0 "keine Limitierung" ;
VAL_ 269 ACC_Getriebestellung_P 1 "Anforderung P Stellung" 0 "P Stellung nicht angefordert" ;
VAL_ 269 ACC_Freigabe_Verzanf 1 "Verzögerungsanforderung freigegeben" 0 "Verzögerungsanforderung nicht freigegeben" ;
VAL_ 269 ACC_Freigabe_Momentenanf 1 "Momentenanforderung freigegeben" 0 "Momentenanforderung nicht freigegeben" ;
VAL_ 1719 KBI_QBit_Aussen_Temp_gef 1 "Ersatz-, Init- oder Fehlerwert" 0 "gültiger Wert" ;
VAL_ 1719 KBI_Reset_Standzeit 0 "Standzeit iO" 1 "KL30 war weg" ;
VAL_ 1719 KBI_Kilometerstand 1048575 "Fehlerwert" 1048574 "Initwert" ;
VAL_ 1719 KBI_Aussen_Temp_gef 255 "Fehler" 254 "Init" 253 "nicht verbaut" ;
VAL_ 1719 KBI_Inhalt_Tank 127 "Fehler" ;
VAL_ 779 KBI_Anzeigefehler_LDW 0 "nicht vorhanden bzw. unterstützt" 1 "Anzeige iO" 2 "Anzeigefehler" 3 "nicht definiert" ;
VAL_ 779 KBI_MFA_v_Einheit_01 0 "kmh" 1 "mph" ;
VAL_ 779 KBI_Vorglueh_System_Lampe 0 "Vorglueh_Sys_Lampe_aus" 1 "Lampe_ein" ;
VAL_ 779 KBI_Variante_USA 1 "USA-Variante" 0 "keine USA-Variante" ;
VAL_ 779 KBI_Konsistenz_ACC 1 "ACC_Botschaft_inkonsistent" 0 "ACC_Botschaft_konsistent" ;
VAL_ 779 KBI_Fehler_Anzeige_ACC 1 "Anzeigefehler_ACC" 0 "iO" ;
VAL_ 779 KBI_Einheit_Tacho 0 "km/h" 1 "mph" ;
VAL_ 779 KBI_KD_Fehler 1 "mind. ein KD-Fehler vorhanden" 0 "kein KD-Fehler" ;
VAL_ 779 KBI_Tankwarnung 1 "Tankwarnung aktiv" 0 "Tankwarnung nicht aktiv" ;
VAL_ 779 KBI_angez_Geschw 1023 "Fehlerwert" ;
VAL_ 779 KBI_Airbag_Lampe 1 "Leuchte an" 0 "Leuchte aus" ;
VAL_ 779 KBI_ABS_Lampe 1 "Leuchte an" 0 "Leuchte aus" ;
VAL_ 643 AB_Gurtwarn_HM 1 "Gurtwarnung auslösen" 0 "keine Warnung" ;
VAL_ 643 AB_Gurtwarn_HB 1 "Gurtwarnung auslösen" 0 "keine Warnung" ;
VAL_ 643 AB_Gurtwarn_HF 1 "Gurtwarnung auslösen" 0 "keine Warnung" ;
VAL_ 643 AB_PAO_Info 7 "AB BF akt.d.AWS,Schalt. a. AUTO" 6 "AB BF deakt.d.AWS,Schalt.a. AUTO" 5 "AB BF deakt.d.Schalt,AWS o.Einf." 4 "AB BF akt.d. AWS,kein Schalt.v." 3 "AB BF deakt.d.AWS,kein Schalt.v." 2 "AB BF akt.d.Schalt,kein AWS verb" 1 "AB BF deakt.d.Schalt,kein AWS v." 0 "Default / Initialwert" ;
VAL_ 643 AB_AWS_Zustand 7 "Fehler" 6 "Störung (Sitz verspannt)" 5 "schwerer Erwachsener" 4 "mittelschwerer Erwachsener" 3 "leichter Erwachener" 2 "Kind" 1 "Sitz leer" 0 "Default / Initialwert" ;
VAL_ 643 AB_Crashdaten 1 "Crashdaten gespeichert" 0 "keine Daten gespeichert" ;
VAL_ 643 AB_SF_URS 1 "Fehler" 0 "kein Fehler" ;
VAL_ 643 AB_SF_AWS 1 "Fehler" 0 "kein Fehler" ;
VAL_ 643 AB_W_AWS_S 1 "Störung AWS (Sitz verspannt)" 0 "keine Störung" ;
VAL_ 307 WHL_KD_Fehler 1 "mind. ein KD-Fehler vorhanden" 0 "kein KD-Fehler" ;
VAL_ 307 WHL_Magnet_Pos 3 "nicht definiert" 2 "aktive Magnetstellung" 1 "Zwischenstellung" 0 "passive Magnetstellung" ;
VAL_ 307 WHL_TipUp 1 "Aktiv" 0 "Inaktiv" ;
VAL_ 307 WHL_TipDown 1 "Aktiv" 0 "Inaktiv" ;
VAL_ 307 WHL_Pos 15 "Fehler" 14 "Manuellprog." 13 "kurzz. Manuellprog." 12 "frei" 11 "frei" 10 "frei" 9 "frei" 8 "Pos_P" 7 "Pos_R" 6 "Pos_N" 5 "Pos_D" 4 "Blinken_Pos_P" 3 "Blinken_Pos_R" 2 "Blinken_Pos_N" 1 "Blinken_Pos_D" 0 "Zwischenst." ;
VAL_ 1315 SVB_Aero 1 "SG verbaut" 0 "SG nicht verbaut" ;
VAL_ 1315 SVB_SCR 1 "SG verbaut" 0 "SG nicht verbaut" ;
VAL_ 1315 SVB_LEH_VA 1 "SG verbaut" 0 "SG nicht verbaut" ;
VAL_ 1315 SVB_Ladegeraet 1 "SG verbaut" 0 "SG nicht verbaut" ;
VAL_ 1315 SVB_EBKV 1 "SG verbaut" 0 "SG nicht verbaut" ;
VAL_ 1315 SVB_ComBox 1 "SG verbaut" 0 "SG nicht verbaut" ;
VAL_ 1315 SVB_Lift 0 "SG nicht verbaut" 1 "SG verbaut" ;
VAL_ 1315 SVB_HAL 1 "SG verbaut" 0 "SG nicht verbaut" ;
VAL_ 1315 SVB_Topview 1 "SG verbaut" 0 "SG nicht verbaut" ;
VAL_ 1315 SVB_Kamera 1 "SG verbaut" 0 "SG nicht verbaut" ;
VAL_ 1315 SVB_AFS 1 "SG verbaut" 0 "SG nicht verbaut" ;
VAL_ 1315 SVB_TSG_HR 1 "SG verbaut" 0 "SG nicht verbaut" ;
VAL_ 1315 SVB_CDR 1 "SG verbaut" 0 "SG nicht verbaut" ;
VAL_ 1315 SVB_Stoppuhr 1 "SG verbaut" 0 "SG nicht verbaut" ;
VAL_ 1315 SVB_SWR 1 "SG verbaut" 0 "SG nicht verbaut" ;
VAL_ 1315 SVB_HDSG 1 "SG verbaut" 0 "SG nicht verbaut" ;
VAL_ 1315 SVB_PDCC 1 "SG verbaut" 0 "SG nicht verbaut" ;
VAL_ 1315 SVB_EPB 1 "SG verbaut" 0 "SG nicht verbaut" ;
VAL_ 1315 SVB_QSP 1 "SG verbaut" 0 "SG nicht verbaut" ;
VAL_ 1315 SVB_PSM_Fwk 1 "SG verbaut" 0 "SG nicht verbaut" ;
VAL_ 1315 SVB_EPS 1 "SG verbaut" 0 "SG nicht verbaut" ;
VAL_ 1315 SVB_VSG 1 "SG verbaut" 0 "SG nicht verbaut" ;
VAL_ 1315 SVB_Allrad 1 "SG verbaut" 0 "SG nicht verbaut" ;
VAL_ 1315 SVB_TSG_HL 1 "SG verbaut" 0 "SG nicht verbaut" ;
VAL_ 1315 SVB_SWL 1 "SG verbaut" 0 "SG nicht verbaut" ;
VAL_ 1315 SVB_SSC 1 "SG verbaut" 0 "SG nicht verbaut" ;
VAL_ 1315 SVB_MEM_FS 1 "SG verbaut" 0 "SG nicht verbaut" ;
VAL_ 1315 SVB_MEM_BFS 1 "SG verbaut" 0 "SG nicht verbaut" ;
VAL_ 1315 SVB_WHL 1 "SG verbaut" 0 "SG nicht verbaut" ;
VAL_ 1315 SVB_TSG_BT 1 "SG verbaut" 0 "SG nicht verbaut" ;
VAL_ 1315 SVB_TSG_FT 1 "SG verbaut" 0 "SG nicht verbaut" ;
VAL_ 1315 SVB_AMP 1 "SG verbaut" 0 "SG nicht verbaut" ;
VAL_ 1315 SVB_BCM2 1 "SG verbaut" 0 "SG nicht verbaut" ;
VAL_ 1315 SVB_BCM1 1 "SG verbaut" 0 "SG nicht verbaut" ;
VAL_ 1315 SVB_RDK 1 "SG verbaut" 0 "SG nicht verbaut" ;
VAL_ 1315 SVB_PCM 1 "SG verbaut" 0 "SG nicht verbaut" ;
VAL_ 1315 SVB_Motor 1 "SG verbaut" 0 "SG nicht verbaut" ;
VAL_ 1315 SVB_TV 1 "SG verbaut" 0 "SG nicht verbaut" ;
VAL_ 1315 SVB_LWS 1 "SG verbaut" 0 "SG nicht verbaut" ;
VAL_ 1315 SVB_SMLS 1 "SG verbaut" 0 "SG nicht verbaut" ;
VAL_ 1315 SVB_Kombi 1 "SG verbaut" 0 "SG nicht verbaut" ;
VAL_ 1315 SVB_RearView 1 "SG verbaut" 0 "SG nicht verbaut" ;
VAL_ 1315 SVB_ACC 1 "SG verbaut" 0 "SG nicht verbaut" ;
VAL_ 1315 SVB_PDK 1 "SG verbaut" 0 "SG nicht verbaut" ;
VAL_ 1315 SVB_AAG 1 "SG verbaut" 0 "SG nicht verbaut" ;
VAL_ 1315 SVB_PSM_Ant 1 "SG verbaut" 0 "SG nicht verbaut" ;
VAL_ 1315 SVB_BKE 1 "SG verbaut" 0 "SG nicht verbaut" ;
VAL_ 1315 SVB_PASM_NRA 1 "SG verbaut" 0 "SG nicht verbaut" ;
VAL_ 1315 SVB_STH 1 "SG verbaut" 0 "SG nicht verbaut" ;
VAL_ 1315 SVB_Airbag 1 "SG verbaut" 0 "SG nicht verbaut" ;
VAL_ 1315 SVB_PDC 1 "SG verbaut" 0 "SG nicht verbaut" ;
VAL_ 1315 SVB_SWA 1 "SG verbaut" 0 "SG nicht verbaut" ;
VAL_ 1315 SVB_Kompass 1 "SG verbaut" 0 "SG nicht verbaut" ;
VAL_ 1315 SVB_EKK 1 "SG verbaut" 0 "SG nicht verbaut" ;
VAL_ 1315 SVB_EHPS 1 "SG verbaut" 0 "SG nicht verbaut" ;
VAL_ 1315 SVB_LEH 1 "SG verbaut" 0 "SG nicht verbaut" ;
VAL_ 1315 SVB_BMS 1 "SG verbaut" 0 "SG nicht verbaut" ;
VAL_ 390 BR_StartStopp_Info 3 "Systemfehler" 2 "Motoranlauf zwingend notwendig (Startanforderung)" 1 "Motoranlauf nicht zwingend notwendig (Stoppverbot, keine Startanforderung, evtl. Komforteinbussen)" 0 "Motorlauf langfristig nicht notwendig (Stoppfreigabe)" ;
VAL_ 390 BR_W_PDCC_Notlauf 1 "Warnmeldung" 0 "keine Warnmeldung" ;
VAL_ 390 BR_KD_Fehler 1 "mind. ein KD-Fehler vorhanden" 0 "kein KD-Fehler" ;
VAL_ 390 BR_St_Notbrems 1 "Notbremsung aktiv" 0 "Notbremsung nicht aktiv" ;
VAL_ 390 BR_Notbrems_verf 1 "verfuegbar" 0 "nicht verfuegbar" ;
VAL_ 390 BR_W_PTM_Temp 1 "Warnmeldung" 0 "keine Warnmeldung" ;
VAL_ 390 BR_F_Sport 1 "Fehler" 0 "kein Fehler" ;
VAL_ 390 BR_S_BremsT 3 "betätigt" 2 "unplausibel" 1 "Reserve" 0 "nicht betätigt" ;
VAL_ 390 BR_S_BremsL 3 "betätigt" 2 "unplausibel" 1 "Reserve" 0 "nicht betätigt" ;
VAL_ 390 BR_asrb 1 "Schaltverbot" 0 "keine_Beeinflussung" ;
VAL_ 390 BR_W_QSP_Temp 1 "Warnmeldung" 0 "keine Warnmeldung" ;
VAL_ 390 BR_St_Rollenmodus 1 "Aktiv" 0 "Inaktiv" ;
VAL_ 390 ESP_v_Signal 65534 "Init" 65533 "Unterspannung" 65535 "Fehler" ;
VAL_ 1981 Diag_Rs_PCItype_Waehlhebel 3 "FlowControl (FC)" 2 "ConsecutiveFrame (CF)" 1 "FirstFrame (FF)" 0 "SingleFrame (SF)" ;
VAL_ 910 AAG_Bremslicht_H_def 1 "Anhaenger Bremslicht defekt" ;
VAL_ 910 KBI_Fehler_Anzeige_ACC 1 "Anzeigefehler_ACC" 0 "iO" ;
VAL_ 910 KBI_Einheit_Tacho 0 "km/h" 1 "mph" ;
VAL_ 910 KBI_angez_Geschw 1023 "Fehlerwert" ;
VAL_ 910 F_Kombi_02_Ant 1 "veraltet" 0 "aktuell" ;
VAL_ 910 KBI_Aussen_Temp_gef 255 "Fehler" 254 "Init" 253 "nicht verbaut" ;
VAL_ 910 KBI_Inhalt_Tank 127 "Fehler" ;
VAL_ 910 F_Kombi_11_PAG_Ant 1 "veraltet" 0 "aktuell" ;
VAL_ 910 F_Klima_08_PAG_Ant 1 "veraltet" 0 "aktuell" ;
VAL_ 910 KL_Atemp_ungef 255 "Fehler" 0 "Initwert" ;
VAL_ 910 KBI_Tankwarnung 1 "Tankwarnung aktiv" 0 "Tankwarnung nicht aktiv" ;
VAL_ 910 F_Kombi_01_Ant 1 "veraltet" 0 "aktuell" ;
VAL_ 910 KBI_ABS_Lampe 1 "Leuchte an" 0 "Leuchte aus" ;
VAL_ 910 KBI_Airbag_Lampe 1 "Leuchte an" 0 "Leuchte aus" ;
VAL_ 910 F_Anhaenger_01_Ant 1 "veraltet" 0 "aktuell" ;
VAL_ 910 AAG_Anhaenger_erkannt 0 "kein Anhänger erkannt" 1 "AAG Anhänger erkannt" ;
VAL_ 787 F_PDCC_01_Ant 1 "veraltet" 0 "aktuell" ;
VAL_ 787 PDCC_Last_RKP 255 "Fehlerwert" 0 "Init" ;
VAL_ 787 ACC_05_alt 1 "veraltet" 0 "aktuell" ;
VAL_ 787 F_PCM_CDR_01_Ant 1 "veraltet" 0 "aktuell" ;
VAL_ 787 HU_Fotosensor 511 "Fehler" 510 "Init" 0 "Sensor unbeleuchtet" ;
VAL_ 787 BH_Blinker_re 1 "Blinkerhebel_Richtung_rechts_betaetigt" 0 "nicht_betaetigt" ;
VAL_ 787 BH_Blinker_li 1 "Blinkerhebel_Richtung_links_betaetigt" 0 "nicht_betaetigt" ;
VAL_ 787 F_Kombi_02_1_Ant 1 "veraltet" 0 "aktuell" ;
VAL_ 787 F_SMLS_01_Ant 1 "veraltet" 0 "aktuell" ;
SIG_GROUP_ 390 ESP_Momenteneingriff 1 : BR_mimsr BR_miasrs BR_miasrl BR_St_msr BR_St_asr;
